VERSION ""

NS_ :

BS_:

BU_: Bat1 OpticalSensor EMUS_BMS SCIMO_PE TelemetryNode Master SensorF SensorR BrakeF BrakeR PDU HVCU HVTU TestBench MDB1 MDB2 MDB3 MDB4 MDB5 MDB6 Track CLU

BO_ 57 CLU_TX_ActionRequest: 1 CLU
 SG_ CLU_TX_ActionRequest : 0|8@1+ (1,0) [0|255] "" Vector__XXX

BO_ 564 CLU_RX_ActionRequest: 1 SensorF
 SG_ CLU_RX_ActionRequest : 0|8@1+ (1,0) [0|255] ""  SensorF

BO_ 2165346838 BMS44_2_Frame: 8 Vector__XXX
 SG_ BMS44_2_FramePayload : 0|64@1+ (1,0) [0|0] ""  SensorF

BO_ 1792 CLU_RX_StatusLedControll: 1 SensorF
 SG_ CLU_RX_ErrorStatus : 0|1@1+ (1,0) [0|1] ""  CLU

BO_ 592 CLU_TX_LevitationState: 1 CLU
 SG_ CLU_LevitationState : 0|8@1+ (1,0) [0|255] ""  SensorF

BO_ 768 CLU_TX_CoolingState: 1 Vector__XXX
 SG_ CLU_RequiresCooling : 0|1@1+ (1,0) [0|1] ""  SensorF

BO_ 274 MDB3_RX_TargetAirGap: 4 CLU
 SG_ MDB3_TargetAirGap : 0|32@1+ (1,0) [0|0] "" Vector__XXX

BO_ 295 MDB6_RX_TargetAirGap: 4 CLU
 SG_ MDB6_TargetAirGap : 0|32@1+ (1,0) [0|0] "" Vector__XXX

BO_ 297 MDB6_TX_Temperature: 4 Vector__XXX
 SG_ MDB6_Temperature : 0|32@1+ (1,0) [0|0] ""  CLU

BO_ 294 MDB6_TX_AirGap: 4 Vector__XXX
 SG_ MDB6_TargetAirGap : 0|32@1+ (1,0) [0|0] ""  CLU

BO_ 293 MDB6_TX_State: 1 Vector__XXX
 SG_ MDB6_State : 0|8@1+ (1,0) [0|255] ""  CLU

BO_ 292 MDB5_TX_Temperature: 4 Vector__XXX
 SG_ MDB5_Temperature : 0|32@1+ (1,0) [0|0] ""  CLU

BO_ 290 MDB5_RX_TargetAirGap: 4 CLU
 SG_ MDB5_TargetAirGap : 0|32@1+ (1,0) [0|0] "" Vector__XXX

BO_ 289 MDB5_TX_AirGap: 4 Vector__XXX
 SG_ MDB5_AirGap : 0|32@1+ (1,0) [0|0] ""  CLU

BO_ 288 MDB5_TX_State: 1 Vector__XXX
 SG_ MDB5_State : 0|8@1+ (1,0) [0|255] ""  CLU

BO_ 281 MDB4_TX_Temperature: 4 Vector__XXX
 SG_ MDB4_Temperature : 0|32@1+ (1,0) [0|0] ""  CLU

BO_ 279 MDB4_RX_TargetAirGap: 4 CLU
 SG_ MDB4_TargetAirGap : 0|32@1+ (1,0) [0|0] "" Vector__XXX

BO_ 278 MDB4_TX_AirGap: 4 Vector__XXX
 SG_ MDB4_AirGap : 0|32@1+ (1,0) [0|0] ""  CLU

BO_ 277 MDB4_TX_State: 1 Vector__XXX
 SG_ MDB4_State : 0|8@1+ (1,0) [0|255] ""  CLU

BO_ 276 MDB3_TX_Temperature: 4 Vector__XXX
 SG_ MDB3_Temperature : 0|32@1+ (1,0) [0|0] ""  CLU

BO_ 273 MDB3_TX_AirGap: 4 Vector__XXX
 SG_ MDB3_AirGap : 0|32@1+ (1,0) [0|0] ""  CLU

BO_ 272 MDB3_TX_State: 1 Vector__XXX
 SG_ MDB3_State : 0|8@1+ (1,0) [0|255] ""  CLU

BO_ 265 MDB2_TX_Temperature: 4 Vector__XXX
 SG_ MDB2_Temperature : 0|32@1+ (1,0) [0|0] ""  CLU

BO_ 263 MDB2_RX_TargetAirGap: 4 CLU
 SG_ MDB2_TargetAirGap : 0|32@1+ (1,0) [0|0] "" Vector__XXX

BO_ 262 MDB2_TX_AirGap: 4 Vector__XXX
 SG_ MDB2_AirGap : 0|32@1+ (1,0) [0|0] ""  CLU

BO_ 261 MDB2_TX_State: 1 Vector__XXX
 SG_ MDB2_State : 0|8@1+ (1,0) [0|255] ""  CLU

BO_ 258 MDB1_RX_TargetAirGap: 4 CLU
 SG_ MDB1_TargetAirGap : 0|32@1+ (1,0) [0|0] "" Vector__XXX

BO_ 260 MDB1_TX_Temperature: 4 MDB3
 SG_ MDB1_Temperature : 0|32@1+ (1,0) [0|0] ""  CLU,SensorF

BO_ 257 MDB1_TX_AirGap: 4 MDB3
 SG_ MDB1_AirGap : 0|32@1+ (1,0) [0|0] ""  CLU

BO_ 1041 BrakeF_TX_PressureCooling: 2 BrakeF
 SG_ BrakeF_TX_Pressure_Reservoir : 0|12@1+ (0.005,-2) [-2|18.475] "bar"  SensorF

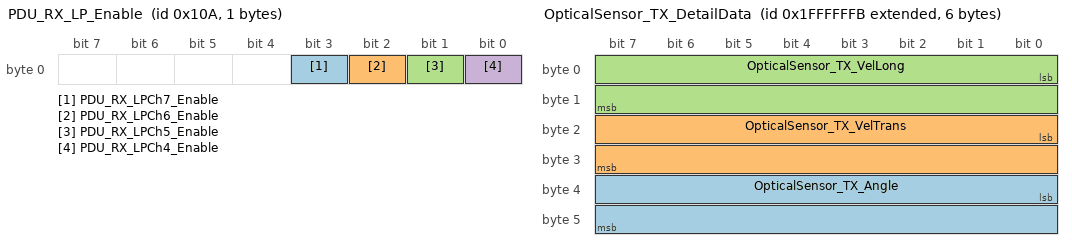
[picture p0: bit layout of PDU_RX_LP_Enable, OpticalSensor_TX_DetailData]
BO_ 266 PDU_RX_LP_Enable: 1 PDU
 SG_ PDU_RX_LPCh7_Enable : 3|1@1+ (1,0) [0|1] ""  SensorF
 SG_ PDU_RX_LPCh6_Enable : 2|1@1+ (1,0) [0|1] ""  SensorF
 SG_ PDU_RX_LPCh5_Enable : 1|1@1+ (1,0) [0|1] ""  SensorF
 SG_ PDU_RX_LPCh4_Enable : 0|1@1+ (1,0) [0|1] ""  SensorF

BO_ 2148592864 BMS44_1_Frame: 8 Bat1
 SG_ BMS44_1_FramePayload : 0|64@1+ (1,0) [0|0] ""  SensorF

BO_ 1 Track_TX_Respond: 1 Track
 SG_ Track_TX_Response : 0|8@1+ (1,0) [0|255] ""  SensorF

BO_ 0 Track_RX_Controll: 1 SensorF
 SG_ Track_RX_Command : 0|8@1+ (1,0) [0|255] "" Vector__XXX

BO_ 512 TEST_GROUND_STATION_CONTROLL: 1 Vector__XXX
 SG_ TEST_GROUND_STATION_COMMAND : 0|8@1+ (1,0) [0|255] ""  SensorF

BO_ 256 MDB1_TX_State: 1 MDB3
 SG_ MDB1_State : 0|8@1+ (1,0) [0|255] ""  CLU,SensorF

BO_ 450 SensorR_RX_POD1: 8 Vector__XXX

BO_ 2684354555 OpticalSensor_TX_DetailData: 6 OpticalSensor
 SG_ OpticalSensor_TX_Angle : 32|16@1- (0.01,0) [-45|45] "ï¿½" Vector__XXX
 SG_ OpticalSensor_TX_VelTrans : 16|16@1- (0.036,0) [-200|200] "km/h" Vector__XXX
 SG_ OpticalSensor_TX_VelLong : 0|16@1+ (0.036,0) [0|400] "km/h" Vector__XXX

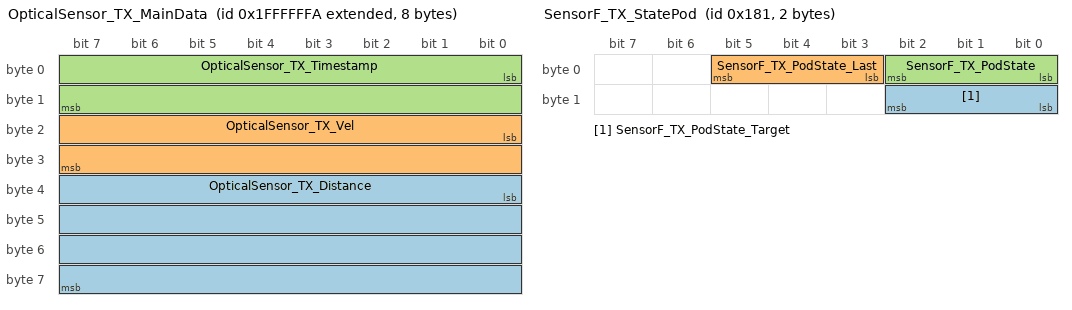
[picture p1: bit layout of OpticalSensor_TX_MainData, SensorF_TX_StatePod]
BO_ 2684354554 OpticalSensor_TX_MainData: 8 OpticalSensor
 SG_ OpticalSensor_TX_Distance : 32|32@1+ (0.001,0) [0|4294970] "m"  SensorF,SensorR
 SG_ OpticalSensor_TX_Vel : 16|16@1+ (0.036,0) [0|400] "km/h"  SensorF,SensorR
 SG_ OpticalSensor_TX_Timestamp : 0|16@1+ (1,0) [0|65535] ""  SensorF,SensorR

BO_ 2684354556 OpticalSensor_TX_Status: 8 OpticalSensor
 SG_ OpticalSensor_TX_VddOK : 62|1@1+ (1,0) [0|0] ""  SensorF
 SG_ OpticalSensor_TX_VeeOK : 61|1@1+ (1,0) [0|0] ""  SensorF
 SG_ OpticalSensor_TX_V33OK : 60|1@1+ (1,0) [0|0] ""  SensorF
 SG_ OpticalSensor_TX_V25OK : 59|1@1+ (1,0) [0|0] ""  SensorF
 SG_ OpticalSensor_TX_LEDStatus : 57|2@1+ (1,0) [0|0] ""  SensorF
 SG_ OpticalSensor_TX_LED_Cal : 56|1@1+ (1,0) [0|0] ""  SensorF
 SG_ OpticalSensor_TX_PowerOK : 55|1@1+ (1,0) [0|0] ""  SensorF
 SG_ OpticalSensor_TX_CurrentOK : 54|1@1+ (1,0) [0|0] ""  SensorF
 SG_ OpticalSensor_TX_CurrentLowHigh : 53|1@1+ (1,0) [0|0] ""  SensorF
 SG_ OpticalSensor_TX_OpticOK : 52|1@1+ (1,0) [0|0] ""  SensorF
 SG_ OpticalSensor_TX_TempOK : 51|1@1+ (1,0) [0|0] ""  SensorF
 SG_ OpticalSensor_TX_SensorOK : 50|1@1+ (1,0) [0|0] ""  SensorF
 SG_ OpticalSensor_TX_SelfTest : 49|1@1+ (1,0) [0|0] ""  SensorF
 SG_ OpticalSensor_TX_STST : 48|1@1+ (1,0) [0|0] ""  SensorF
 SG_ OpticalSensor_TX_LEDCurrent : 40|8@1+ (0.01,0) [0|2.55] "A"  SensorF
 SG_ OpticalSensor_TX_Temp : 32|8@1- (1,0) [-128|127] "ï¿½C"  SensorF
 SG_ OpticalSensor_TX_SensorNo : 24|8@1+ (1,0) [0|0] ""  SensorF
 SG_ OpticalSensor_TX_SerialNo : 0|24@1+ (1,0) [0|0] ""  SensorF

BO_ 2 CANzero_NMT: 4 Master
 SG_ CANzero_NMT_Node : 16|16@1+ (1,0) [0|63] ""  SensorF,SensorR,BrakeF,BrakeR,PDU,HVCU,HVTU,TelemetryNode,MDB1,MDB2,MDB3,MDB4,MDB5,MDB6,Track,CLU
 SG_ CANzero_NMT_State : 0|16@1+ (1,0) [0|0] ""  SensorF,SensorR,BrakeF,BrakeR,PDU,HVCU,HVTU,TelemetryNode,MDB1,MDB2,MDB3,MDB4,MDB5,MDB6,Track,CLU

BO_ 122 CANzero_Sync: 0 Master

BO_ 123 CANzero_Timestamp: 0 Master

BO_ 129 SensorF_EMCY: 4 SensorF
 SG_ SensorF_E14_fiducialHighOffset : 26|1@1+ (1,0) [0|0] ""  Master,TelemetryNode
 SG_ SensorF_E13_encoderSpeedError : 25|1@1+ (1,0) [0|0] ""  Master,TelemetryNode
 SG_ SensorF_E12_encoderError : 24|1@1+ (1,0) [0|0] ""  Master,TelemetryNode
 SG_ SensorF_E10_TelemEmergency : 22|1@1+ (1,0) [0|0] ""  Master,TelemetryNode
 SG_ SensorF_E9_SWError : 21|1@1+ (1,0) [0|0] ""  Master,TelemetryNode
 SG_ SensorF_E8_NodeErrorFlag : 20|1@1+ (1,0) [0|0] ""  Master,TelemetryNode
 SG_ SensorF_E7_TelemetryTimeout : 19|1@1+ (1,0) [0|0] ""  Master,TelemetryNode
 SG_ SensorF_E6_SensorRTimeout : 18|1@1+ (1,0) [0|0] ""  Master,TelemetryNode
 SG_ SensorF_E5_HVCUTimeout : 17|1@1+ (1,0) [0|0] ""  Master,TelemetryNode
 SG_ SensorF_E4_PDUTimeout : 16|1@1+ (1,0) [0|0] ""  Master,TelemetryNode
 SG_ SensorF_E3_BrakeRTimeout : 15|1@1+ (1,0) [0|0] ""  Master,TelemetryNode
 SG_ SensorF_E2_BrakeFTimeout : 14|1@1+ (1,0) [0|0] ""  Master,TelemetryNode
 SG_ SensorF_E1_StateMTransitionE : 13|1@1+ (1,0) [0|0] ""  Master,TelemetryNode
 SG_ SensorF_E0_OtherError : 12|1@1+ (1,0) [0|0] ""  Master,TelemetryNode
 SG_ SensorF_W2_encoderOORWarning : 2|1@1+ (1,0) [0|0] ""  Master,TelemetryNode
 SG_ SensorF_W1_StateMTransitionW : 1|1@1+ (1,0) [0|0] ""  Master,TelemetryNode
 SG_ SensorF_W0_OtherWarning : 0|1@1+ (1,0) [0|0] ""  Master,TelemetryNode

BO_ 385 SensorF_TX_StatePod: 2 SensorF
 SG_ SensorF_TX_PodState_Target : 8|3@1+ (1,0) [0|0] ""  CLU,Track,BrakeF,PDU
 SG_ SensorF_TX_PodState_Last : 3|3@1+ (1,0) [0|0] ""  CLU,Track,BrakeF,PDU
 SG_ SensorF_TX_PodState : 0|3@1+ (1,0) [0|0] ""  CLU,Track,BrakeF,PDU

BO_ 449 SensorF_RX_PDO1: 0 Vector__XXX

BO_ 513 SensorF_TX_FSMTransitions: 4 SensorF
 SG_ SensorF_TX_PreopHVCUT : 24|1@1+ (1,0) [0|0] "" Vector__XXX
 SG_ SensorF_TX_PreopPDUT : 16|1@1+ (1,0) [0|0] "" Vector__XXX
 SG_ SensorF_TX_PreopBrakeRT : 15|1@1+ (1,0) [0|0] "" Vector__XXX
 SG_ SensorF_TX_PreopBrakeFT : 14|1@1+ (1,0) [0|0] "" Vector__XXX
 SG_ SensorF_TX_PreopSensorRT : 13|1@1+ (1,0) [0|0] "" Vector__XXX
 SG_ SensorF_TX_EnableSensorRT : 12|1@1+ (1,0) [0|0] "" Vector__XXX
 SG_ SensorF_TX_EnablePDUT : 11|1@1+ (1,0) [0|0] "" Vector__XXX
 SG_ SensorF_TX_EnableHVCUT : 10|1@1+ (1,0) [0|0] "" Vector__XXX
 SG_ SensorF_TX_EnableBrakeRT : 9|1@1+ (1,0) [0|0] "" Vector__XXX
 SG_ SensorF_TX_EnableBrakeFT : 8|1@1+ (1,0) [0|0] "" Vector__XXX
 SG_ SensorF_TX_SetHVTransition : 7|1@1+ (1,0) [0|0] "" Vector__XXX
 SG_ SensorF_TX_PreopTransition : 6|1@1+ (1,0) [0|0] "" Vector__XXX
 SG_ SensorF_TX_LaunchStartTransition : 5|1@1+ (1,0) [0|0] "" Vector__XXX
 SG_ SensorF_TX_LaunchSetupTransition : 4|1@1+ (1,0) [0|0] "" Vector__XXX
 SG_ SensorF_TX_HWEnableTransition : 3|1@1+ (1,0) [0|0] "" Vector__XXX
 SG_ SensorF_TX_ErrorResetTransition : 2|1@1+ (1,0) [0|0] "" Vector__XXX
 SG_ SensorF_TX_EnableTransition : 1|1@1+ (1,0) [0|0] "" Vector__XXX
 SG_ SensorF_TX_BrakesTransition : 0|1@1+ (1,0) [0|0] "" Vector__XXX

BO_ 577 SensorF_RX_PDO2: 0 Vector__XXX

BO_ 641 SensorF_TX_PDO3: 0 SensorF

BO_ 705 SensorF_RX_PDO3: 0 Vector__XXX

BO_ 769 SensorF_TX_PDO4: 0 SensorF

BO_ 833 SensorF_RX_PDO4: 0 Vector__XXX

BO_ 897 SensorF_TX_PDO5: 0 SensorF

BO_ 961 SensorF_TX_PDO6: 0 SensorF

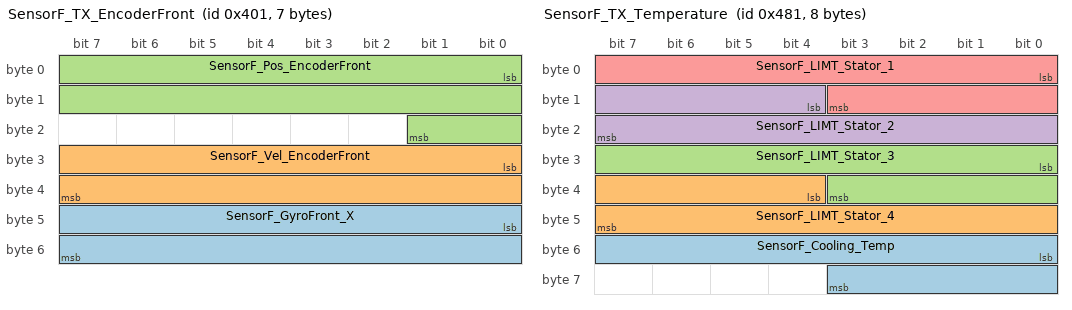
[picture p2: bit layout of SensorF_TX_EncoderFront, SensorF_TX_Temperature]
BO_ 1025 SensorF_TX_EncoderFront: 7 SensorF
 SG_ SensorF_GyroFront_X : 40|16@1- (0.017,0) [-557.056|557.039] "Â°/s"  SensorR
 SG_ SensorF_Vel_EncoderFront : 24|16@1- (0.002,0) [-65.536|65.534] "m/s"  SensorR
 SG_ SensorF_Pos_EncoderFront : 0|18@1- (0.005,0) [-655.36|655.355] "m"  SensorR

BO_ 1089 SensorF_TX_BMS: 2 SensorF
 SG_ SensorF_TX_BatteryTemp : 0|12@1+ (0.05,-30) [-30|174.75] "C"  PDU

BO_ 1153 SensorF_TX_Temperature: 8 SensorF
 SG_ SensorF_Cooling_Temp : 48|12@1+ (0.05,-30) [-30|174.75] "C"  PDU
 SG_ SensorF_LIMT_Stator_4 : 36|12@1+ (0.075,-20) [-20|287.125] "ï¿½C" Vector__XXX
 SG_ SensorF_LIMT_Stator_3 : 24|12@1+ (0.075,-20) [-20|287.125] "ï¿½C" Vector__XXX
 SG_ SensorF_LIMT_Stator_2 : 12|12@1+ (0.075,-20) [-20|287.125] "ï¿½C" Vector__XXX
 SG_ SensorF_LIMT_Stator_1 : 0|12@1+ (0.075,-20) [-20|287.125] "ï¿½C" Vector__XXX

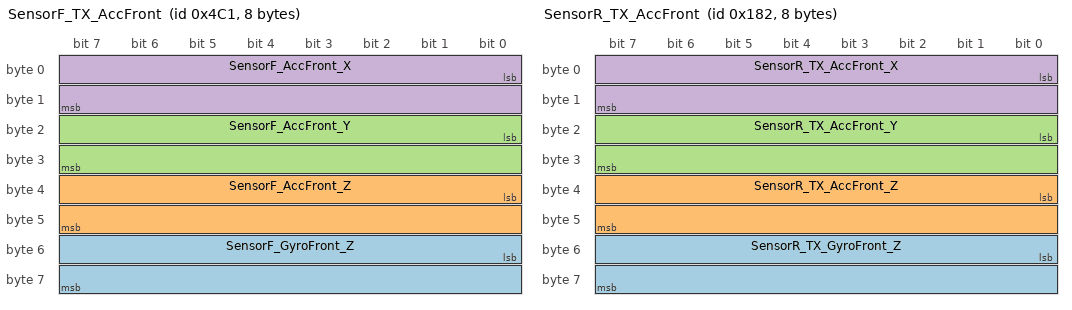
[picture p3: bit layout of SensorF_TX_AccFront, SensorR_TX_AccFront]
BO_ 1217 SensorF_TX_AccFront: 8 SensorF
 SG_ SensorF_GyroFront_Z : 48|16@1- (0.017,0) [-557.056|557.039] "Â°/s"  SensorR
 SG_ SensorF_AccFront_Z : 32|16@1- (0.00125,0) [-40.96|40.95875] "m/s^2"  SensorR
 SG_ SensorF_AccFront_Y : 16|16@1- (0.00125,0) [-40.96|40.95875] "m/s^2"  SensorR
 SG_ SensorF_AccFront_X : 0|16@1- (0.00125,0) [-40.96|40.95875] "m/s^2"  SensorR

BO_ 1281 SensorF_TX_PDO11: 0 SensorF

BO_ 1345 SensorF_TX_PDO12: 0 SensorF

BO_ 1409 SensorF_SDO_Resp: 8 SensorF
 SG_ SensorF_OD_SetReset m2320 : 16|8@1+ (1,0) [0|255] ""  TelemetryNode
 SG_ SensorF_OD_Velocity m3329 : 16|16@1+ (0.01,-100) [-100|555.35] ""  TelemetryNode
 SG_ SensorF_OD_Position m3328 : 16|16@1+ (0.01,-100) [-100|555.35] ""  TelemetryNode
 SG_ SensorF_OD_StripeCount m3072 : 16|16@1+ (1,0) [0|65535] ""  TelemetryNode
 SG_ SensorF_OD_MdbState m2832 : 16|8@1+ (1,0) [0|255] ""  TelemetryNode
 SG_ SensorF_OD_Magnet_6_Temperature m2824 : 16|16@1+ (0.01,-100) [-100|555.35] ""  TelemetryNode
 SG_ SensorF_OD_Magnet_5_Temperature m2823 : 16|16@1+ (0.01,-100) [-100|555.35] ""  TelemetryNode
 SG_ SensorF_OD_Magnet_4_Temperature m2822 : 16|16@1+ (0.01,-100) [-100|555.35] ""  TelemetryNode
 SG_ SensorF_OD_Magnet_3_Temperature m2821 : 16|16@1+ (0.01,-100) [-100|555.35] ""  TelemetryNode
 SG_ SensorF_OD_Magnet_2_Temperature m2820 : 16|16@1+ (0.01,-100) [-100|555.35] ""  TelemetryNode
 SG_ SensorF_OD_Magnet_1_Temperature m2818 : 16|16@1+ (0.01,-100) [-100|555.35] ""  TelemetryNode
 SG_ SensorF_OD_ReservoirTemperature m2817 : 16|16@1+ (0.01,-100) [-100|555.35] ""  TelemetryNode
 SG_ SensorF_OD_CoolingPressure m2816 : 16|16@1+ (0.01,-100) [-100|555.35] ""  TelemetryNode
 SG_ SensorF_OD_IMU_GyroZ m2611 : 16|16@1+ (0.01,-100) [-100|555.35] ""  TelemetryNode
 SG_ SensorF_OD_IMU_GyroY m2610 : 16|16@1+ (0.01,-100) [-100|555.35] ""  TelemetryNode
 SG_ SensorF_OD_IMU_GyroX m2609 : 16|16@1+ (0.01,-100) [-100|555.35] ""  TelemetryNode
 SG_ SensorF_OD_IMU_AccelZ m2608 : 16|16@1+ (0.01,-100) [-100|555.35] ""  TelemetryNode
 SG_ SensorF_OD_IMU_AccelY m2601 : 16|16@1+ (0.01,-100) [-100|555.35] ""  TelemetryNode
 SG_ SensorF_OD_IMU_AccelX m2600 : 16|16@1+ (0.01,-100) [-100|555.35] ""  TelemetryNode
 SG_ SensorF_OD_IMU3_Temperature m2599 : 16|16@1+ (0.01,-100) [-100|555.35] ""  TelemetryNode
 SG_ SensorF_OD_IMU2_Temperature m2598 : 16|16@1+ (0.01,-100) [-100|555.35] ""  TelemetryNode
 SG_ SensorF_OD_IMU1_Temperature m2597 : 16|16@1+ (0.01,-100) [-100|555.35] ""  TelemetryNode
 SG_ SensorF_OD_IMU_number m2592 : 16|8@1+ (1,0) [0|255] ""  TelemetryNode
 SG_ SensorF_OD_EncoderResetPosition m2309 : 16|8@1+ (1,0) [0|255] ""  TelemetryNode
 SG_ SensorF_OD_EncoderWheelDiameter m2308 : 16|16@1+ (0.005,0) [1|300] "mm"  TelemetryNode
 SG_ SensorF_OD_HVBatteryMode m2307 : 16|8@1+ (1,0) [0|255] ""  TelemetryNode
 SG_ SensorF_OD_StateMachineActivate m2306 : 16|8@1+ (1,0) [0|255] ""  TelemetryNode
 SG_ SensorF_OD_StateMachineInterval m2305 : 16|8@1+ (1,0) [5|100] "ms"  TelemetryNode
 SG_ SensorF_OD_TelemetryCommands m2304 : 16|8@1+ (1,0) [0|255] ""  TelemetryNode
 SG_ SensorF_OD_samplingInterval m2048 : 16|16@1+ (0.01,0) [0.01|100] "ms"  TelemetryNode
 SG_ SensorF_OD_CAN2_DelayedTxMessage m1129 : 16|24@1+ (1,0) [0|16777215] ""  TelemetryNode
 SG_ SensorF_OD_CAN2_ErrorStatus m1128 : 16|8@1+ (1,0) [0|255] ""  TelemetryNode
 SG_ SensorF_OD_CAN2_DiscardedTxMessa m1127 : 16|24@1+ (1,0) [0|16777215] ""  TelemetryNode
 SG_ SensorF_OD_CAN2_Status m1126 : 16|8@1+ (1,0) [0|255] ""  TelemetryNode
 SG_ SensorF_OD_CAN2_Baudrate m1124 : 16|16@1+ (1,0) [125|1000] "kbps"  TelemetryNode
 SG_ SensorF_OD_CAN2_autoErrorReset m1123 : 16|8@1+ (1,0) [0|255] ""  TelemetryNode
 SG_ SensorF_OD_CAN2_lastErrorCode m1122 : 16|32@1+ (1,0) [0|4294967295] ""  TelemetryNode
 SG_ SensorF_OD_CAN2_RxErrCnt m1121 : 16|8@1+ (1,0) [0|255] ""  TelemetryNode
 SG_ SensorF_OD_CAN2_TxErrCnt m1120 : 16|8@1+ (1,0) [0|255] ""  TelemetryNode
 SG_ SensorF_OD_CAN1_DelayedTxMessage m1113 : 16|24@1+ (1,0) [0|16777215] ""  TelemetryNode
 SG_ SensorF_OD_CAN1_ErrorStatus m1112 : 16|8@1+ (1,0) [0|255] ""  TelemetryNode
 SG_ SensorF_OD_CAN1_DiscardedTxMessa m1111 : 16|24@1+ (1,0) [0|16777215] ""  TelemetryNode
 SG_ SensorF_OD_CAN1_Status m1110 : 16|8@1+ (1,0) [0|255] ""  TelemetryNode
 SG_ SensorF_OD_CAN1_Baudrate m1108 : 16|16@1+ (1,0) [125|1000] "kbps"  TelemetryNode
 SG_ SensorF_OD_CAN1_autoErrorReset m1107 : 16|8@1+ (1,0) [0|255] ""  TelemetryNode
 SG_ SensorF_OD_CAN1_lastErrorCode m1106 : 16|32@1+ (1,0) [0|4294967295] ""  TelemetryNode
 SG_ SensorF_OD_CAN1_RxErrCnt m1105 : 16|8@1+ (1,0) [0|255] ""  TelemetryNode
 SG_ SensorF_OD_CAN1_TxErrCnt m1104 : 16|8@1+ (1,0) [0|255] ""  TelemetryNode
 SG_ SensorF_OD_BuildTime m1073 : 16|24@1+ (1,0) [0|16777215] ""  TelemetryNode
 SG_ SensorF_OD_BuildDate m1072 : 16|32@1+ (1,0) [0|4294967295] ""  TelemetryNode
 SG_ SensorF_OD_ChipUID2 m1057 : 16|48@1+ (1,0) [0|281474976710655] ""  TelemetryNode
 SG_ SensorF_OD_ChipUID1 m1056 : 16|48@1+ (1,0) [0|281474976710655] ""  TelemetryNode
 SG_ SensorF_OD_SdcOut m1046 : 16|8@1+ (1,0) [0|255] ""  TelemetryNode
 SG_ SensorF_OD_SdcIn m1045 : 16|8@1+ (1,0) [0|255] ""  TelemetryNode
 SG_ SensorF_OD_runtime m1044 : 16|24@1+ (1,0) [0|16777215] "ms"  TelemetryNode
 SG_ SensorF_OD_InputVoltage m1043 : 16|16@1+ (0.001,0) [0|65.535] "V"  TelemetryNode
 SG_ SensorF_OD_BoardTemp m1042 : 16|16@1+ (0.01,-30) [-30|625.35] "°C"  TelemetryNode
 SG_ SensorF_OD_MemFree m1041 : 16|16@1+ (4,0) [0|262140] "bytes"  TelemetryNode
 SG_ SensorF_OD_CpuUsage m1040 : 16|8@1+ (0.5,0) [0|100] "%"  TelemetryNode
 SG_ SensorF_OD_OdEntrySendInterval m33 : 16|16@1+ (1,0) [0|65535] "ms"  TelemetryNode
 SG_ SensorF_OD_SendOdOnBootup m32 : 16|8@1+ (1,0) [0|255] ""  TelemetryNode
 SG_ SensorF_OD_HeartbeatInterval m16 : 16|16@1+ (1,0) [0|65535] "ms"  TelemetryNode
 SG_ SensorF_OD_DbcVersion m5 : 16|16@1+ (1,0) [0|65535] ""  TelemetryNode
 SG_ SensorF_OD_StackVersion m4 : 16|16@1+ (1,0) [0|65535] ""  TelemetryNode
 SG_ SensorF_OD_ProtocolVersion m3 : 16|16@1+ (1,0) [0|65535] ""  TelemetryNode
 SG_ SensorF_OD_NodeStatus m2 : 16|8@1+ (1,0) [0|255] ""  TelemetryNode
 SG_ SensorF_OD_NodeID m1 : 16|8@1+ (1,0) [0|255] ""  TelemetryNode
 SG_ SensorF_SDO_RespCode : 12|4@1+ (1,0) [0|0] ""  TelemetryNode
 SG_ SensorF_SDO_ID M : 0|12@1+ (1,0) [0|4095] ""  TelemetryNode

BO_ 1473 SensorF_SDO_Req_Up: 8 TelemetryNode
 SG_ SensorF_OD_SetReset m2320 : 16|8@1+ (1,0) [0|255] ""  SensorF
 SG_ SensorF_OD_Velocity m3329 : 16|16@1+ (0.01,-100) [-100|555.35] ""  SensorF
 SG_ SensorF_OD_Position m3328 : 16|16@1+ (0.01,-100) [-100|555.35] ""  SensorF
 SG_ SensorF_OD_StripeCount m3072 : 16|16@1+ (1,0) [0|65535] ""  SensorF
 SG_ SensorF_OD_MdbState m2832 : 16|8@1+ (1,0) [0|255] ""  SensorF
 SG_ SensorF_OD_Magnet_6_Temperature m2824 : 16|16@1+ (0.01,-100) [-100|555.35] ""  SensorF
 SG_ SensorF_OD_Magnet_5_Temperature m2823 : 16|16@1+ (0.01,-100) [-100|555.35] ""  SensorF
 SG_ SensorF_OD_Magnet_4_Temperature m2822 : 16|16@1+ (0.01,-100) [-100|555.35] ""  SensorF
 SG_ SensorF_OD_Magnet_3_Temperature m2821 : 16|16@1+ (0.01,-100) [-100|555.35] ""  SensorF
 SG_ SensorF_OD_Magnet_2_Temperature m2820 : 16|16@1+ (0.01,-100) [-100|555.35] ""  SensorF
 SG_ SensorF_OD_Magnet_1_Temperature m2818 : 16|16@1+ (0.01,-100) [-100|555.35] ""  SensorF
 SG_ SensorF_OD_ReservoirTemperature m2817 : 16|16@1+ (0.01,-100) [-100|555.35] ""  SensorF
 SG_ SensorF_OD_CoolingPressure m2816 : 16|16@1+ (0.01,-100) [-100|555.35] ""  SensorF
 SG_ SensorF_OD_IMU_GyroZ m2611 : 16|16@1+ (0.01,-100) [-100|555.35] ""  SensorF
 SG_ SensorF_OD_IMU_GyroY m2610 : 16|16@1+ (0.01,-100) [-100|555.35] ""  SensorF
 SG_ SensorF_OD_IMU_GyroX m2609 : 16|16@1+ (0.01,-100) [-100|555.35] ""  SensorF
 SG_ SensorF_OD_IMU_AccelZ m2608 : 16|16@1+ (0.01,-100) [-100|555.35] ""  SensorF
 SG_ SensorF_OD_IMU_AccelY m2601 : 16|16@1+ (0.01,-100) [-100|555.35] ""  SensorF
 SG_ SensorF_OD_IMU_AccelX m2600 : 16|16@1+ (0.01,-100) [-100|555.35] ""  SensorF
 SG_ SensorF_OD_IMU3_Temperature m2599 : 16|16@1+ (0.01,-100) [-100|555.35] ""  SensorF
 SG_ SensorF_OD_IMU2_Temperature m2598 : 16|16@1+ (0.01,-100) [-100|555.35] ""  SensorF
 SG_ SensorF_OD_IMU1_Temperature m2597 : 16|16@1+ (0.01,-100) [-100|555.35] ""  SensorF
 SG_ SensorF_OD_IMU_number m2592 : 16|8@1+ (1,0) [0|255] ""  SensorF
 SG_ SensorF_OD_EncoderResetPosition m2309 : 16|8@1+ (1,0) [0|255] ""  SensorF
 SG_ SensorF_OD_EncoderWheelDiameter m2308 : 16|16@1+ (0.005,0) [1|300] "mm"  SensorF
 SG_ SensorF_OD_HVBatteryMode m2307 : 16|8@1+ (1,0) [0|255] ""  SensorF
 SG_ SensorF_OD_StateMachineActivate m2306 : 16|8@1+ (1,0) [0|255] ""  SensorF
 SG_ SensorF_OD_StateMachineInterval m2305 : 16|8@1+ (1,0) [5|100] "ms"  SensorF
 SG_ SensorF_OD_TelemetryCommands m2304 : 16|8@1+ (1,0) [0|255] ""  SensorF
 SG_ SensorF_OD_samplingInterval m2048 : 16|16@1+ (0.01,0) [0.01|100] "ms"  SensorF
 SG_ SensorF_OD_CAN2_DelayedTxMe_0000 m1129 : 16|24@1+ (1,0) [0|16777215] ""  SensorF
 SG_ SensorF_OD_CAN2_ErrorStatus m1128 : 16|8@1+ (1,0) [0|255] ""  SensorF
 SG_ SensorF_OD_CAN2_DiscardedTx_0000 m1127 : 16|24@1+ (1,0) [0|16777215] ""  SensorF
 SG_ SensorF_OD_CAN2_Status m1126 : 16|8@1+ (1,0) [0|255] ""  SensorF
 SG_ SensorF_OD_CAN2_Baudrate m1124 : 16|16@1+ (1,0) [125|1000] "kbps"  SensorF
 SG_ SensorF_OD_CAN2_autoErrorReset m1123 : 16|8@1+ (1,0) [0|255] ""  SensorF
 SG_ SensorF_OD_CAN2_lastErrorCode m1122 : 16|32@1+ (1,0) [0|4294967295] ""  SensorF
 SG_ SensorF_OD_CAN2_RxErrCnt m1121 : 16|8@1+ (1,0) [0|255] ""  SensorF
 SG_ SensorF_OD_CAN2_TxErrCnt m1120 : 16|8@1+ (1,0) [0|255] ""  SensorF
 SG_ SensorF_OD_CAN1_DelayedTxMe_0000 m1113 : 16|24@1+ (1,0) [0|16777215] ""  SensorF
 SG_ SensorF_OD_CAN1_ErrorStatus m1112 : 16|8@1+ (1,0) [0|255] ""  SensorF
 SG_ SensorF_OD_CAN1_DiscardedTx_0000 m1111 : 16|24@1+ (1,0) [0|16777215] ""  SensorF
 SG_ SensorF_OD_CAN1_Status m1110 : 16|8@1+ (1,0) [0|255] ""  SensorF
 SG_ SensorF_OD_CAN1_Baudrate m1108 : 16|16@1+ (1,0) [125|1000] "kbps"  SensorF
 SG_ SensorF_OD_CAN1_autoErrorReset m1107 : 16|8@1+ (1,0) [0|255] ""  SensorF
 SG_ SensorF_OD_CAN1_lastErrorCode m1106 : 16|32@1+ (1,0) [0|4294967295] ""  SensorF
 SG_ SensorF_OD_CAN1_RxErrCnt m1105 : 16|8@1+ (1,0) [0|255] ""  SensorF
 SG_ SensorF_OD_CAN1_TxErrCnt m1104 : 16|8@1+ (1,0) [0|255] ""  SensorF
 SG_ SensorF_OD_BuildTime m1073 : 16|24@1+ (1,0) [0|16777215] ""  SensorF
 SG_ SensorF_OD_BuildDate m1072 : 16|32@1+ (1,0) [0|4294967295] ""  SensorF
 SG_ SensorF_OD_ChipUID2 m1057 : 16|48@1+ (1,0) [0|281474976710655] ""  SensorF
 SG_ SensorF_OD_ChipUID1 m1056 : 16|48@1+ (1,0) [0|281474976710655] ""  SensorF
 SG_ SensorF_OD_SdcOut m1046 : 16|8@1+ (1,0) [0|255] ""  SensorF
 SG_ SensorF_OD_SdcIn m1045 : 16|8@1+ (1,0) [0|255] ""  SensorF
 SG_ SensorF_OD_runtime m1044 : 16|24@1+ (1,0) [0|16777215] "ms"  SensorF
 SG_ SensorF_OD_InputVoltage m1043 : 16|16@1+ (0.001,0) [0|65.535] "V"  SensorF
 SG_ SensorF_OD_BoardTemp m1042 : 16|16@1+ (0.01,-30) [-30|625.35] "°C"  SensorF
 SG_ SensorF_OD_MemFree m1041 : 16|16@1+ (4,0) [0|262140] "bytes"  SensorF
 SG_ SensorF_OD_CpuUsage m1040 : 16|8@1+ (0.5,0) [0|100] "%"  SensorF
 SG_ SensorF_OD_OdEntrySendInterval m33 : 16|16@1+ (1,0) [0|65535] "ms"  SensorF
 SG_ SensorF_OD_SendOdOnBootup m32 : 16|8@1+ (1,0) [0|255] ""  SensorF
 SG_ SensorF_OD_HeartbeatInterval m16 : 16|16@1+ (1,0) [0|65535] "ms"  SensorF
 SG_ SensorF_OD_DbcVersion m5 : 16|16@1+ (1,0) [0|65535] ""  SensorF
 SG_ SensorF_OD_StackVersion m4 : 16|16@1+ (1,0) [0|65535] ""  SensorF
 SG_ SensorF_OD_ProtocolVersion m3 : 16|16@1+ (1,0) [0|65535] ""  SensorF
 SG_ SensorF_OD_NodeStatus m2 : 16|8@1+ (1,0) [0|255] ""  SensorF
 SG_ SensorF_OD_NodeID m1 : 16|8@1+ (1,0) [0|255] ""  SensorF
 SG_ SensorF_SDO_ID M : 0|12@1+ (1,0) [0|4095] ""  SensorF

BO_ 1537 SensorF_SDO_Req_Down: 2 TelemetryNode
 SG_ SensorF_SDO_ID M : 0|12@1+ (1,0) [0|4095] ""  SensorF

BO_ 1793 SensorF_Heartbeat: 1 SensorF
 SG_ SensorF_NodeState : 0|8@1+ (1,0) [0|0] ""  SensorF,Master,TelemetryNode

BO_ 1857 SensorF_BTL_TX: 8 SensorF

BO_ 1921 SensorF_BTL_RX: 8 TelemetryNode

BO_ 130 SensorR_EMCY: 4 SensorR
 SG_ SensorR_E12_highLIMTemperature : 24|1@1+ (1,0) [0|0] ""  Master,TelemetryNode
 SG_ SensorR_E11_scimoPEerror101overc : 23|1@1+ (1,0) [0|0] ""  Master,TelemetryNode
 SG_ SensorR_E10_scimoPEerror103sumcu : 22|1@1+ (1,0) [0|0] ""  Master,TelemetryNode
 SG_ SensorR_E9_scimoPEerror102overcu : 21|1@1+ (1,0) [0|0] ""  Master,TelemetryNode
 SG_ SensorR_E8_scimoPEerror024motTem : 20|1@1+ (1,0) [0|0] ""  Master,TelemetryNode
 SG_ SensorR_E7_scimoPEerror020uZKmin : 19|1@1+ (1,0) [0|0] ""  Master,TelemetryNode
 SG_ SensorR_E6_scimoPEerror009Pulslo : 18|1@1+ (1,0) [0|0] ""  Master,TelemetryNode
 SG_ SensorR_E5_accEmergencyStop : 17|1@1+ (1,0) [0|0] ""  Master,TelemetryNode
 SG_ SensorR_E4_velEmergencyStop : 16|1@1+ (1,0) [0|0] ""  Master,TelemetryNode
 SG_ SensorR_E3_posEmergencyStop : 15|1@1+ (1,0) [0|0] ""  Master,TelemetryNode
 SG_ SensorR_E2_stripeEmergencyStop : 14|1@1+ (1,0) [0|0] ""  Master,TelemetryNode
 SG_ SensorR_E1_trajectoryError : 13|1@1+ (1,0) [0|0] ""  Master,TelemetryNode
 SG_ SensorR_E0_OtherError : 12|1@1+ (1,0) [0|0] ""  Master,TelemetryNode
 SG_ SensorR_W10_highLIMTemperature : 10|1@1+ (1,0) [0|0] ""  Master,TelemetryNode
 SG_ SensorR_W9_restrictingVelocity : 9|1@1+ (1,0) [0|0] ""  Master,TelemetryNode
 SG_ SensorR_W8_outOfLimModelBoundari : 8|1@1+ (1,0) [0|0] ""  Master,TelemetryNode
 SG_ SensorR_W7_highOscillations : 7|1@1+ (1,0) [0|0] ""  Master,TelemetryNode
 SG_ SensorR_W6_sciMoPEwarning104FETt : 6|1@1+ (1,0) [0|0] ""  Master,TelemetryNode
 SG_ SensorR_W5_sciMoPEwarning069CPUt : 5|1@1+ (1,0) [0|0] ""  Master,TelemetryNode
 SG_ SensorR_W4_stateEstimationAccWar : 4|1@1+ (1,0) [0|0] ""  Master,TelemetryNode
 SG_ SensorR_W3_stateEstimationPosWar : 3|1@1+ (1,0) [0|0] ""  Master,TelemetryNode
 SG_ SensorR_W2_stateEstimationVelWar : 2|1@1+ (1,0) [0|0] ""  Master,TelemetryNode
 SG_ SensorR_W1_stripeWarning : 1|1@1+ (1,0) [0|0] ""  Master,TelemetryNode
 SG_ SensorR_W0_OtherWarning : 0|1@1+ (1,0) [0|0] ""  Master,TelemetryNode

BO_ 386 SensorR_TX_AccFront: 8 SensorR
 SG_ SensorR_TX_GyroFront_Z : 48|16@1- (0.017,0) [-557.056|557.039] "Â°/s" Vector__XXX
 SG_ SensorR_TX_AccFront_Z : 32|16@1- (0.00125,0) [-40.96|40.95875] "m/s^2" Vector__XXX
 SG_ SensorR_TX_AccFront_Y : 16|16@1- (0.00125,0) [-40.96|40.95875] "m/s^2" Vector__XXX
 SG_ SensorR_TX_AccFront_X : 0|16@1- (0.00125,0) [-40.96|40.95875] "m/s^2" Vector__XXX

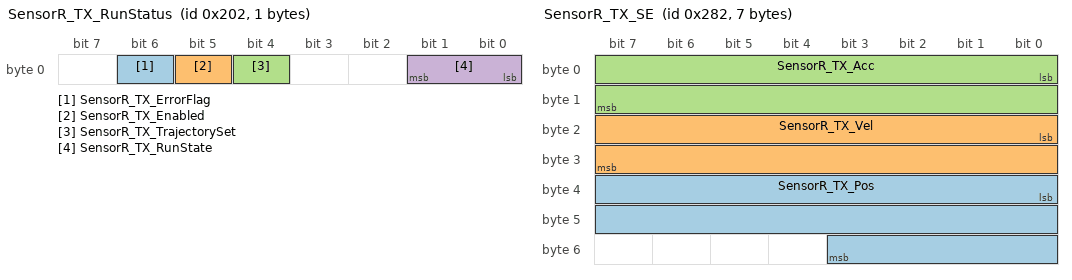
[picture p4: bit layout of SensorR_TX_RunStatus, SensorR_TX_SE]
BO_ 514 SensorR_TX_RunStatus: 1 SensorR
 SG_ SensorR_TX_ErrorFlag : 6|1@1+ (1,0) [0|0] "" Vector__XXX
 SG_ SensorR_TX_Enabled : 5|1@1+ (1,0) [0|0] "" Vector__XXX
 SG_ SensorR_TX_TrajectorySet : 4|1@1+ (1,0) [0|0] "" Vector__XXX
 SG_ SensorR_TX_RunState : 0|2@1+ (1,0) [0|0] ""  PDU

BO_ 578 SensorR_RX_PDO2: 0 Vector__XXX

BO_ 642 SensorR_TX_SE: 7 SensorR
 SG_ SensorR_TX_Pos : 32|20@1- (0.001,0) [-524.288|524.287] "m"  PDU,TelemetryNode
 SG_ SensorR_TX_Vel : 16|16@1- (0.002,0) [-65.536|65.534] "m/s"  PDU,TelemetryNode
 SG_ SensorR_TX_Acc : 0|16@1- (0.00125,0) [-40.96|40.95875] "m/s^2"  PDU,TelemetryNode

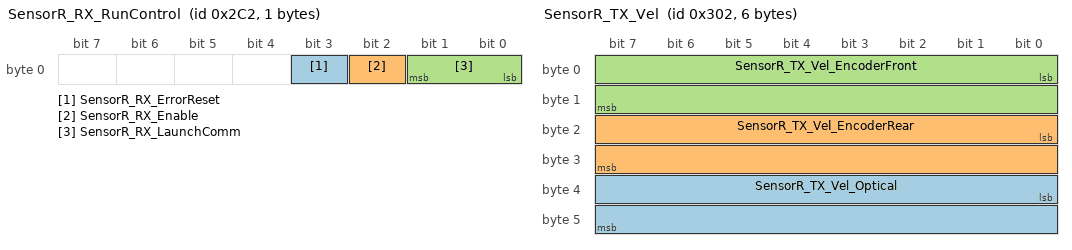
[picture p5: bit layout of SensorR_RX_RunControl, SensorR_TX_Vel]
BO_ 706 SensorR_RX_RunControl: 1 SensorF
 SG_ SensorR_RX_ErrorReset : 3|1@1+ (1,0) [0|0] "" Vector__XXX
 SG_ SensorR_RX_Enable : 2|1@1+ (1,0) [0|0] "" Vector__XXX
 SG_ SensorR_RX_LaunchComm : 0|2@1+ (1,0) [0|0] "" Vector__XXX

BO_ 770 SensorR_TX_Vel: 6 SensorR
 SG_ SensorR_TX_Vel_Optical : 32|16@1- (0.002,0) [-65.536|65.534] "m/s" Vector__XXX
 SG_ SensorR_TX_Vel_EncoderRear : 16|16@1- (0.002,0) [-65.536|65.534] "m/s" Vector__XXX
 SG_ SensorR_TX_Vel_EncoderFront : 0|16@1- (0.002,0) [-65.536|65.534] "m/s" Vector__XXX

BO_ 834 SensorR_RX_PDO4: 0 Vector__XXX

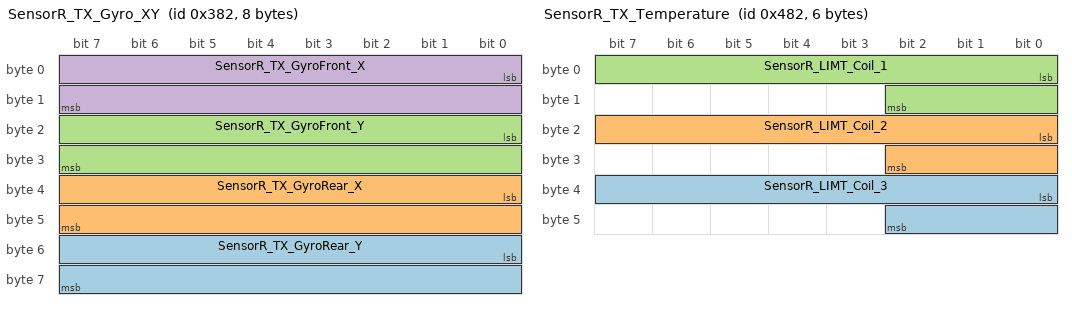
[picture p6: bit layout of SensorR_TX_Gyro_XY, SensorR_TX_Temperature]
BO_ 898 SensorR_TX_Gyro_XY: 8 SensorR
 SG_ SensorR_TX_GyroRear_Y : 48|16@1- (0.017,0) [-557.056|557.039] "Â°/s" Vector__XXX
 SG_ SensorR_TX_GyroRear_X : 32|16@1- (0.017,0) [-557.056|557.039] "Â°/s" Vector__XXX
 SG_ SensorR_TX_GyroFront_Y : 16|16@1- (0.017,0) [-557.056|557.039] "Â°/s" Vector__XXX
 SG_ SensorR_TX_GyroFront_X : 0|16@1- (0.017,0) [-557.056|557.039] "Â°/s" Vector__XXX

BO_ 962 SensorR_TX_TargetValues: 2 SensorR
 SG_ SensorR_TX_TargetVelocity : 0|14@1- (0.01,0) [-81.92|81.91] "m/s" Vector__XXX

BO_ 1026 SensorR_TX_GapHeight: 4 SensorR
 SG_ SensorR_TX_GapHeight_Right : 12|12@1- (0.0125,0) [-25.6|25.5875] "mm" Vector__XXX
 SG_ SensorR_TX_GapHeight_Left : 0|12@1- (0.0125,0) [-25.6|25.5875] "mm" Vector__XXX

BO_ 1090 SensorR_TX_PDO8: 0 SensorR

BO_ 1154 SensorR_TX_Temperature: 6 SensorR
 SG_ SensorR_LIMT_Coil_3 : 32|11@1+ (0.1,-5) [-5|199.7] "ï¿½C"  PDU
 SG_ SensorR_LIMT_Coil_2 : 16|11@1+ (0.1,-5) [-5|199.7] "ï¿½C"  PDU
 SG_ SensorR_LIMT_Coil_1 : 0|11@1+ (0.1,-5) [-5|199.7] "ï¿½C"  PDU

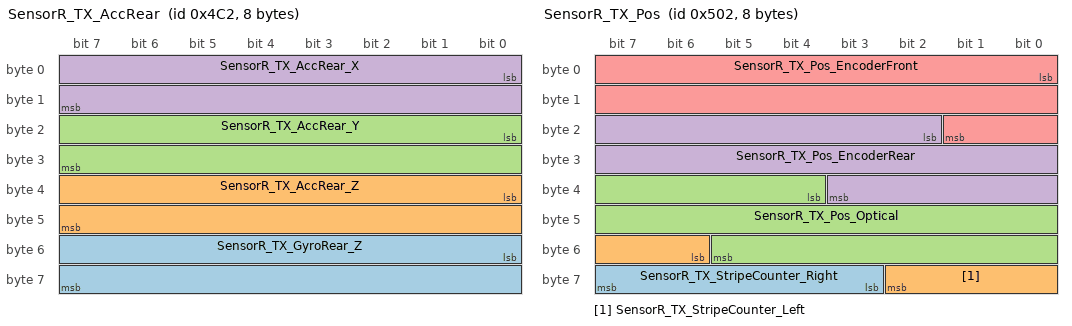
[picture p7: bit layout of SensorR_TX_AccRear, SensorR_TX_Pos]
BO_ 1218 SensorR_TX_AccRear: 8 SensorR
 SG_ SensorR_TX_GyroRear_Z : 48|16@1- (0.017,0) [-557.056|557.039] "Â°/s" Vector__XXX
 SG_ SensorR_TX_AccRear_Z : 32|16@1- (0.00125,0) [-40.96|40.95875] "m/s^2" Vector__XXX
 SG_ SensorR_TX_AccRear_Y : 16|16@1- (0.00125,0) [-40.96|40.95875] "m/s^2" Vector__XXX
 SG_ SensorR_TX_AccRear_X : 0|16@1- (0.00125,0) [-40.96|40.95875] "m/s^2" Vector__XXX

BO_ 1282 SensorR_TX_Pos: 8 SensorR
 SG_ SensorR_TX_StripeCounter_Right : 59|5@1+ (1,0) [0|31] "" Vector__XXX
 SG_ SensorR_TX_StripeCounter_Left : 54|5@1+ (1,0) [0|31] "" Vector__XXX
 SG_ SensorR_TX_Pos_Optical : 36|18@1- (0.005,0) [-655.36|655.355] "m" Vector__XXX
 SG_ SensorR_TX_Pos_EncoderRear : 18|18@1- (0.005,0) [-655.36|655.355] "m" Vector__XXX
 SG_ SensorR_TX_Pos_EncoderFront : 0|18@1- (0.005,0) [-655.36|655.355] "m" Vector__XXX

BO_ 1346 SensorR_TX_PDO12: 0 SensorR

BO_ 1410 SensorR_SDO_Resp: 8 SensorR
 SG_ SensorR_OD_posDeviationOptic m3589 : 16|16@1+ (0.1,0) [0|6553.5] ""  TelemetryNode
 SG_ SensorR_OD_posDeviationEncoder m3588 : 16|16@1+ (0.1,0) [0|6553.5] ""  TelemetryNode
 SG_ SensorR_OD_velDeviationOptic m3587 : 16|16@1+ (0.1,0) [0|6553.5] ""  TelemetryNode
 SG_ SensorR_OD_velDeviationEncoder m3586 : 16|16@1+ (0.1,0) [0|6553.5] ""  TelemetryNode
 SG_ SensorR_OD_accDeviation m3585 : 16|16@1+ (0.1,0) [0|6553.5] ""  TelemetryNode
 SG_ SensorR_OD_EnableSignalGeneratio m3332 : 16|8@1+ (1,0) [0|255] ""  TelemetryNode
 SG_ SensorR_OD_PositionGlitch m3331 : 16|16@1+ (0.1,0) [0|6553.5] ""  TelemetryNode
 SG_ SensorR_OD_ReflectorDistance m3330 : 16|16@1+ (0.1,0) [0|6553.5] ""  TelemetryNode
 SG_ SensorR_OD_StripeMode m3329 : 16|8@1+ (1,0) [0|255] ""  TelemetryNode
 SG_ SensorR_OD_opc_lowpass_TcI m3123 : 16|16@1+ (0.01,0) [0|655.35] "s"  TelemetryNode
 SG_ SensorR_OD_opc_lowpass_Tcf m3122 : 16|16@1+ (0.01,0) [0|655.35] "s"  TelemetryNode
 SG_ SensorR_OD_opc_F_decrease m3121 : 16|16@1+ (0.01,0) [0|655.35] "F/s"  TelemetryNode
 SG_ SensorR_OD_opc_v_threshold m3120 : 16|16@1+ (0.01,0) [0|655.35] "m/s"  TelemetryNode
 SG_ SensorR_OD_opc_v_max m3113 : 16|16@1+ (0.01,0) [0|655.35] "m/s"  TelemetryNode
 SG_ SensorR_OD_opc_T_acc m3112 : 16|16@1+ (0.1,0) [0|6553.5] "s"  TelemetryNode
 SG_ SensorR_OD_opc_F_max m3111 : 16|16@1+ (1,0) [0|65535] "N"  TelemetryNode
 SG_ SensorR_OD_opc_t_run_max m3110 : 16|16@1+ (0.1,0) [0|6553.5] "s"  TelemetryNode
 SG_ SensorR_OD_opc_brakeFlag m3109 : 16|8@1+ (1,0) [0|255] ""  TelemetryNode
 SG_ SensorR_OD_DebugCVOPCfreq m3108 : 16|16@1+ (0.1,-3200) [-3200|3353.5] ""  TelemetryNode
 SG_ SensorR_OD_DebugCascadedIreq m3107 : 16|16@1+ (0.1,-3200) [-3200|3353.5] ""  TelemetryNode
 SG_ SensorR_OD_opc_ratelimiter_f m3106 : 16|16@1+ (0.1,-3200) [-3200|3353.5] ""  TelemetryNode
 SG_ SensorR_OD_maxRunDistance m3105 : 16|16@1+ (0.05,-1600) [-1600|1676.75] "m"  TelemetryNode
 SG_ SensorR_OD_FinishedDelay m3104 : 16|16@1+ (1,0) [0|65535] "ms"  TelemetryNode
 SG_ SensorR_OD_Current4Stopping m3097 : 16|16@1+ (0.1,0) [0|6553.5] "A"  TelemetryNode
 SG_ SensorR_OD_AdaptModelByCurrent m3096 : 16|8@1+ (1,0) [0|255] ""  TelemetryNode
 SG_ SensorR_OD_CVOPCTcFreq m3095 : 16|16@1+ (1,0) [0|65535] "ms"  TelemetryNode
 SG_ SensorR_OD_CVOPCImin m3094 : 16|16@1+ (1,0) [0|65535] ""  TelemetryNode
 SG_ SensorR_OD_CascadedKpDecreaseCur m3093 : 16|16@1+ (0.1,0) [0|6553.5] "A/s"  TelemetryNode
 SG_ SensorR_OD_CascadedKpIncreaseCur m3092 : 16|16@1+ (0.1,0) [0|6553.5] "A/s"  TelemetryNode
 SG_ SensorR_OD_CascadedFreqCurUpdate m3091 : 16|16@1+ (0.001,0) [0|65.535] "s"  TelemetryNode
 SG_ SensorR_OD_CascadedMaxSetForceDe m3090 : 16|16@1+ (0.1,0) [0|6553.5] "Newton"  TelemetryNode
 SG_ SensorR_OD_CurrentForConstantVel m3089 : 16|16@1+ (0.01,0) [0|655.35] "A"  TelemetryNode
 SG_ SensorR_OD_AccAtCurrentMeasured m3088 : 16|16@1+ (0.01,0) [0|655.35] "m/s^2"  TelemetryNode
 SG_ SensorR_OD_CVOPCHystereseF m3081 : 16|16@1+ (0.1,0) [0|6553.5] "Newton"  TelemetryNode
 SG_ SensorR_OD_CVOPCReduceCurrentWhi m3080 : 16|16@1+ (0.01,0) [0|655.35] ""  TelemetryNode
 SG_ SensorR_OD_CVOPCDeltaVelHigherCu m3079 : 16|16@1+ (0.01,0) [0|655.35] "m/s"  TelemetryNode
 SG_ SensorR_OD_CVOPCSmoothingDeltaVe m3078 : 16|16@1+ (0.01,0) [0|655.35] "m/s"  TelemetryNode
 SG_ SensorR_OD_CVOPCTcI m3077 : 16|16@1+ (1,0) [0|65535] "ms"  TelemetryNode
 SG_ SensorR_OD_CVOPCTcf m3076 : 16|16@1+ (1,0) [0|65535] "ms"  TelemetryNode
 SG_ SensorR_OD_CVOPCImax m3075 : 16|16@1+ (1,0) [0|65535] ""  TelemetryNode
 SG_ SensorR_OD_VelocityController m3074 : 16|8@1+ (1,0) [0|255] ""  TelemetryNode
 SG_ SensorR_OD_TC_f m3073 : 16|16@1+ (1,0) [0|65535] "ms"  TelemetryNode
 SG_ SensorR_OD_TC_I m3072 : 16|16@1+ (1,0) [0|65535] "ms"  TelemetryNode
 SG_ SensorR_OD_EstimatedRunLength m2826 : 16|16@1+ (0.05,-1600) [-1600|1676.75] "m"  TelemetryNode
 SG_ SensorR_OD_RunProfile_V4 m2825 : 16|16@1+ (0.01,-327) [-327|328.35] "m/s"  TelemetryNode
 SG_ SensorR_OD_RunProfile_T4 m2824 : 16|16@1+ (10,0) [0|655350] "ms"  TelemetryNode
 SG_ SensorR_OD_RunProfile_V3 m2823 : 16|16@1+ (0.01,-327) [-327|328.35] "m/s"  TelemetryNode
 SG_ SensorR_OD_RunProfile_T3 m2822 : 16|16@1+ (10,0) [0|655350] "ms"  TelemetryNode
 SG_ SensorR_OD_RunProfile_V2 m2821 : 16|16@1+ (0.01,-327) [-327|328.35] "m/s"  TelemetryNode
 SG_ SensorR_OD_RunProfile_T2 m2820 : 16|16@1+ (10,0) [0|655350] "ms"  TelemetryNode
 SG_ SensorR_OD_RunProfile_V1 m2819 : 16|16@1+ (0.01,-327) [-327|328.35] "m/s"  TelemetryNode
 SG_ SensorR_OD_RunProfile_T1 m2818 : 16|16@1+ (10,0) [0|655350] "ms"  TelemetryNode
 SG_ SensorR_OD_RunProfile_V0 m2817 : 16|16@1+ (0.01,-327) [-327|328.35] "m/s"  TelemetryNode
 SG_ SensorR_OD_RunProfile_T0 m2816 : 16|16@1+ (10,0) [0|655350] "ms"  TelemetryNode
 SG_ SensorR_OD_SetFinish m2637 : 16|8@1+ (1,0) [0|255] ""  TelemetryNode
 SG_ SensorR_OD_RunMode m2636 : 16|8@1+ (1,0) [0|255] ""  TelemetryNode
 SG_ SensorR_OD_VdcReduceFactor m2635 : 16|16@1+ (0.1,0) [0|6553.5] ""  TelemetryNode
 SG_ SensorR_OD_MaxRequiredVelocity m2634 : 16|16@1+ (0.1,0) [0|6553.5] "m/s"  TelemetryNode
 SG_ SensorR_OD_WarningThreshholdForL m2633 : 16|16@1+ (0.001,0) [0|65.535] "s"  TelemetryNode
 SG_ SensorR_OD_MaxCtrlErrorDuration m2632 : 16|16@1+ (0.01,0) [0|655.35] "s"  TelemetryNode
 SG_ SensorR_OD_MaxCtrlError m2631 : 16|16@1+ (0.01,0) [0|655.35] "m/s"  TelemetryNode
 SG_ SensorR_OD_FminCtrl m2630 : 16|16@1+ (1.0,0) [0|65535.0] "N"  TelemetryNode
 SG_ SensorR_OD_FmaxCtrl m2629 : 16|16@1+ (1.0,0) [0|65535.0] "N"  TelemetryNode
 SG_ SensorR_OD_PodMass m2628 : 16|16@1+ (0.1,0) [0|6553.5] "kg"  TelemetryNode
 SG_ SensorR_OD_CurrentReq m2627 : 16|16@1+ (0.1,0) [0|6553.5] "A"  TelemetryNode
 SG_ SensorR_OD_CtrlMode m2626 : 16|8@1+ (1,0) [0|255] ""  TelemetryNode
 SG_ SensorR_OD_OpcKi m2625 : 16|16@1+ (0.01,0) [0|655.35] ""  TelemetryNode
 SG_ SensorR_OD_OpcKp m2624 : 16|16@1+ (0.01,0) [0|655.35] ""  TelemetryNode
 SG_ SensorR_OD_ExecTimeReadSensors m2611 : 16|16@1+ (0.01,0) [0|655.35] "ms"  TelemetryNode
 SG_ SensorR_OD_ExecTimeControl m2610 : 16|16@1+ (0.01,0) [0|655.35] "ms"  TelemetryNode
 SG_ SensorR_OD_ExecTimeStateEst m2609 : 16|16@1+ (0.01,0) [0|655.35] "ms"  TelemetryNode
 SG_ SensorR_OD_ExecTimeOverall m2608 : 16|16@1+ (0.01,0) [0|655.35] "ms"  TelemetryNode
 SG_ SensorR_OD_IMU3_Temperature m2599 : 16|16@1+ (0.01,-100) [-100|555.35] ""  TelemetryNode
 SG_ SensorR_OD_IMU2_Temperature m2598 : 16|16@1+ (0.01,-100) [-100|555.35] ""  TelemetryNode
 SG_ SensorR_OD_IMU1_Temperature m2597 : 16|16@1+ (0.01,-100) [-100|555.35] ""  TelemetryNode
 SG_ SensorR_OD_IMU_number m2592 : 16|8@1+ (1,0) [0|255] ""  TelemetryNode
 SG_ SensorR_OD_EncoderResetPosition m2586 : 16|8@1+ (1,0) [0|255] ""  TelemetryNode
 SG_ SensorR_OD_EncoderWheelDiameter m2576 : 16|16@1+ (0.005,0) [1|300] "mm"  TelemetryNode
 SG_ SensorR_OD_samplingInterval m2048 : 16|16@1+ (0.01,0) [0.01|100] "ms"  TelemetryNode
 SG_ SensorR_OD_CAN2_DelayedTxMessage m1129 : 16|24@1+ (1,0) [0|16777215] ""  TelemetryNode
 SG_ SensorR_OD_CAN2_ErrorStatus m1128 : 16|8@1+ (1,0) [0|255] ""  TelemetryNode
 SG_ SensorR_OD_CAN2_DiscardedTxMessa m1127 : 16|24@1+ (1,0) [0|16777215] ""  TelemetryNode
 SG_ SensorR_OD_CAN2_Status m1126 : 16|8@1+ (1,0) [0|255] ""  TelemetryNode
 SG_ SensorR_OD_CAN2_Baudrate m1124 : 16|16@1+ (1,0) [125|1000] "kbps"  TelemetryNode
 SG_ SensorR_OD_CAN2_autoErrorReset m1123 : 16|8@1+ (1,0) [0|255] ""  TelemetryNode
 SG_ SensorR_OD_CAN2_lastErrorCode m1122 : 16|32@1+ (1,0) [0|4294967295] ""  TelemetryNode
 SG_ SensorR_OD_CAN2_RxErrCnt m1121 : 16|8@1+ (1,0) [0|255] ""  TelemetryNode
 SG_ SensorR_OD_CAN2_TxErrCnt m1120 : 16|8@1+ (1,0) [0|255] ""  TelemetryNode
 SG_ SensorR_OD_CAN1_DelayedTxMessage m1113 : 16|24@1+ (1,0) [0|16777215] ""  TelemetryNode
 SG_ SensorR_OD_CAN1_ErrorStatus m1112 : 16|8@1+ (1,0) [0|255] ""  TelemetryNode
 SG_ SensorR_OD_CAN1_DiscardedTxMessa m1111 : 16|24@1+ (1,0) [0|16777215] ""  TelemetryNode
 SG_ SensorR_OD_CAN1_Status m1110 : 16|8@1+ (1,0) [0|255] ""  TelemetryNode
 SG_ SensorR_OD_CAN1_Baudrate m1108 : 16|16@1+ (1,0) [125|1000] "kbps"  TelemetryNode
 SG_ SensorR_OD_CAN1_autoErrorReset m1107 : 16|8@1+ (1,0) [0|255] ""  TelemetryNode
 SG_ SensorR_OD_CAN1_lastErrorCode m1106 : 16|32@1+ (1,0) [0|4294967295] ""  TelemetryNode
 SG_ SensorR_OD_CAN1_RxErrCnt m1105 : 16|8@1+ (1,0) [0|255] ""  TelemetryNode
 SG_ SensorR_OD_CAN1_TxErrCnt m1104 : 16|8@1+ (1,0) [0|255] ""  TelemetryNode
 SG_ SensorR_OD_BuildTime m1073 : 16|24@1+ (1,0) [0|16777215] ""  TelemetryNode
 SG_ SensorR_OD_BuildDate m1072 : 16|32@1+ (1,0) [0|4294967295] ""  TelemetryNode
 SG_ SensorR_OD_ChipUID2 m1057 : 16|48@1+ (1,0) [0|281474976710655] ""  TelemetryNode
 SG_ SensorR_OD_ChipUID1 m1056 : 16|48@1+ (1,0) [0|281474976710655] ""  TelemetryNode
 SG_ SensorR_OD_SdcOut m1046 : 16|8@1+ (1,0) [0|255] ""  TelemetryNode
 SG_ SensorR_OD_SdcIn m1045 : 16|8@1+ (1,0) [0|255] ""  TelemetryNode
 SG_ SensorR_OD_runtime m1044 : 16|24@1+ (1,0) [0|16777215] "ms"  TelemetryNode
 SG_ SensorR_OD_InputVoltage m1043 : 16|16@1+ (0.001,0) [0|65.535] "V"  TelemetryNode
 SG_ SensorR_OD_BoardTemp m1042 : 16|16@1+ (0.01,-30) [-30|625.35] "°C"  TelemetryNode
 SG_ SensorR_OD_MemFree m1041 : 16|16@1+ (4,0) [0|262140] "bytes"  TelemetryNode
 SG_ SensorR_OD_CpuUsage m1040 : 16|8@1+ (0.5,0) [0|100] "%"  TelemetryNode
 SG_ SensorR_OD_OdEntrySendInterval m33 : 16|16@1+ (1,0) [0|65535] "ms"  TelemetryNode
 SG_ SensorR_OD_SendOdOnBootup m32 : 16|8@1+ (1,0) [0|255] ""  TelemetryNode
 SG_ SensorR_OD_HeartbeatInterval m16 : 16|16@1+ (1,0) [0|65535] "ms"  TelemetryNode
 SG_ SensorR_OD_DbcVersion m5 : 16|16@1+ (1,0) [0|65535] ""  TelemetryNode
 SG_ SensorR_OD_StackVersion m4 : 16|16@1+ (1,0) [0|65535] ""  TelemetryNode
 SG_ SensorR_OD_ProtocolVersion m3 : 16|16@1+ (1,0) [0|65535] ""  TelemetryNode
 SG_ SensorR_OD_NodeStatus m2 : 16|8@1+ (1,0) [0|255] ""  TelemetryNode
 SG_ SensorR_OD_NodeID m1 : 16|8@1+ (1,0) [0|255] ""  TelemetryNode
 SG_ SensorR_SDO_RespCode : 12|4@1+ (1,0) [0|0] ""  TelemetryNode
 SG_ SensorR_SDO_ID M : 0|12@1+ (1,0) [0|4095] ""  PDU,TelemetryNode

BO_ 1474 SensorR_SDO_Req_Up: 8 TelemetryNode
 SG_ SensorR_OD_posDeviationOptic m3589 : 16|16@1+ (0.1,0) [0|6553.5] ""  SensorR
 SG_ SensorR_OD_posDeviationEncoder m3588 : 16|16@1+ (0.1,0) [0|6553.5] ""  SensorR
 SG_ SensorR_OD_velDeviationOptic m3587 : 16|16@1+ (0.1,0) [0|6553.5] ""  SensorR
 SG_ SensorR_OD_velDeviationEncoder m3586 : 16|16@1+ (0.1,0) [0|6553.5] ""  SensorR
 SG_ SensorR_OD_accDeviation m3585 : 16|16@1+ (0.1,0) [0|6553.5] ""  SensorR
 SG_ SensorR_OD_EnableSignalGene_0000 m3332 : 16|8@1+ (1,0) [0|255] ""  SensorR
 SG_ SensorR_OD_PositionGlitch m3331 : 16|16@1+ (0.1,0) [0|6553.5] ""  SensorR
 SG_ SensorR_OD_ReflectorDistance m3330 : 16|16@1+ (0.1,0) [0|6553.5] ""  SensorR
 SG_ SensorR_OD_StripeMode m3329 : 16|8@1+ (1,0) [0|255] ""  SensorR
 SG_ SensorR_OD_opc_lowpass_TcI m3123 : 16|16@1+ (0.01,0) [0|655.35] "s"  SensorR
 SG_ SensorR_OD_opc_lowpass_Tcf m3122 : 16|16@1+ (0.01,0) [0|655.35] "s"  SensorR
 SG_ SensorR_OD_opc_F_decrease m3121 : 16|16@1+ (0.01,0) [0|655.35] "F/s"  SensorR
 SG_ SensorR_OD_opc_v_threshold m3120 : 16|16@1+ (0.01,0) [0|655.35] "m/s"  SensorR
 SG_ SensorR_OD_opc_v_max m3113 : 16|16@1+ (0.01,0) [0|655.35] "m/s"  SensorR
 SG_ SensorR_OD_opc_T_acc m3112 : 16|16@1+ (0.1,0) [0|6553.5] "s"  SensorR
 SG_ SensorR_OD_opc_F_max m3111 : 16|16@1+ (1,0) [0|65535] "N"  SensorR
 SG_ SensorR_OD_opc_t_run_max m3110 : 16|16@1+ (0.1,0) [0|6553.5] "s"  SensorR
 SG_ SensorR_OD_opc_brakeFlag m3109 : 16|8@1+ (1,0) [0|255] ""  SensorR
 SG_ SensorR_OD_DebugCVOPCfreq m3108 : 16|16@1+ (0.1,-3200) [-3200|3353.5] ""  SensorR
 SG_ SensorR_OD_DebugCascadedIreq m3107 : 16|16@1+ (0.1,-3200) [-3200|3353.5] ""  SensorR
 SG_ SensorR_OD_opc_ratelimiter_f m3106 : 16|16@1+ (0.1,-3200) [-3200|3353.5] ""  SensorR
 SG_ SensorR_OD_maxRunDistance m3105 : 16|16@1+ (0.05,-1600) [-1600|1676.75] "m"  SensorR
 SG_ SensorR_OD_FinishedDelay m3104 : 16|16@1+ (1,0) [0|65535] "ms"  SensorR
 SG_ SensorR_OD_Current4Stopping m3097 : 16|16@1+ (0.1,0) [0|6553.5] "A"  SensorR
 SG_ SensorR_OD_AdaptModelByCurrent m3096 : 16|8@1+ (1,0) [0|255] ""  SensorR
 SG_ SensorR_OD_CVOPCTcFreq m3095 : 16|16@1+ (1,0) [0|65535] "ms"  SensorR
 SG_ SensorR_OD_CVOPCImin m3094 : 16|16@1+ (1,0) [0|65535] ""  SensorR
 SG_ SensorR_OD_CascadedKpDecrea_0000 m3093 : 16|16@1+ (0.1,0) [0|6553.5] "A/s"  SensorR
 SG_ SensorR_OD_CascadedKpIncrea_0000 m3092 : 16|16@1+ (0.1,0) [0|6553.5] "A/s"  SensorR
 SG_ SensorR_OD_CascadedFreqCurUpdate m3091 : 16|16@1+ (0.001,0) [0|65.535] "s"  SensorR
 SG_ SensorR_OD_CascadedMaxSetFo_0000 m3090 : 16|16@1+ (0.1,0) [0|6553.5] "Newton"  SensorR
 SG_ SensorR_OD_CurrentForConsta_0000 m3089 : 16|16@1+ (0.01,0) [0|655.35] "A"  SensorR
 SG_ SensorR_OD_AccAtCurrentMeasured m3088 : 16|16@1+ (0.01,0) [0|655.35] "m/s^2"  SensorR
 SG_ SensorR_OD_CVOPCHystereseF m3081 : 16|16@1+ (0.1,0) [0|6553.5] "Newton"  SensorR
 SG_ SensorR_OD_CVOPCReduceCurre_0000 m3080 : 16|16@1+ (0.01,0) [0|655.35] ""  SensorR
 SG_ SensorR_OD_CVOPCDeltaVelHig_0000 m3079 : 16|16@1+ (0.01,0) [0|655.35] "m/s"  SensorR
 SG_ SensorR_OD_CVOPCSmoothingDe_0000 m3078 : 16|16@1+ (0.01,0) [0|655.35] "m/s"  SensorR
 SG_ SensorR_OD_CVOPCTcI m3077 : 16|16@1+ (1,0) [0|65535] "ms"  SensorR
 SG_ SensorR_OD_CVOPCTcf m3076 : 16|16@1+ (1,0) [0|65535] "ms"  SensorR
 SG_ SensorR_OD_CVOPCImax m3075 : 16|16@1+ (1,0) [0|65535] ""  SensorR
 SG_ SensorR_OD_VelocityController m3074 : 16|8@1+ (1,0) [0|255] ""  SensorR
 SG_ SensorR_OD_TC_f m3073 : 16|16@1+ (1,0) [0|65535] "ms"  SensorR
 SG_ SensorR_OD_TC_I m3072 : 16|16@1+ (1,0) [0|65535] "ms"  SensorR
 SG_ SensorR_OD_EstimatedRunLength m2826 : 16|16@1+ (0.05,-1600) [-1600|1676.75] "m"  SensorR
 SG_ SensorR_OD_RunProfile_V4 m2825 : 16|16@1+ (0.01,-327) [-327|328.35] "m/s"  SensorR
 SG_ SensorR_OD_RunProfile_T4 m2824 : 16|16@1+ (10,0) [0|655350] "ms"  SensorR
 SG_ SensorR_OD_RunProfile_V3 m2823 : 16|16@1+ (0.01,-327) [-327|328.35] "m/s"  SensorR
 SG_ SensorR_OD_RunProfile_T3 m2822 : 16|16@1+ (10,0) [0|655350] "ms"  SensorR
 SG_ SensorR_OD_RunProfile_V2 m2821 : 16|16@1+ (0.01,-327) [-327|328.35] "m/s"  SensorR
 SG_ SensorR_OD_RunProfile_T2 m2820 : 16|16@1+ (10,0) [0|655350] "ms"  SensorR
 SG_ SensorR_OD_RunProfile_V1 m2819 : 16|16@1+ (0.01,-327) [-327|328.35] "m/s"  SensorR
 SG_ SensorR_OD_RunProfile_T1 m2818 : 16|16@1+ (10,0) [0|655350] "ms"  SensorR
 SG_ SensorR_OD_RunProfile_V0 m2817 : 16|16@1+ (0.01,-327) [-327|328.35] "m/s"  SensorR
 SG_ SensorR_OD_RunProfile_T0 m2816 : 16|16@1+ (10,0) [0|655350] "ms"  SensorR
 SG_ SensorR_OD_SetFinish m2637 : 16|8@1+ (1,0) [0|255] ""  SensorR
 SG_ SensorR_OD_RunMode m2636 : 16|8@1+ (1,0) [0|255] ""  SensorR
 SG_ SensorR_OD_VdcReduceFactor m2635 : 16|16@1+ (0.1,0) [0|6553.5] ""  SensorR
 SG_ SensorR_OD_MaxRequiredVelocity m2634 : 16|16@1+ (0.1,0) [0|6553.5] "m/s"  SensorR
 SG_ SensorR_OD_WarningThreshhol_0000 m2633 : 16|16@1+ (0.001,0) [0|65.535] "s"  SensorR
 SG_ SensorR_OD_MaxCtrlErrorDuration m2632 : 16|16@1+ (0.01,0) [0|655.35] "s"  SensorR
 SG_ SensorR_OD_MaxCtrlError m2631 : 16|16@1+ (0.01,0) [0|655.35] "m/s"  SensorR
 SG_ SensorR_OD_FminCtrl m2630 : 16|16@1+ (1.0,0) [0|65535.0] "N"  SensorR
 SG_ SensorR_OD_FmaxCtrl m2629 : 16|16@1+ (1.0,0) [0|65535.0] "N"  SensorR
 SG_ SensorR_OD_PodMass m2628 : 16|16@1+ (0.1,0) [0|6553.5] "kg"  SensorR
 SG_ SensorR_OD_CurrentReq m2627 : 16|16@1+ (0.1,0) [0|6553.5] "A"  SensorR
 SG_ SensorR_OD_CtrlMode m2626 : 16|8@1+ (1,0) [0|255] ""  SensorR
 SG_ SensorR_OD_OpcKi m2625 : 16|16@1+ (0.01,0) [0|655.35] ""  SensorR
 SG_ SensorR_OD_OpcKp m2624 : 16|16@1+ (0.01,0) [0|655.35] ""  SensorR
 SG_ SensorR_OD_ExecTimeReadSensors m2611 : 16|16@1+ (0.01,0) [0|655.35] "ms"  SensorR
 SG_ SensorR_OD_ExecTimeControl m2610 : 16|16@1+ (0.01,0) [0|655.35] "ms"  SensorR
 SG_ SensorR_OD_ExecTimeStateEst m2609 : 16|16@1+ (0.01,0) [0|655.35] "ms"  SensorR
 SG_ SensorR_OD_ExecTimeOverall m2608 : 16|16@1+ (0.01,0) [0|655.35] "ms"  SensorR
 SG_ SensorR_OD_IMU3_Temperature m2599 : 16|16@1+ (0.01,-100) [-100|555.35] ""  SensorR
 SG_ SensorR_OD_IMU2_Temperature m2598 : 16|16@1+ (0.01,-100) [-100|555.35] ""  SensorR
 SG_ SensorR_OD_IMU1_Temperature m2597 : 16|16@1+ (0.01,-100) [-100|555.35] ""  SensorR
 SG_ SensorR_OD_IMU_number m2592 : 16|8@1+ (1,0) [0|255] ""  SensorR
 SG_ SensorR_OD_EncoderResetPosition m2586 : 16|8@1+ (1,0) [0|255] ""  SensorR
 SG_ SensorR_OD_EncoderWheelDiameter m2576 : 16|16@1+ (0.005,0) [1|300] "mm"  SensorR
 SG_ SensorR_OD_samplingInterval m2048 : 16|16@1+ (0.01,0) [0.01|100] "ms"  SensorR
 SG_ SensorR_OD_CAN2_DelayedTxMe_0000 m1129 : 16|24@1+ (1,0) [0|16777215] ""  SensorR
 SG_ SensorR_OD_CAN2_ErrorStatus m1128 : 16|8@1+ (1,0) [0|255] ""  SensorR
 SG_ SensorR_OD_CAN2_DiscardedTx_0000 m1127 : 16|24@1+ (1,0) [0|16777215] ""  SensorR
 SG_ SensorR_OD_CAN2_Status m1126 : 16|8@1+ (1,0) [0|255] ""  SensorR
 SG_ SensorR_OD_CAN2_Baudrate m1124 : 16|16@1+ (1,0) [125|1000] "kbps"  SensorR
 SG_ SensorR_OD_CAN2_autoErrorReset m1123 : 16|8@1+ (1,0) [0|255] ""  SensorR
 SG_ SensorR_OD_CAN2_lastErrorCode m1122 : 16|32@1+ (1,0) [0|4294967295] ""  SensorR
 SG_ SensorR_OD_CAN2_RxErrCnt m1121 : 16|8@1+ (1,0) [0|255] ""  SensorR
 SG_ SensorR_OD_CAN2_TxErrCnt m1120 : 16|8@1+ (1,0) [0|255] ""  SensorR
 SG_ SensorR_OD_CAN1_DelayedTxMe_0000 m1113 : 16|24@1+ (1,0) [0|16777215] ""  SensorR
 SG_ SensorR_OD_CAN1_ErrorStatus m1112 : 16|8@1+ (1,0) [0|255] ""  SensorR
 SG_ SensorR_OD_CAN1_DiscardedTx_0000 m1111 : 16|24@1+ (1,0) [0|16777215] ""  SensorR
 SG_ SensorR_OD_CAN1_Status m1110 : 16|8@1+ (1,0) [0|255] ""  SensorR
 SG_ SensorR_OD_CAN1_Baudrate m1108 : 16|16@1+ (1,0) [125|1000] "kbps"  SensorR
 SG_ SensorR_OD_CAN1_autoErrorReset m1107 : 16|8@1+ (1,0) [0|255] ""  SensorR
 SG_ SensorR_OD_CAN1_lastErrorCode m1106 : 16|32@1+ (1,0) [0|4294967295] ""  SensorR
 SG_ SensorR_OD_CAN1_RxErrCnt m1105 : 16|8@1+ (1,0) [0|255] ""  SensorR
 SG_ SensorR_OD_CAN1_TxErrCnt m1104 : 16|8@1+ (1,0) [0|255] ""  SensorR
 SG_ SensorR_OD_BuildTime m1073 : 16|24@1+ (1,0) [0|16777215] ""  SensorR
 SG_ SensorR_OD_BuildDate m1072 : 16|32@1+ (1,0) [0|4294967295] ""  SensorR
 SG_ SensorR_OD_ChipUID2 m1057 : 16|48@1+ (1,0) [0|281474976710655] ""  SensorR
 SG_ SensorR_OD_ChipUID1 m1056 : 16|48@1+ (1,0) [0|281474976710655] ""  SensorR
 SG_ SensorR_OD_SdcOut m1046 : 16|8@1+ (1,0) [0|255] ""  SensorR
 SG_ SensorR_OD_SdcIn m1045 : 16|8@1+ (1,0) [0|255] ""  SensorR
 SG_ SensorR_OD_runtime m1044 : 16|24@1+ (1,0) [0|16777215] "ms"  SensorR
 SG_ SensorR_OD_InputVoltage m1043 : 16|16@1+ (0.001,0) [0|65.535] "V"  SensorR
 SG_ SensorR_OD_BoardTemp m1042 : 16|16@1+ (0.01,-30) [-30|625.35] "°C"  SensorR
 SG_ SensorR_OD_MemFree m1041 : 16|16@1+ (4,0) [0|262140] "bytes"  SensorR
 SG_ SensorR_OD_CpuUsage m1040 : 16|8@1+ (0.5,0) [0|100] "%"  SensorR
 SG_ SensorR_OD_OdEntrySendInterval m33 : 16|16@1+ (1,0) [0|65535] "ms"  SensorR
 SG_ SensorR_OD_SendOdOnBootup m32 : 16|8@1+ (1,0) [0|255] ""  SensorR
 SG_ SensorR_OD_HeartbeatInterval m16 : 16|16@1+ (1,0) [0|65535] "ms"  SensorR
 SG_ SensorR_OD_DbcVersion m5 : 16|16@1+ (1,0) [0|65535] ""  SensorR
 SG_ SensorR_OD_StackVersion m4 : 16|16@1+ (1,0) [0|65535] ""  SensorR
 SG_ SensorR_OD_ProtocolVersion m3 : 16|16@1+ (1,0) [0|65535] ""  SensorR
 SG_ SensorR_OD_NodeStatus m2 : 16|8@1+ (1,0) [0|255] ""  SensorR
 SG_ SensorR_OD_NodeID m1 : 16|8@1+ (1,0) [0|255] ""  SensorR
 SG_ SensorR_SDO_ID M : 0|12@1+ (1,0) [0|4095] ""  SensorR

BO_ 1538 SensorR_SDO_Req_Down: 2 TelemetryNode
 SG_ SensorR_SDO_ID M : 0|12@1+ (1,0) [0|4095] ""  SensorR

BO_ 1794 SensorR_Heartbeat: 1 SensorR
 SG_ SensorR_NodeState : 0|8@1+ (1,0) [0|0] ""  Master,TelemetryNode

BO_ 1858 SensorR_BTL_TX: 8 SensorR

BO_ 1922 SensorR_BTL_RX: 8 TelemetryNode

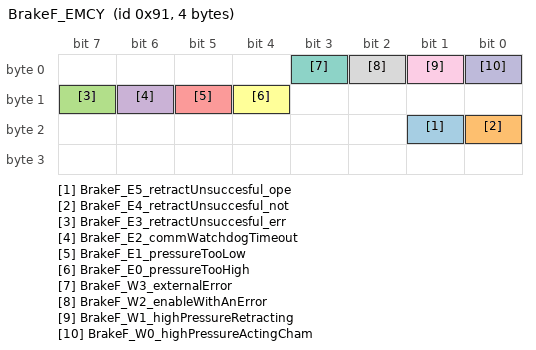
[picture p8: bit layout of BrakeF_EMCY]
BO_ 145 BrakeF_EMCY: 4 BrakeF
 SG_ BrakeF_E5_retractUnsuccesful_ope : 17|1@1+ (1,0) [0|0] ""  Master,TelemetryNode
 SG_ BrakeF_E4_retractUnsuccesful_not : 16|1@1+ (1,0) [0|0] ""  Master,TelemetryNode
 SG_ BrakeF_E3_retractUnsuccesful_err : 15|1@1+ (1,0) [0|0] ""  Master,TelemetryNode
 SG_ BrakeF_E2_commWatchdogTimeout : 14|1@1+ (1,0) [0|0] ""  Master,TelemetryNode
 SG_ BrakeF_E1_pressureTooLow : 13|1@1+ (1,0) [0|0] ""  Master,TelemetryNode
 SG_ BrakeF_E0_pressureTooHigh : 12|1@1+ (1,0) [0|0] ""  Master,TelemetryNode
 SG_ BrakeF_W3_externalError : 3|1@1+ (1,0) [0|0] ""  Master,TelemetryNode
 SG_ BrakeF_W2_enableWithAnError : 2|1@1+ (1,0) [0|0] ""  Master,TelemetryNode
 SG_ BrakeF_W1_highPressureRetracting : 1|1@1+ (1,0) [0|0] ""  Master,TelemetryNode
 SG_ BrakeF_W0_highPressureActingCham : 0|1@1+ (1,0) [0|0] ""  Master,TelemetryNode

BO_TX_BU_ 260 : MDB3,MDB2,MDB1,MDB6,MDB5,MDB4;
BO_TX_BU_ 257 : MDB3,MDB2,MDB1,MDB6,MDB5,MDB4;
BO_TX_BU_ 256 : MDB3,MDB4,MDB6,MDB1,MDB2;

CM_ BU_ OpticalSensor "Kistler SFP-II optical Sensor.";
CM_ BU_ EMUS_BMS "HV BMS ";
CM_ BU_ TelemetryNode "Gateway between Pod and Telemetry
Node-ID 0x22Gateway between Pod and Telemetry
Node-ID 0x22";
CM_ BU_ Master "CANzero NMT Master Node.";
CM_ BU_ SensorF "SensorECU
Node-ID 0x1";
CM_ BU_ SensorR "SensorECUR
Node-ID 0x2";
CM_ BU_ BrakeF "BrakeECU Front
Node-ID 0x11";
CM_ BU_ BrakeR "BrakeECUR
Node-ID 0x12";
CM_ BU_ PDU "PowerD
Node-ID 0x1A";
CM_ BU_ HVCU "HVController
Node-ID 0xA";
CM_ BU_ HVTU "High Voltage CAN Translation Unit between BMS and Pod
Node-ID 0x19";
CM_ BU_ MDB1 "ModularLevitationUnit-1
Node-ID 0x21";
CM_ BU_ MDB2 "ModularLevitationUnit-2
Node-ID 0x23";
CM_ BU_ MDB3 "ModularLevitationUnit-3
Node-ID 0x27";
CM_ BU_ MDB4 "ModularLevitationUnit-4
Node-ID 0x28";
CM_ BU_ MDB5 "ModularLevitationUnit-5
Node-ID 0x29";
CM_ BU_ MDB6 "ModularLevitationUnit-6
Node-ID 0x31";
CM_ BU_ Track "TrackECU
Node-ID 0x32";
CM_ BU_ CLU "central levitation unit
Node-ID 0x14";
CM_ SG_ 274 MDB3_TargetAirGap "as binary IEEE-754
";
CM_ SG_ 295 MDB6_TargetAirGap "as binary IEEE-754
";
CM_ SG_ 297 MDB6_Temperature "as binary IEEE-754";
CM_ SG_ 294 MDB6_TargetAirGap "as binary IEEE-754
";
CM_ SG_ 292 MDB5_Temperature "as binary IEEE-754";
CM_ SG_ 290 MDB5_TargetAirGap "as binary IEEE-754
";
CM_ SG_ 289 MDB5_AirGap "as binary IEEE-754
";
CM_ SG_ 281 MDB4_Temperature "as binary IEEE-754";
CM_ SG_ 279 MDB4_TargetAirGap "as binary IEEE-754
";
CM_ SG_ 278 MDB4_AirGap "as binary IEEE-754
";
CM_ SG_ 276 MDB3_Temperature "as binary IEEE-754";
CM_ SG_ 273 MDB3_AirGap "as binary IEEE-754
";
CM_ SG_ 265 MDB2_Temperature "as binary IEEE-754";
CM_ SG_ 263 MDB2_TargetAirGap "as binary IEEE-754
";
CM_ SG_ 262 MDB2_AirGap "as binary IEEE-754
";
CM_ SG_ 258 MDB1_TargetAirGap "as binary IEEE-754
";
CM_ SG_ 260 MDB1_Temperature "as binary IEEE-754";
CM_ SG_ 257 MDB1_AirGap "as binary IEEE-754
";
CM_ BO_ 2684354555 "longitudinal and transverse velocity, angle between them";
CM_ SG_ 2684354555 OpticalSensor_TX_Angle "Angle between longitudianl and transverse direction.";
CM_ SG_ 2684354555 OpticalSensor_TX_VelTrans "Velocity in transverse direction.";
CM_ SG_ 2684354555 OpticalSensor_TX_VelLong "Velocity in longitudinal direction.";
CM_ BO_ 2684354554 "Timestamp, Veocity, Distance";
CM_ SG_ 2684354554 OpticalSensor_TX_Distance "Traveled distance";
CM_ SG_ 2684354554 OpticalSensor_TX_Vel "Absolute velocity";
CM_ BO_ 2684354556 "Timestamp, Veocity, Distance";
CM_ SG_ 2684354556 OpticalSensor_TX_Temp "Temperature of the sensor";
CM_ SG_ 2684354556 OpticalSensor_TX_SerialNo "Serialnumber of the sensor";
CM_ BO_ 2 "CANzero NMT message sent by NMT master.";
CM_ SG_ 2 CANzero_NMT_Node "CANzero NMT Node-ID of master request.";
CM_ SG_ 2 CANzero_NMT_State "CANzero NMT State Request by master.";
CM_ BO_ 122 "CANzero Sync message. Not used yet, just a placeholder for future versions.";
CM_ BO_ 123 "CANzero Timestamp message. Not used yet, just a placeholder for future versions.";
CM_ BO_ 129 "Emergency message of node SensorF with Node-ID 0x1";
CM_ SG_ 129 SensorF_E14_fiducialHighOffset "Fiducial position estimation derived from kistler estimation";
CM_ SG_ 129 SensorF_E13_encoderSpeedError "Error when the meassured speed is prohibited";
CM_ SG_ 129 SensorF_E12_encoderError "Error when something fails in the Wheel encoder.";
CM_ SG_ 129 SensorF_E10_TelemEmergency "Telemtry sent emergency command";
CM_ SG_ 129 SensorF_E9_SWError "State machine plausibility check failed";
CM_ SG_ 129 SensorF_E8_NodeErrorFlag "A nodes error flag was active";
CM_ SG_ 129 SensorF_E7_TelemetryTimeout "Did not respond in set max time";
CM_ SG_ 129 SensorF_E6_SensorRTimeout "Did not respond in set max time";
CM_ SG_ 129 SensorF_E5_HVCUTimeout "Did not respond in set max time";
CM_ SG_ 129 SensorF_E4_PDUTimeout "Did not respond in set max time";
CM_ SG_ 129 SensorF_E3_BrakeRTimeout "Did not respond in set max time";
CM_ SG_ 129 SensorF_E2_BrakeFTimeout "Did not respond in set max time";
CM_ SG_ 129 SensorF_E1_StateMTransitionE "Something went wrong with a transition";
CM_ SG_ 129 SensorF_E0_OtherError "Other error.";
CM_ SG_ 129 SensorF_W2_encoderOORWarning "the position form the wheelencoder is outside the track limits";
CM_ SG_ 129 SensorF_W1_StateMTransitionW "Some transition is about to time out";
CM_ SG_ 129 SensorF_W0_OtherWarning "Other warning.";
CM_ BO_ 385 "Transmit PDO 1 of node SensorF with Node-ID 0x1";
CM_ SG_ 385 SensorF_TX_PodState_Target "Target PodState by State Machine.";
CM_ SG_ 385 SensorF_TX_PodState_Last "Last PodState by State Machine.";
CM_ SG_ 385 SensorF_TX_PodState "PodState by State Machine.";
CM_ BO_ 449 "Receive PDO 1 of node SensorF with Node-ID 0x1";
CM_ BO_ 513 "Data from Encoder front (PDO10)";
CM_ BO_ 577 "Receive PDO 2 of node SensorF with Node-ID 0x1.";
CM_ BO_ 641 "Transmit PDO 3 of node SensorF with Node-ID 0x1";
CM_ BO_ 705 "Receive PDO 3 of node SensorF with Node-ID 0x1.";
CM_ BO_ 769 "Transmit PDO 4 of node SensorF with Node-ID 0x1";
CM_ BO_ 833 "Receive PDO 4 of node SensorF with Node-ID 0x1.";
CM_ BO_ 897 "Transmit PDO 5 of node SensorF with Node-ID 0x1";
CM_ BO_ 961 "Transmit PDO 6 of node SensorF with Node-ID 0x1";
CM_ BO_ 1025 "Transmit PDO 7 of node SensorF with Node-ID 0x1";
CM_ SG_ 1025 SensorF_GyroFront_X "Slope of front IMU in X direction.";
CM_ SG_ 1025 SensorF_Vel_EncoderFront "Velocity of Wheel Encoder front.";
CM_ SG_ 1025 SensorF_Pos_EncoderFront "Position of Wheel Encoder front.";
CM_ BO_ 1089 "Transmit PDO 8 of node SensorF with Node-ID 0x1";
CM_ BO_ 1153 "Transmit PDO 9 of node SensorF with Node-ID 0x1";
CM_ BO_ 1217 "Transmit Acc_X, Acc_Y, Acc_Z and Gyro_Z of front IMU of node SensorF.";
CM_ SG_ 1217 SensorF_GyroFront_Z "Slope of front IMU in Z direction.";
CM_ SG_ 1217 SensorF_AccFront_Z "Acceleration of front IMU in Z direction.";
CM_ SG_ 1217 SensorF_AccFront_Y "Acceleration of front IMU in Y direction.";
CM_ SG_ 1217 SensorF_AccFront_X "Acceleration of front IMU in X direction.";
CM_ BO_ 1281 "SensorF with Node-ID 0x1 (PDO11).";
CM_ BO_ 1345 "Transmit PDO 12 of node SensorF with Node-ID 0x1.";
CM_ BO_ 1409 "DO NOT CHANGE ANYTHING HERE!
SDO Response of node SensorF with Node-ID 0x1";
CM_ SG_ 1409 SensorF_OD_SetReset "Reset the position of the encoder and IMU to zero.";
CM_ SG_ 1409 SensorF_OD_Velocity "Estimated Pod velocity";
CM_ SG_ 1409 SensorF_OD_Position "Estimated Pod position";
CM_ SG_ 1409 SensorF_OD_StripeCount "Fiducial Stripe Counter";
CM_ SG_ 1409 SensorF_OD_MdbState "State of all mdbs if not the same on all mdbs inconsistant.";
CM_ SG_ 1409 SensorF_OD_Magnet_6_Temperature "Magnet_6_Temperature";
CM_ SG_ 1409 SensorF_OD_Magnet_5_Temperature "Magnet_5_Temperature";
CM_ SG_ 1409 SensorF_OD_Magnet_4_Temperature "Magnet_4_Temperature";
CM_ SG_ 1409 SensorF_OD_Magnet_3_Temperature "Magnet_3_Temperature";
CM_ SG_ 1409 SensorF_OD_Magnet_2_Temperature "Magnet_2_Temperature";
CM_ SG_ 1409 SensorF_OD_Magnet_1_Temperature "Magnet_1_Temperature";
CM_ SG_ 1409 SensorF_OD_ReservoirTemperature "Cooling Reservoir Temperature";
CM_ SG_ 1409 SensorF_OD_CoolingPressure "IMU cooling pressure.";
CM_ SG_ 1409 SensorF_OD_IMU_GyroZ "IMU gyro z";
CM_ SG_ 1409 SensorF_OD_IMU_GyroY "IMU gyro y";
CM_ SG_ 1409 SensorF_OD_IMU_GyroX "IMU gyro X";
CM_ SG_ 1409 SensorF_OD_IMU_AccelZ "IMU accel z";
CM_ SG_ 1409 SensorF_OD_IMU_AccelY "IMU accel y";
CM_ SG_ 1409 SensorF_OD_IMU_AccelX "IMU accel X";
CM_ SG_ 1409 SensorF_OD_IMU3_Temperature "Internal temperature of IMU3.";
CM_ SG_ 1409 SensorF_OD_IMU2_Temperature "Internal temperature of IMU2.";
CM_ SG_ 1409 SensorF_OD_IMU1_Temperature "Internal temperature of IMU1.";
CM_ SG_ 1409 SensorF_OD_IMU_number "Number of IMUs that are online.";
CM_ SG_ 1409 SensorF_OD_EncoderResetPosition "Reset the position of the encoder to zero.";
CM_ SG_ 1409 SensorF_OD_EncoderWheelDiameter "Diameter of the encoder wheel in mm.";
CM_ SG_ 1409 SensorF_OD_HVBatteryMode "Switch the HV Battery from discharging to charging mode.";
CM_ SG_ 1409 SensorF_OD_StateMachineActivate "If it is deactivated, then no signals are sent by stateMachine";
CM_ SG_ 1409 SensorF_OD_StateMachineInterval "Interval in milliseconds for the state machine execution.";
CM_ SG_ 1409 SensorF_OD_TelemetryCommands "Commands from Telemetry to State Machine";
CM_ SG_ 1409 SensorF_OD_samplingInterval "Sensor sampling interval in ms.";
CM_ SG_ 1409 SensorF_OD_CAN2_DelayedTxMessage "Number of delayed TX messages on CAN2 because no messagebox was free.";
CM_ SG_ 1409 SensorF_OD_CAN2_ErrorStatus "Internal error status (e.g. Error active, Error passive, Bus Off)";
CM_ SG_ 1409 SensorF_OD_CAN2_DiscardedTxMessa "Number of discarded TX messages on CAN2 because all messageboxes were full";
CM_ SG_ 1409 SensorF_OD_CAN2_Status "Status of CAN2.";
CM_ SG_ 1409 SensorF_OD_CAN2_Baudrate "Baudrate of CAN.";
CM_ SG_ 1409 SensorF_OD_CAN2_autoErrorReset "Automatic reset of errors.";
CM_ SG_ 1409 SensorF_OD_CAN2_lastErrorCode "Last error code.";
CM_ SG_ 1409 SensorF_OD_CAN2_RxErrCnt "Receive error count of CAN1.";
CM_ SG_ 1409 SensorF_OD_CAN2_TxErrCnt "Transmit error count of CAN1.";
CM_ SG_ 1409 SensorF_OD_CAN1_DelayedTxMessage "Number of delayed TX messages on CAN1 because no messagebox was free.";
CM_ SG_ 1409 SensorF_OD_CAN1_ErrorStatus "Internal error status (e.g. Error active, Error passive, Bus Off)";
CM_ SG_ 1409 SensorF_OD_CAN1_DiscardedTxMessa "Number of discarded TX messages on CAN1 because all messageboxes were full";
CM_ SG_ 1409 SensorF_OD_CAN1_Status "Status of CAN1.";
CM_ SG_ 1409 SensorF_OD_CAN1_Baudrate "Baudrate of CAN.";
CM_ SG_ 1409 SensorF_OD_CAN1_autoErrorReset "Automatic reset of errors.";
CM_ SG_ 1409 SensorF_OD_CAN1_lastErrorCode "Last error code.";
CM_ SG_ 1409 SensorF_OD_CAN1_RxErrCnt "Receive error count of CAN1.";
CM_ SG_ 1409 SensorF_OD_CAN1_TxErrCnt "Transmit error count of CAN1.";
CM_ SG_ 1409 SensorF_OD_BuildTime "Software build time in the format HHMMSS.";
CM_ SG_ 1409 SensorF_OD_BuildDate "Software build date in the format YYYYMMDD.";
CM_ SG_ 1409 SensorF_OD_ChipUID2 "Seccond part of unique ID of microcontroller.";
CM_ SG_ 1409 SensorF_OD_ChipUID1 "First part of unique ID of microcontroller.";
CM_ SG_ 1409 SensorF_OD_SdcOut "Measurement of Shutdown Circuit Output";
CM_ SG_ 1409 SensorF_OD_SdcIn "Measurement of Shutdown Circuit Input";
CM_ SG_ 1409 SensorF_OD_runtime "Runtime of chip in milliseconds.";
CM_ SG_ 1409 SensorF_OD_InputVoltage "Board supply voltage.";
CM_ SG_ 1409 SensorF_OD_BoardTemp "Temperature of board";
CM_ SG_ 1409 SensorF_OD_MemFree "Free memory in bytes.";
CM_ SG_ 1409 SensorF_OD_CpuUsage "Current CPU usage in %.";
CM_ SG_ 1409 SensorF_OD_OdEntrySendInterval "Interval for sending all readable OD entries. Sending is disabled if less than 5 ms.";
CM_ SG_ 1409 SensorF_OD_SendOdOnBootup "Whether to send all OD entries on bootup.";
CM_ SG_ 1409 SensorF_OD_HeartbeatInterval "Heartbeat Interval in milliseconds.";
CM_ SG_ 1409 SensorF_OD_DbcVersion "CANzero DBC version.";
CM_ SG_ 1409 SensorF_OD_StackVersion "CANzero stack version.";
CM_ SG_ 1409 SensorF_OD_ProtocolVersion "CANzero Protocol Version.";
CM_ SG_ 1409 SensorF_OD_NodeStatus "State of the node.";
CM_ SG_ 1409 SensorF_OD_NodeID "CANzero Node-ID.";
CM_ SG_ 1409 SensorF_SDO_RespCode "Response code of SDO access.";
CM_ SG_ 1409 SensorF_SDO_ID "Specifies SDO-ID of SensorF";
CM_ BO_ 1473 "DO NOT CHANGE ANYTHING HERE!
SDO Request Upload to node SensorF with Node-ID 0x1";
CM_ SG_ 1473 SensorF_OD_SetReset "Reset the position of the encoder and IMU to zero.";
CM_ SG_ 1473 SensorF_OD_Velocity "Estimated Pod velocity";
CM_ SG_ 1473 SensorF_OD_Position "Estimated Pod position";
CM_ SG_ 1473 SensorF_OD_StripeCount "Fiducial Stripe Counter";
CM_ SG_ 1473 SensorF_OD_MdbState "State of all mdbs if not the same on all mdbs inconsistant.";
CM_ SG_ 1473 SensorF_OD_Magnet_6_Temperature "Magnet_6_Temperature";
CM_ SG_ 1473 SensorF_OD_Magnet_5_Temperature "Magnet_5_Temperature";
CM_ SG_ 1473 SensorF_OD_Magnet_4_Temperature "Magnet_4_Temperature";
CM_ SG_ 1473 SensorF_OD_Magnet_3_Temperature "Magnet_3_Temperature";
CM_ SG_ 1473 SensorF_OD_Magnet_2_Temperature "Magnet_2_Temperature";
CM_ SG_ 1473 SensorF_OD_Magnet_1_Temperature "Magnet_1_Temperature";
CM_ SG_ 1473 SensorF_OD_ReservoirTemperature "Cooling Reservoir Temperature";
CM_ SG_ 1473 SensorF_OD_CoolingPressure "IMU cooling pressure.";
CM_ SG_ 1473 SensorF_OD_IMU_GyroZ "IMU gyro z";
CM_ SG_ 1473 SensorF_OD_IMU_GyroY "IMU gyro y";
CM_ SG_ 1473 SensorF_OD_IMU_GyroX "IMU gyro X";
CM_ SG_ 1473 SensorF_OD_IMU_AccelZ "IMU accel z";
CM_ SG_ 1473 SensorF_OD_IMU_AccelY "IMU accel y";
CM_ SG_ 1473 SensorF_OD_IMU_AccelX "IMU accel X";
CM_ SG_ 1473 SensorF_OD_IMU3_Temperature "Internal temperature of IMU3.";
CM_ SG_ 1473 SensorF_OD_IMU2_Temperature "Internal temperature of IMU2.";
CM_ SG_ 1473 SensorF_OD_IMU1_Temperature "Internal temperature of IMU1.";
CM_ SG_ 1473 SensorF_OD_IMU_number "Number of IMUs that are online.";
CM_ SG_ 1473 SensorF_OD_EncoderResetPosition "Reset the position of the encoder to zero.";
CM_ SG_ 1473 SensorF_OD_EncoderWheelDiameter "Diameter of the encoder wheel in mm.";
CM_ SG_ 1473 SensorF_OD_HVBatteryMode "Switch the HV Battery from discharging to charging mode.";
CM_ SG_ 1473 SensorF_OD_StateMachineActivate "If it is deactivated, then no signals are sent by stateMachine";
CM_ SG_ 1473 SensorF_OD_StateMachineInterval "Interval in milliseconds for the state machine execution.";
CM_ SG_ 1473 SensorF_OD_TelemetryCommands "Commands from Telemetry to State Machine";
CM_ SG_ 1473 SensorF_OD_samplingInterval "Sensor sampling interval in ms.";
CM_ SG_ 1473 SensorF_OD_CAN2_DelayedTxMe_0000 "Number of delayed TX messages on CAN2 because no messagebox was free.";
CM_ SG_ 1473 SensorF_OD_CAN2_ErrorStatus "Internal error status (e.g. Error active, Error passive, Bus Off)";
CM_ SG_ 1473 SensorF_OD_CAN2_DiscardedTx_0000 "Number of discarded TX messages on CAN2 because all messageboxes were full";
CM_ SG_ 1473 SensorF_OD_CAN2_Status "Status of CAN2.";
CM_ SG_ 1473 SensorF_OD_CAN2_Baudrate "Baudrate of CAN.";
CM_ SG_ 1473 SensorF_OD_CAN2_autoErrorReset "Automatic reset of errors.";
CM_ SG_ 1473 SensorF_OD_CAN2_lastErrorCode "Last error code.";
CM_ SG_ 1473 SensorF_OD_CAN2_RxErrCnt "Receive error count of CAN1.";
CM_ SG_ 1473 SensorF_OD_CAN2_TxErrCnt "Transmit error count of CAN1.";
CM_ SG_ 1473 SensorF_OD_CAN1_DelayedTxMe_0000 "Number of delayed TX messages on CAN1 because no messagebox was free.";
CM_ SG_ 1473 SensorF_OD_CAN1_ErrorStatus "Internal error status (e.g. Error active, Error passive, Bus Off)";
CM_ SG_ 1473 SensorF_OD_CAN1_DiscardedTx_0000 "Number of discarded TX messages on CAN1 because all messageboxes were full";
CM_ SG_ 1473 SensorF_OD_CAN1_Status "Status of CAN1.";
CM_ SG_ 1473 SensorF_OD_CAN1_Baudrate "Baudrate of CAN.";
CM_ SG_ 1473 SensorF_OD_CAN1_autoErrorReset "Automatic reset of errors.";
CM_ SG_ 1473 SensorF_OD_CAN1_lastErrorCode "Last error code.";
CM_ SG_ 1473 SensorF_OD_CAN1_RxErrCnt "Receive error count of CAN1.";
CM_ SG_ 1473 SensorF_OD_CAN1_TxErrCnt "Transmit error count of CAN1.";
CM_ SG_ 1473 SensorF_OD_BuildTime "Software build time in the format HHMMSS.";
CM_ SG_ 1473 SensorF_OD_BuildDate "Software build date in the format YYYYMMDD.";
CM_ SG_ 1473 SensorF_OD_ChipUID2 "Seccond part of unique ID of microcontroller.";
CM_ SG_ 1473 SensorF_OD_ChipUID1 "First part of unique ID of microcontroller.";
CM_ SG_ 1473 SensorF_OD_SdcOut "Measurement of Shutdown Circuit Output";
CM_ SG_ 1473 SensorF_OD_SdcIn "Measurement of Shutdown Circuit Input";
CM_ SG_ 1473 SensorF_OD_runtime "Runtime of chip in milliseconds.";
CM_ SG_ 1473 SensorF_OD_InputVoltage "Board supply voltage.";
CM_ SG_ 1473 SensorF_OD_BoardTemp "Temperature of board";
CM_ SG_ 1473 SensorF_OD_MemFree "Free memory in bytes.";
CM_ SG_ 1473 SensorF_OD_CpuUsage "Current CPU usage in %.";
CM_ SG_ 1473 SensorF_OD_OdEntrySendInterval "Interval for sending all readable OD entries. Sending is disabled if less than 5 ms.";
CM_ SG_ 1473 SensorF_OD_SendOdOnBootup "Whether to send all OD entries on bootup.";
CM_ SG_ 1473 SensorF_OD_HeartbeatInterval "Heartbeat Interval in milliseconds.";
CM_ SG_ 1473 SensorF_OD_DbcVersion "CANzero DBC version.";
CM_ SG_ 1473 SensorF_OD_StackVersion "CANzero stack version.";
CM_ SG_ 1473 SensorF_OD_ProtocolVersion "CANzero Protocol Version.";
CM_ SG_ 1473 SensorF_OD_NodeStatus "State of the node.";
CM_ SG_ 1473 SensorF_OD_NodeID "CANzero Node-ID.";
CM_ SG_ 1473 SensorF_SDO_ID "Specifies SDO-ID of SensorF";
CM_ BO_ 1537 "DO NOT CHANGE ANYTHING HERE!
SDO Request Download from node SensorF with Node-ID 0x1";
CM_ SG_ 1537 SensorF_SDO_ID "Specifies SDO-ID of SensorF";
CM_ BO_ 1793 "Heartbeat of node SensorF with Node-ID 0x1";
CM_ SG_ 1793 SensorF_NodeState "Heartbeat status of node SensorF";
CM_ BO_ 1857 "Bootloader transmit from node SensorF with Node-ID 0x1";
CM_ BO_ 1921 "Bootloader receive by node SensorF with Node-ID 0x1";
CM_ BO_ 130 "Emergency message of node SensorR with Node-ID 0x2";
CM_ SG_ 130 SensorR_E12_highLIMTemperature "Error when motor temperature is too high.";
CM_ SG_ 130 SensorR_E11_scimoPEerror101overc "Current of a single phase too high (for more than 4 samples).";
CM_ SG_ 130 SensorR_E10_scimoPEerror103sumcu "Sum of the phase current too high.";
CM_ SG_ 130 SensorR_E9_scimoPEerror102overcu "Current of a single phase too high (for more than 4 samples).";
CM_ SG_ 130 SensorR_E8_scimoPEerror024motTem "Error if motor temperature too high.";
CM_ SG_ 130 SensorR_E7_scimoPEerror020uZKmin "Error if intermediate circuit voltage too low.";
CM_ SG_ 130 SensorR_E6_scimoPEerror009Pulslo "Error if hardware enable not given.";
CM_ SG_ 130 SensorR_E5_accEmergencyStop "The acceleration can not be measured directly by any sensor";
CM_ SG_ 130 SensorR_E4_velEmergencyStop "The velocity can not be measured directly by any sensor";
CM_ SG_ 130 SensorR_E3_posEmergencyStop "The position can not be measured directly by any sensor";
CM_ SG_ 130 SensorR_E2_stripeEmergencyStop "PlausibilitxCheck goes wrong, the position is not wiithin the range of the stripes";
CM_ SG_ 130 SensorR_E1_trajectoryError "Error when they Trajectory differs to much from the setpoint.";
CM_ SG_ 130 SensorR_E0_OtherError "Other error.";
CM_ SG_ 130 SensorR_W10_highLIMTemperature "Warning when motor temperature is too high. FIXME";
CM_ SG_ 130 SensorR_W9_restrictingVelocity "Warning when required velocity is higher than allowed. FIXME";
CM_ SG_ 130 SensorR_W8_outOfLimModelBoundari "Warning when required thrust force is large and acceleration has a different sign. FIXME";
CM_ SG_ 130 SensorR_W7_highOscillations "Warning when high oscillations occur. FIXME";
CM_ SG_ 130 SensorR_W6_sciMoPEwarning104FETt "High temperature of FETs.";
CM_ SG_ 130 SensorR_W5_sciMoPEwarning069CPUt "High temperature of PE controller CPU.";
CM_ SG_ 130 SensorR_W4_stateEstimationAccWar "One acceleration measurement is out of range";
CM_ SG_ 130 SensorR_W3_stateEstimationPosWar "One position measurement is out of range";
CM_ SG_ 130 SensorR_W2_stateEstimationVelWar "One velocity measurement is out of range";
CM_ SG_ 130 SensorR_W1_stripeWarning "Warning when the measured position is not within the half allowed distance of the two nearest stripes";
CM_ SG_ 130 SensorR_W0_OtherWarning "Other warning.";
CM_ BO_ 386 "Transmit PDO 1 of node SensorR with Node-ID 0x2. Data of front IMU.";
CM_ SG_ 386 SensorR_TX_GyroFront_Z "Slope of front IMU in Z direction.";
CM_ SG_ 386 SensorR_TX_AccFront_Z "Acceleration of front IMU in Z direction.";
CM_ SG_ 386 SensorR_TX_AccFront_Y "Acceleration of front IMU in Y direction.";
CM_ SG_ 386 SensorR_TX_AccFront_X "Acceleration of front IMU in X direction.";
CM_ BO_ 514 "Transmit PDO 2 of node SensorR with Node-ID 0x2. RunState, Enabled, ErrorFlag, TrajectorySet";
CM_ SG_ 514 SensorR_TX_ErrorFlag "Error status of SensorR.";
CM_ SG_ 514 SensorR_TX_Enabled "Enable status of SensorR.";
CM_ SG_ 514 SensorR_TX_TrajectorySet "Flag for trajectorySet";
CM_ SG_ 514 SensorR_TX_RunState "State of run of SensorR.";
CM_ BO_ 578 "Receive PDO 2 of node SensorR with Node-ID 0x2.";
CM_ BO_ 642 "Transmit PDO 3 of node SensorR with Node-ID 0x2. Filtered data after StateEstimation";
CM_ SG_ 642 SensorR_TX_Pos "Filtered position by StateEstimation.";
CM_ SG_ 642 SensorR_TX_Vel "Filtered velocity by StateEstimation.";
CM_ SG_ 642 SensorR_TX_Acc "Filtered acceleration by StateEstimation.";
CM_ BO_ 706 "Receive PDO 3 of node SensorR with Node-ID 0x2";
CM_ SG_ 706 SensorR_RX_ErrorReset "Error reset signal for SensorR.";
CM_ SG_ 706 SensorR_RX_Enable "Enable signal for SensorR.";
CM_ SG_ 706 SensorR_RX_LaunchComm "Launch Command of SensorR.";
CM_ BO_ 770 "Transmit PDO 4 of node SensorR with Node-ID 0x2. Velocity of EncoderFront, rear and optical, Stripes";
CM_ SG_ 770 SensorR_TX_Vel_Optical "Velocity of optical Sensor.";
CM_ SG_ 770 SensorR_TX_Vel_EncoderRear "Velocity of Wheel Encoder rear.";
CM_ SG_ 770 SensorR_TX_Vel_EncoderFront "Velocity of Wheel Encoder front.";
CM_ BO_ 834 "Receive PDO 4 of node SensorR with Node-ID 0x2.";
CM_ BO_ 898 "Transmit PDO 5 of node SensorR with Node-ID 0x2. Gyroscope data of IMU front and rear in X and Y direction.";
CM_ SG_ 898 SensorR_TX_GyroRear_Y "Slope of rear IMU in Y direction.";
CM_ SG_ 898 SensorR_TX_GyroRear_X "Slope of rear IMU in X direction.";
CM_ SG_ 898 SensorR_TX_GyroFront_Y "Slope of front IMU in Y direction.";
CM_ SG_ 898 SensorR_TX_GyroFront_X "Slope of front IMU in X direction.";
CM_ BO_ 962 "Transmit PDO 6 of node SensorR with Node-ID 0x2";
CM_ BO_ 1026 "Transmit PDO 7 of node SensorR with Node-ID 0x2. Gap Height of left and right sensor.";
CM_ SG_ 1026 SensorR_TX_GapHeight_Right "Gap height of LIM right.";
CM_ SG_ 1026 SensorR_TX_GapHeight_Left "Gap height of LIM left.";
CM_ BO_ 1090 "Transmit PDO 8 of node SensorR with Node-ID 0x2";
CM_ BO_ 1154 "Transmit PDO 9 of node SensorR with Node-ID 0x2";
CM_ BO_ 1218 "Transmit PDO 10 of node SensorR with Node-ID 0x2. Send acceleration of IMU Rear.";
CM_ SG_ 1218 SensorR_TX_GyroRear_Z "Slope of rear IMU in Z direction.";
CM_ SG_ 1218 SensorR_TX_AccRear_Z "Acceleration of rear IMU in Z direction.";
CM_ SG_ 1218 SensorR_TX_AccRear_Y "Acceleration of rear IMU in Y direction.";
CM_ SG_ 1218 SensorR_TX_AccRear_X "Acceleration of rear IMU in X direction.";
CM_ BO_ 1282 "Transmit PDO 11 of node SensorR with Node-ID 0x2. Send position data of Encoder front, rear and optical and Stripes.";
CM_ SG_ 1282 SensorR_TX_StripeCounter_Right "Counting reflectors on the right site.";
CM_ SG_ 1282 SensorR_TX_StripeCounter_Left "Counting reflectors on the left site.";
CM_ SG_ 1282 SensorR_TX_Pos_Optical "Position of optical Sensor.";
CM_ SG_ 1282 SensorR_TX_Pos_EncoderRear "Position of Wheel Encoder rear.";
CM_ SG_ 1282 SensorR_TX_Pos_EncoderFront "Position of Wheel Encoder front.";
CM_ BO_ 1346 "Transmit PDO 12 of node SensorR with Node-ID 0x2.";
CM_ BO_ 1410 "DO NOT CHANGE ANYTHING HERE!
SDO Response of node SensorR with Node-ID 0x2";
CM_ SG_ 1410 SensorR_OD_posDeviationOptic "allowed deviation of position measurment of optical sensor";
CM_ SG_ 1410 SensorR_OD_posDeviationEncoder "allowed deviation of position measurment of encoders";
CM_ SG_ 1410 SensorR_OD_velDeviationOptic "allowed deviation of velocity measurment of optical sensor";
CM_ SG_ 1410 SensorR_OD_velDeviationEncoder "allowed deviation of velocity measurment of encoders";
CM_ SG_ 1410 SensorR_OD_accDeviation "allowed deviation of IMUs";
CM_ SG_ 1410 SensorR_OD_EnableSignalGeneratio "enable signalgeneration for testing SE";
CM_ SG_ 1410 SensorR_OD_PositionGlitch "allowed difference in m between estimated pod position and stripe position";
CM_ SG_ 1410 SensorR_OD_ReflectorDistance "distance between 2 reflectors in m";
CM_ SG_ 1410 SensorR_OD_StripeMode "0 means left, 1 means right, 2 means both";
CM_ SG_ 1410 SensorR_OD_opc_lowpass_TcI "timeconstant of PT1 for current adjustment of OPC";
CM_ SG_ 1410 SensorR_OD_opc_lowpass_Tcf "timeconstant of PT1 for frequency adjustment of OPC";
CM_ SG_ 1410 SensorR_OD_opc_F_decrease "parameter of how quickly force is decreased while breaking";
CM_ SG_ 1410 SensorR_OD_opc_v_threshold "Velocity when to reduce to current. FIXME Add parameter how much to reduce the current.";
CM_ SG_ 1410 SensorR_OD_opc_v_max "Velocity when to stop accelerating.";
CM_ SG_ 1410 SensorR_OD_opc_T_acc "Time to accelerate.";
CM_ SG_ 1410 SensorR_OD_opc_F_max "Maximum force to set for acceleration. (Is internally used as a maximum current.)";
CM_ SG_ 1410 SensorR_OD_opc_t_run_max "Max time to check the flip flop";
CM_ SG_ 1410 SensorR_OD_opc_brakeFlag "Manual setting of brakes flag.";
CM_ SG_ 1410 SensorR_OD_DebugCVOPCfreq "Debugging";
CM_ SG_ 1410 SensorR_OD_DebugCascadedIreq "Debugging";
CM_ SG_ 1410 SensorR_OD_opc_ratelimiter_f "Rate Limiter Freq.";
CM_ SG_ 1410 SensorR_OD_maxRunDistance "Estimated run length based on the velocity profile.";
CM_ SG_ 1410 SensorR_OD_FinishedDelay "Time to stay in launching mode after end of trajectory..";
CM_ SG_ 1410 SensorR_OD_Current4Stopping "Current set for stopping (in A).";
CM_ SG_ 1410 SensorR_OD_AdaptModelByCurrent "Select whether to use the measured current to adapt the model.";
CM_ SG_ 1410 SensorR_OD_CVOPCTcFreq "Lowpass filter constant of F_req.";
CM_ SG_ 1410 SensorR_OD_CVOPCImin "Minimum current for current varied OPC.";
CM_ SG_ 1410 SensorR_OD_CascadedKpDecreaseCur "Specify the factor to decreae current (in A/s).";
CM_ SG_ 1410 SensorR_OD_CascadedKpIncreaseCur "Specify the factor to increase current (in A/s).";
CM_ SG_ 1410 SensorR_OD_CascadedFreqCurUpdate "Specify how often to update the required current in the cascaded control.";
CM_ SG_ 1410 SensorR_OD_CascadedMaxSetForceDe "Specify the max force delta when no current is modified.";
CM_ SG_ 1410 SensorR_OD_CurrentForConstantVel "Current for cruising (in FFCC).";
CM_ SG_ 1410 SensorR_OD_AccAtCurrentMeasured "Acceleration with a specified constant current (Default 230 / 3=76.7) (FFCVOPC).";
CM_ SG_ 1410 SensorR_OD_CVOPCHystereseF "Specify the Hysterese amplitude when to change for acc or dec.";
CM_ SG_ 1410 SensorR_OD_CVOPCReduceCurrentWhi "Specify by which factor to reduce the const current while cruising with const current control.";
CM_ SG_ 1410 SensorR_OD_CVOPCDeltaVelHigherCu "Specify at which absolute velocity error the higher current should be selected (although v_req = const).";
CM_ SG_ 1410 SensorR_OD_CVOPCSmoothingDeltaVe "Specify at which velocity deviation stronger low pass filtering should end. FIXME Do not use a hard boundary.";
CM_ SG_ 1410 SensorR_OD_CVOPCTcI "Lowpass filter constant of current (for CVOPC and FFCVOPC).";
CM_ SG_ 1410 SensorR_OD_CVOPCTcf "Lowpass filter constant of frequency.";
CM_ SG_ 1410 SensorR_OD_CVOPCImax "Maximum current for current varied OPC.";
CM_ SG_ 1410 SensorR_OD_VelocityController "Select which velocity controller to choose (CC ConstantCurrent, CVFF CurrentVariedFeedForward, CVFB VariedCurrentFeedBack, CAS Cascaded)";
CM_ SG_ 1410 SensorR_OD_TC_f "Time constant for the required frequency.";
CM_ SG_ 1410 SensorR_OD_TC_I "Time constant for the required current.";
CM_ SG_ 1410 SensorR_OD_EstimatedRunLength "Estimated run length based on the velocity profile.";
CM_ SG_ 1410 SensorR_OD_RunProfile_V4 "Velocity for the fith point in the velocity profile.";
CM_ SG_ 1410 SensorR_OD_RunProfile_T4 "Time for the fith point in the velocity profile.";
CM_ SG_ 1410 SensorR_OD_RunProfile_V3 "Velocity for the forth point in the velocity profile.";
CM_ SG_ 1410 SensorR_OD_RunProfile_T3 "Time for the forth point in the velocity profile.";
CM_ SG_ 1410 SensorR_OD_RunProfile_V2 "Velocity for the third point in the velocity profile.";
CM_ SG_ 1410 SensorR_OD_RunProfile_T2 "Time for the third point in the velocity profile.";
CM_ SG_ 1410 SensorR_OD_RunProfile_V1 "Velocity for the second point in the velocity profile.";
CM_ SG_ 1410 SensorR_OD_RunProfile_T1 "Time for the second point in the velocity profile.";
CM_ SG_ 1410 SensorR_OD_RunProfile_V0 "Velocity for the first point in the velocity profile.";
CM_ SG_ 1410 SensorR_OD_RunProfile_T0 "Time for the first point in the velocity profile.";
CM_ SG_ 1410 SensorR_OD_SetFinish "Manual setting of finished flag.";
CM_ SG_ 1410 SensorR_OD_RunMode "Whether to do dynamic run (0), levitation (1) or manual control (2).";
CM_ SG_ 1410 SensorR_OD_VdcReduceFactor "Factor to tune Vdc.";
CM_ SG_ 1410 SensorR_OD_MaxRequiredVelocity "Maximum required velocity the OPC accepts.";
CM_ SG_ 1410 SensorR_OD_WarningThreshholdForL "Time where deviation from the required velocity is considered.";
CM_ SG_ 1410 SensorR_OD_MaxCtrlErrorDuration "Time where deviation from the required velocity is considered. (Done by high level control.) FIXME";
CM_ SG_ 1410 SensorR_OD_MaxCtrlError "Maximum deviation from the required velocity for a specified time. (Done by high level control.) FIXME";
CM_ SG_ 1410 SensorR_OD_FminCtrl "Force saturation in OPC (lower boundary). Scaled by (-1). 922 is maximum.";
CM_ SG_ 1410 SensorR_OD_FmaxCtrl "Force saturation in OPC (upper boundary). 1004 is maximum.";
CM_ SG_ 1410 SensorR_OD_PodMass "Mass of pod.";
CM_ SG_ 1410 SensorR_OD_CurrentReq "Required current for LIM (AC RMS coil current controlled by current controller).";
CM_ SG_ 1410 SensorR_OD_CtrlMode "Whether to use V-control (0) or I-control (1).";
CM_ SG_ 1410 SensorR_OD_OpcKi "Integrator gain for OPC.";
CM_ SG_ 1410 SensorR_OD_OpcKp "Product gain for OPC.";
CM_ SG_ 1410 SensorR_OD_ExecTimeReadSensors "Execution time of the sensor readings in milliseconds.";
CM_ SG_ 1410 SensorR_OD_ExecTimeControl "Execution time of the control in milliseconds.";
CM_ SG_ 1410 SensorR_OD_ExecTimeStateEst "Execution time of the State Estimation in milliseconds.";
CM_ SG_ 1410 SensorR_OD_ExecTimeOverall "Execution time of the whole TrajectoryControl task.";
CM_ SG_ 1410 SensorR_OD_IMU3_Temperature "Internal temperature of IMU3.";
CM_ SG_ 1410 SensorR_OD_IMU2_Temperature "Internal temperature of IMU2.";
CM_ SG_ 1410 SensorR_OD_IMU1_Temperature "Internal temperature of IMU1.";
CM_ SG_ 1410 SensorR_OD_IMU_number "Number of IMUs that are online.";
CM_ SG_ 1410 SensorR_OD_EncoderResetPosition "Reset the position of the encoder to zero.";
CM_ SG_ 1410 SensorR_OD_EncoderWheelDiameter "Diameter of the encoder wheel in mm.";
CM_ SG_ 1410 SensorR_OD_samplingInterval "Sensor sampling interval in ms.";
CM_ SG_ 1410 SensorR_OD_CAN2_DelayedTxMessage "Number of delayed TX messages on CAN2 because no messagebox was free.";
CM_ SG_ 1410 SensorR_OD_CAN2_ErrorStatus "Internal error status (e.g. Error active, Error passive, Bus Off)";
CM_ SG_ 1410 SensorR_OD_CAN2_DiscardedTxMessa "Number of discarded TX messages on CAN2 because all messageboxes were full";
CM_ SG_ 1410 SensorR_OD_CAN2_Status "Status of CAN2.";
CM_ SG_ 1410 SensorR_OD_CAN2_Baudrate "Baudrate of CAN.";
CM_ SG_ 1410 SensorR_OD_CAN2_autoErrorReset "Automatic reset of errors.";
CM_ SG_ 1410 SensorR_OD_CAN2_lastErrorCode "Last error code.";
CM_ SG_ 1410 SensorR_OD_CAN2_RxErrCnt "Receive error count of CAN1.";
CM_ SG_ 1410 SensorR_OD_CAN2_TxErrCnt "Transmit error count of CAN1.";
CM_ SG_ 1410 SensorR_OD_CAN1_DelayedTxMessage "Number of delayed TX messages on CAN1 because no messagebox was free.";
CM_ SG_ 1410 SensorR_OD_CAN1_ErrorStatus "Internal error status (e.g. Error active, Error passive, Bus Off)";
CM_ SG_ 1410 SensorR_OD_CAN1_DiscardedTxMessa "Number of discarded TX messages on CAN1 because all messageboxes were full";
CM_ SG_ 1410 SensorR_OD_CAN1_Status "Status of CAN1.";
CM_ SG_ 1410 SensorR_OD_CAN1_Baudrate "Baudrate of CAN.";
CM_ SG_ 1410 SensorR_OD_CAN1_autoErrorReset "Automatic reset of errors.";
CM_ SG_ 1410 SensorR_OD_CAN1_lastErrorCode "Last error code.";
CM_ SG_ 1410 SensorR_OD_CAN1_RxErrCnt "Receive error count of CAN1.";
CM_ SG_ 1410 SensorR_OD_CAN1_TxErrCnt "Transmit error count of CAN1.";
CM_ SG_ 1410 SensorR_OD_BuildTime "Software build time in the format HHMMSS.";
CM_ SG_ 1410 SensorR_OD_BuildDate "Software build date in the format YYYYMMDD.";
CM_ SG_ 1410 SensorR_OD_ChipUID2 "Seccond part of unique ID of microcontroller.";
CM_ SG_ 1410 SensorR_OD_ChipUID1 "First part of unique ID of microcontroller.";
CM_ SG_ 1410 SensorR_OD_SdcOut "Measurement of Shutdown Circuit Output";
CM_ SG_ 1410 SensorR_OD_SdcIn "Measurement of Shutdown Circuit Input";
CM_ SG_ 1410 SensorR_OD_runtime "Runtime of chip in milliseconds.";
CM_ SG_ 1410 SensorR_OD_InputVoltage "Board supply voltage.";
CM_ SG_ 1410 SensorR_OD_BoardTemp "Temperature of board";
CM_ SG_ 1410 SensorR_OD_MemFree "Free memory in bytes.";
CM_ SG_ 1410 SensorR_OD_CpuUsage "Current CPU usage in %.";
CM_ SG_ 1410 SensorR_OD_OdEntrySendInterval "Interval for sending all readable OD entries. Sending is disabled if less than 5 ms.";
CM_ SG_ 1410 SensorR_OD_SendOdOnBootup "Whether to send all OD entries on bootup.";
CM_ SG_ 1410 SensorR_OD_HeartbeatInterval "Heartbeat Interval in milliseconds.";
CM_ SG_ 1410 SensorR_OD_DbcVersion "CANzero DBC version.";
CM_ SG_ 1410 SensorR_OD_StackVersion "CANzero stack version.";
CM_ SG_ 1410 SensorR_OD_ProtocolVersion "CANzero Protocol Version.";
CM_ SG_ 1410 SensorR_OD_NodeStatus "State of the node.";
CM_ SG_ 1410 SensorR_OD_NodeID "CANzero Node-ID.";
CM_ SG_ 1410 SensorR_SDO_RespCode "Response code of SDO access.";
CM_ SG_ 1410 SensorR_SDO_ID "Specifies SDO-ID of SensorR";
CM_ BO_ 1474 "DO NOT CHANGE ANYTHING HERE!
SDO Request Upload to node SensorR with Node-ID 0x2";
CM_ SG_ 1474 SensorR_OD_posDeviationOptic "allowed deviation of position measurment of optical sensor";
CM_ SG_ 1474 SensorR_OD_posDeviationEncoder "allowed deviation of position measurment of encoders";
CM_ SG_ 1474 SensorR_OD_velDeviationOptic "allowed deviation of velocity measurment of optical sensor";
CM_ SG_ 1474 SensorR_OD_velDeviationEncoder "allowed deviation of velocity measurment of encoders";
CM_ SG_ 1474 SensorR_OD_accDeviation "allowed deviation of IMUs";
CM_ SG_ 1474 SensorR_OD_EnableSignalGene_0000 "enable signalgeneration for testing SE";
CM_ SG_ 1474 SensorR_OD_PositionGlitch "allowed difference in m between estimated pod position and stripe position";
CM_ SG_ 1474 SensorR_OD_ReflectorDistance "distance between 2 reflectors in m";
CM_ SG_ 1474 SensorR_OD_StripeMode "0 means left, 1 means right, 2 means both";
CM_ SG_ 1474 SensorR_OD_opc_lowpass_TcI "timeconstant of PT1 for current adjustment of OPC";
CM_ SG_ 1474 SensorR_OD_opc_lowpass_Tcf "timeconstant of PT1 for frequency adjustment of OPC";
CM_ SG_ 1474 SensorR_OD_opc_F_decrease "parameter of how quickly force is decreased while breaking";
CM_ SG_ 1474 SensorR_OD_opc_v_threshold "Velocity when to reduce to current. FIXME Add parameter how much to reduce the current.";
CM_ SG_ 1474 SensorR_OD_opc_v_max "Velocity when to stop accelerating.";
CM_ SG_ 1474 SensorR_OD_opc_T_acc "Time to accelerate.";
CM_ SG_ 1474 SensorR_OD_opc_F_max "Maximum force to set for acceleration. (Is internally used as a maximum current.)";
CM_ SG_ 1474 SensorR_OD_opc_t_run_max "Max time to check the flip flop";
CM_ SG_ 1474 SensorR_OD_opc_brakeFlag "Manual setting of brakes flag.";
CM_ SG_ 1474 SensorR_OD_DebugCVOPCfreq "Debugging";
CM_ SG_ 1474 SensorR_OD_DebugCascadedIreq "Debugging";
CM_ SG_ 1474 SensorR_OD_opc_ratelimiter_f "Rate Limiter Freq.";
CM_ SG_ 1474 SensorR_OD_maxRunDistance "Estimated run length based on the velocity profile.";
CM_ SG_ 1474 SensorR_OD_FinishedDelay "Time to stay in launching mode after end of trajectory..";
CM_ SG_ 1474 SensorR_OD_Current4Stopping "Current set for stopping (in A).";
CM_ SG_ 1474 SensorR_OD_AdaptModelByCurrent "Select whether to use the measured current to adapt the model.";
CM_ SG_ 1474 SensorR_OD_CVOPCTcFreq "Lowpass filter constant of F_req.";
CM_ SG_ 1474 SensorR_OD_CVOPCImin "Minimum current for current varied OPC.";
CM_ SG_ 1474 SensorR_OD_CascadedKpDecrea_0000 "Specify the factor to decreae current (in A/s).";
CM_ SG_ 1474 SensorR_OD_CascadedKpIncrea_0000 "Specify the factor to increase current (in A/s).";
CM_ SG_ 1474 SensorR_OD_CascadedFreqCurUpdate "Specify how often to update the required current in the cascaded control.";
CM_ SG_ 1474 SensorR_OD_CascadedMaxSetFo_0000 "Specify the max force delta when no current is modified.";
CM_ SG_ 1474 SensorR_OD_CurrentForConsta_0000 "Current for cruising (in FFCC).";
CM_ SG_ 1474 SensorR_OD_AccAtCurrentMeasured "Acceleration with a specified constant current (Default 230 / 3=76.7) (FFCVOPC).";
CM_ SG_ 1474 SensorR_OD_CVOPCHystereseF "Specify the Hysterese amplitude when to change for acc or dec.";
CM_ SG_ 1474 SensorR_OD_CVOPCReduceCurre_0000 "Specify by which factor to reduce the const current while cruising with const current control.";
CM_ SG_ 1474 SensorR_OD_CVOPCDeltaVelHig_0000 "Specify at which absolute velocity error the higher current should be selected (although v_req = const).";
CM_ SG_ 1474 SensorR_OD_CVOPCSmoothingDe_0000 "Specify at which velocity deviation stronger low pass filtering should end. FIXME Do not use a hard boundary.";
CM_ SG_ 1474 SensorR_OD_CVOPCTcI "Lowpass filter constant of current (for CVOPC and FFCVOPC).";
CM_ SG_ 1474 SensorR_OD_CVOPCTcf "Lowpass filter constant of frequency.";
CM_ SG_ 1474 SensorR_OD_CVOPCImax "Maximum current for current varied OPC.";
CM_ SG_ 1474 SensorR_OD_VelocityController "Select which velocity controller to choose (CC ConstantCurrent, CVFF CurrentVariedFeedForward, CVFB VariedCurrentFeedBack, CAS Cascaded)";
CM_ SG_ 1474 SensorR_OD_TC_f "Time constant for the required frequency.";
CM_ SG_ 1474 SensorR_OD_TC_I "Time constant for the required current.";
CM_ SG_ 1474 SensorR_OD_EstimatedRunLength "Estimated run length based on the velocity profile.";
CM_ SG_ 1474 SensorR_OD_RunProfile_V4 "Velocity for the fith point in the velocity profile.";
CM_ SG_ 1474 SensorR_OD_RunProfile_T4 "Time for the fith point in the velocity profile.";
CM_ SG_ 1474 SensorR_OD_RunProfile_V3 "Velocity for the forth point in the velocity profile.";
CM_ SG_ 1474 SensorR_OD_RunProfile_T3 "Time for the forth point in the velocity profile.";
CM_ SG_ 1474 SensorR_OD_RunProfile_V2 "Velocity for the third point in the velocity profile.";
CM_ SG_ 1474 SensorR_OD_RunProfile_T2 "Time for the third point in the velocity profile.";
CM_ SG_ 1474 SensorR_OD_RunProfile_V1 "Velocity for the second point in the velocity profile.";
CM_ SG_ 1474 SensorR_OD_RunProfile_T1 "Time for the second point in the velocity profile.";
CM_ SG_ 1474 SensorR_OD_RunProfile_V0 "Velocity for the first point in the velocity profile.";
CM_ SG_ 1474 SensorR_OD_RunProfile_T0 "Time for the first point in the velocity profile.";
CM_ SG_ 1474 SensorR_OD_SetFinish "Manual setting of finished flag.";
CM_ SG_ 1474 SensorR_OD_RunMode "Whether to do dynamic run (0), levitation (1) or manual control (2).";
CM_ SG_ 1474 SensorR_OD_VdcReduceFactor "Factor to tune Vdc.";
CM_ SG_ 1474 SensorR_OD_MaxRequiredVelocity "Maximum required velocity the OPC accepts.";
CM_ SG_ 1474 SensorR_OD_WarningThreshhol_0000 "Time where deviation from the required velocity is considered.";
CM_ SG_ 1474 SensorR_OD_MaxCtrlErrorDuration "Time where deviation from the required velocity is considered. (Done by high level control.) FIXME";
CM_ SG_ 1474 SensorR_OD_MaxCtrlError "Maximum deviation from the required velocity for a specified time. (Done by high level control.) FIXME";
CM_ SG_ 1474 SensorR_OD_FminCtrl "Force saturation in OPC (lower boundary). Scaled by (-1). 922 is maximum.";
CM_ SG_ 1474 SensorR_OD_FmaxCtrl "Force saturation in OPC (upper boundary). 1004 is maximum.";
CM_ SG_ 1474 SensorR_OD_PodMass "Mass of pod.";
CM_ SG_ 1474 SensorR_OD_CurrentReq "Required current for LIM (AC RMS coil current controlled by current controller).";
CM_ SG_ 1474 SensorR_OD_CtrlMode "Whether to use V-control (0) or I-control (1).";
CM_ SG_ 1474 SensorR_OD_OpcKi "Integrator gain for OPC.";
CM_ SG_ 1474 SensorR_OD_OpcKp "Product gain for OPC.";
CM_ SG_ 1474 SensorR_OD_ExecTimeReadSensors "Execution time of the sensor readings in milliseconds.";
CM_ SG_ 1474 SensorR_OD_ExecTimeControl "Execution time of the control in milliseconds.";
CM_ SG_ 1474 SensorR_OD_ExecTimeStateEst "Execution time of the State Estimation in milliseconds.";
CM_ SG_ 1474 SensorR_OD_ExecTimeOverall "Execution time of the whole TrajectoryControl task.";
CM_ SG_ 1474 SensorR_OD_IMU3_Temperature "Internal temperature of IMU3.";
CM_ SG_ 1474 SensorR_OD_IMU2_Temperature "Internal temperature of IMU2.";
CM_ SG_ 1474 SensorR_OD_IMU1_Temperature "Internal temperature of IMU1.";
CM_ SG_ 1474 SensorR_OD_IMU_number "Number of IMUs that are online.";
CM_ SG_ 1474 SensorR_OD_EncoderResetPosition "Reset the position of the encoder to zero.";
CM_ SG_ 1474 SensorR_OD_EncoderWheelDiameter "Diameter of the encoder wheel in mm.";
CM_ SG_ 1474 SensorR_OD_samplingInterval "Sensor sampling interval in ms.";
CM_ SG_ 1474 SensorR_OD_CAN2_DelayedTxMe_0000 "Number of delayed TX messages on CAN2 because no messagebox was free.";
CM_ SG_ 1474 SensorR_OD_CAN2_ErrorStatus "Internal error status (e.g. Error active, Error passive, Bus Off)";
CM_ SG_ 1474 SensorR_OD_CAN2_DiscardedTx_0000 "Number of discarded TX messages on CAN2 because all messageboxes were full";
CM_ SG_ 1474 SensorR_OD_CAN2_Status "Status of CAN2.";
CM_ SG_ 1474 SensorR_OD_CAN2_Baudrate "Baudrate of CAN.";
CM_ SG_ 1474 SensorR_OD_CAN2_autoErrorReset "Automatic reset of errors.";
CM_ SG_ 1474 SensorR_OD_CAN2_lastErrorCode "Last error code.";
CM_ SG_ 1474 SensorR_OD_CAN2_RxErrCnt "Receive error count of CAN1.";
CM_ SG_ 1474 SensorR_OD_CAN2_TxErrCnt "Transmit error count of CAN1.";
CM_ SG_ 1474 SensorR_OD_CAN1_DelayedTxMe_0000 "Number of delayed TX messages on CAN1 because no messagebox was free.";
CM_ SG_ 1474 SensorR_OD_CAN1_ErrorStatus "Internal error status (e.g. Error active, Error passive, Bus Off)";
CM_ SG_ 1474 SensorR_OD_CAN1_DiscardedTx_0000 "Number of discarded TX messages on CAN1 because all messageboxes were full";
CM_ SG_ 1474 SensorR_OD_CAN1_Status "Status of CAN1.";
CM_ SG_ 1474 SensorR_OD_CAN1_Baudrate "Baudrate of CAN.";
CM_ SG_ 1474 SensorR_OD_CAN1_autoErrorReset "Automatic reset of errors.";
CM_ SG_ 1474 SensorR_OD_CAN1_lastErrorCode "Last error code.";
CM_ SG_ 1474 SensorR_OD_CAN1_RxErrCnt "Receive error count of CAN1.";
CM_ SG_ 1474 SensorR_OD_CAN1_TxErrCnt "Transmit error count of CAN1.";
CM_ SG_ 1474 SensorR_OD_BuildTime "Software build time in the format HHMMSS.";
CM_ SG_ 1474 SensorR_OD_BuildDate "Software build date in the format YYYYMMDD.";
CM_ SG_ 1474 SensorR_OD_ChipUID2 "Seccond part of unique ID of microcontroller.";
CM_ SG_ 1474 SensorR_OD_ChipUID1 "First part of unique ID of microcontroller.";
CM_ SG_ 1474 SensorR_OD_SdcOut "Measurement of Shutdown Circuit Output";
CM_ SG_ 1474 SensorR_OD_SdcIn "Measurement of Shutdown Circuit Input";
CM_ SG_ 1474 SensorR_OD_runtime "Runtime of chip in milliseconds.";
CM_ SG_ 1474 SensorR_OD_InputVoltage "Board supply voltage.";
CM_ SG_ 1474 SensorR_OD_BoardTemp "Temperature of board";
CM_ SG_ 1474 SensorR_OD_MemFree "Free memory in bytes.";
CM_ SG_ 1474 SensorR_OD_CpuUsage "Current CPU usage in %.";
CM_ SG_ 1474 SensorR_OD_OdEntrySendInterval "Interval for sending all readable OD entries. Sending is disabled if less than 5 ms.";
CM_ SG_ 1474 SensorR_OD_SendOdOnBootup "Whether to send all OD entries on bootup.";
CM_ SG_ 1474 SensorR_OD_HeartbeatInterval "Heartbeat Interval in milliseconds.";
CM_ SG_ 1474 SensorR_OD_DbcVersion "CANzero DBC version.";
CM_ SG_ 1474 SensorR_OD_StackVersion "CANzero stack version.";
CM_ SG_ 1474 SensorR_OD_ProtocolVersion "CANzero Protocol Version.";
CM_ SG_ 1474 SensorR_OD_NodeStatus "State of the node.";
CM_ SG_ 1474 SensorR_OD_NodeID "CANzero Node-ID.";
CM_ SG_ 1474 SensorR_SDO_ID "Specifies SDO-ID of SensorR";
CM_ BO_ 1538 "DO NOT CHANGE ANYTHING HERE!
SDO Request Download from node SensorR with Node-ID 0x2";
CM_ SG_ 1538 SensorR_SDO_ID "Specifies SDO-ID of SensorR";
CM_ BO_ 1794 "Heartbeat of node SensorR with Node-ID 0x2";
CM_ SG_ 1794 SensorR_NodeState "Heartbeat status of node SensorR";
CM_ BO_ 1858 "Bootloader transmit from node SensorR with Node-ID 0x2";
CM_ BO_ 1922 "Bootloader receive by node SensorR with Node-ID 0x2";
CM_ BO_ 145 "Emergency message of node BrakeF with Node-ID 0x11";
CM_ SG_ 145 BrakeF_E5_retractUnsuccesful_ope "Instruction to retract was received, but the SDC is detected to be open";
CM_ SG_ 145 BrakeF_E4_retractUnsuccesful_not "Instruction to retract was received, but the ECU is not enabled";
CM_ SG_ 145 BrakeF_E3_retractUnsuccesful_err "Instruction to retract was received, but an error flag inhibited retraction";
CM_ SG_ 145 BrakeF_E2_commWatchdogTimeout "Communication Watchdog timeout. It took more than the time set to receive a new message from the state machine";
CM_ SG_ 145 BrakeF_E1_pressureTooLow "Pressure tank has a lower value than the provided LowerControlLimit";
CM_ SG_ 145 BrakeF_E0_pressureTooHigh "Pressure tank has a higher value than the provided UpperControlLimit";
CM_ SG_ 145 BrakeF_W3_externalError "SDC reading indicates it's open, but there's no internal error in the ECU";
CM_ SG_ 145 BrakeF_W2_enableWithAnError "The ECU was enabled with an error flag";
CM_ SG_ 145 BrakeF_W1_highPressureRetracting "Pressure higher than desired was measured in the acting chamber";
CM_ SG_ 145 BrakeF_W0_highPressureActingCham "Pressure higher than desired was measured in the acting chamber";
BA_DEF_ SG_  "GenSigSendType" ENUM  "Cyclic","OnWrite","OnWriteWithRepetition","OnChange","OnChangeWithRepetition","IfActive","IfActiveWithRepetition","NoSigSendType";
BA_DEF_ BO_  "GenMsgSendType" ENUM  "Cyclic","not_used","not_used","not_used","not_used","Cyclic","not_used","IfActive","NoMsgSendType";
BA_DEF_  "BusType" STRING ;
BA_DEF_  "DBName" STRING ;
BA_DEF_ BO_  "GenMsgCycleTime" INT 2 50000;
BA_DEF_ BO_  "GenMsgDelayTime" INT 1 1000;
BA_DEF_ BO_  "GenMsgNrOfRepetitions" INT 1 999999;
BA_DEF_ SG_  "GenSigStartValue" FLOAT 0 100000000000;
BA_DEF_  "CANzero_ProtocolVersion" STRING ;
BA_DEF_  "CANzero_DBCVersion" INT 0 16777215;
BA_DEF_  "CANzero_SDOClientName" STRING ;
BA_DEF_  "CANzero_NMTMasterName" STRING ;
BA_DEF_ BU_  "CANzero_NodeID" HEX 0 63;
BA_DEF_ SG_  "CANzero_SDO_Group" STRING ;
BA_DEF_ SG_  "CANzero_SDO_AccessIfOperational" ENUM  "No","Yes";
BA_DEF_ SG_  "CANzero_SDO_AccessType" ENUM  "Read Write","Read Only","Write Only";
BA_DEF_ SG_  "CANzero_SDO_Default" FLOAT 0 0;
BA_DEF_ SG_  "SystemSignalLongSymbol" STRING ;
BA_DEF_DEF_  "GenSigSendType" "Cyclic";
BA_DEF_DEF_  "GenMsgSendType" "NoMsgSendType";
BA_DEF_DEF_  "BusType" "";
BA_DEF_DEF_  "DBName" "";
BA_DEF_DEF_  "GenMsgCycleTime" 100;
BA_DEF_DEF_  "GenMsgDelayTime" 1;
BA_DEF_DEF_  "GenMsgNrOfRepetitions" 1;
BA_DEF_DEF_  "GenSigStartValue" 0;
BA_DEF_DEF_  "CANzero_ProtocolVersion" "";
BA_DEF_DEF_  "CANzero_DBCVersion" 0;
BA_DEF_DEF_  "CANzero_SDOClientName" "Master";
BA_DEF_DEF_  "CANzero_NMTMasterName" "Master";
BA_DEF_DEF_  "CANzero_NodeID" 0;
BA_DEF_DEF_  "CANzero_SDO_Group" "";
BA_DEF_DEF_  "CANzero_SDO_AccessIfOperational" "No";
BA_DEF_DEF_  "CANzero_SDO_AccessType" "Read Write";
BA_DEF_DEF_  "CANzero_SDO_Default" 0;
BA_DEF_DEF_  "SystemSignalLongSymbol" "";
BA_ "BusType" "CAN";
BA_ "CANzero_ProtocolVersion" "V1.0";
BA_ "CANzero_DBCVersion" 198;
BA_ "CANzero_SDOClientName" "TelemetryNode";
BA_ "DBName" "pod2022";
BA_ "CANzero_NodeID" BU_ TelemetryNode 34;
BA_ "CANzero_NodeID" BU_ SensorF 1;
BA_ "CANzero_NodeID" BU_ SensorR 2;
BA_ "CANzero_NodeID" BU_ BrakeF 17;
BA_ "CANzero_NodeID" BU_ BrakeR 18;
BA_ "CANzero_NodeID" BU_ PDU 26;
BA_ "CANzero_NodeID" BU_ HVCU 10;
BA_ "CANzero_NodeID" BU_ HVTU 25;
BA_ "CANzero_NodeID" BU_ MDB1 33;
BA_ "CANzero_NodeID" BU_ MDB2 35;
BA_ "CANzero_NodeID" BU_ MDB3 39;
BA_ "CANzero_NodeID" BU_ MDB4 40;
BA_ "CANzero_NodeID" BU_ MDB5 41;
BA_ "CANzero_NodeID" BU_ MDB6 49;
BA_ "CANzero_NodeID" BU_ Track 50;
BA_ "CANzero_NodeID" BU_ CLU 20;
BA_ "GenSigStartValue" SG_ 1041 BrakeF_TX_Pressure_Reservoir 400;
BA_ "GenSigStartValue" SG_ 1089 SensorF_TX_BatteryTemp 600;
BA_ "GenSigStartValue" SG_ 1153 SensorF_Cooling_Temp 600;
BA_ "GenSigStartValue" SG_ 1153 SensorF_LIMT_Stator_4 266.666666666667;
BA_ "GenSigStartValue" SG_ 1153 SensorF_LIMT_Stator_3 266.666666666667;
BA_ "GenSigStartValue" SG_ 1153 SensorF_LIMT_Stator_2 266.666666666667;
BA_ "GenSigStartValue" SG_ 1153 SensorF_LIMT_Stator_1 266.666666666667;
BA_ "CANzero_SDO_AccessType" SG_ 1409 SensorF_OD_SetReset 2;
BA_ "CANzero_SDO_AccessIfOperational" SG_ 1409 SensorF_OD_SetReset 1;
BA_ "CANzero_SDO_AccessType" SG_ 1409 SensorF_OD_Velocity 1;
BA_ "CANzero_SDO_AccessIfOperational" SG_ 1409 SensorF_OD_Velocity 1;
BA_ "GenSigStartValue" SG_ 1409 SensorF_OD_Velocity 10000.0;
BA_ "CANzero_SDO_AccessType" SG_ 1409 SensorF_OD_Position 1;
BA_ "CANzero_SDO_AccessIfOperational" SG_ 1409 SensorF_OD_Position 1;
BA_ "GenSigStartValue" SG_ 1409 SensorF_OD_Position 10000.0;
BA_ "CANzero_SDO_AccessType" SG_ 1409 SensorF_OD_StripeCount 1;
BA_ "CANzero_SDO_AccessIfOperational" SG_ 1409 SensorF_OD_StripeCount 1;
BA_ "CANzero_SDO_AccessIfOperational" SG_ 1409 SensorF_OD_MdbState 1;
BA_ "CANzero_SDO_AccessType" SG_ 1409 SensorF_OD_Magnet_6_Temperature 1;
BA_ "CANzero_SDO_AccessIfOperational" SG_ 1409 SensorF_OD_Magnet_6_Temperature 1;
BA_ "GenSigStartValue" SG_ 1409 SensorF_OD_Magnet_6_Temperature 11000.0;
BA_ "CANzero_SDO_Default" SG_ 1409 SensorF_OD_Magnet_6_Temperature 10;
BA_ "CANzero_SDO_AccessType" SG_ 1409 SensorF_OD_Magnet_5_Temperature 1;
BA_ "CANzero_SDO_AccessIfOperational" SG_ 1409 SensorF_OD_Magnet_5_Temperature 1;
BA_ "GenSigStartValue" SG_ 1409 SensorF_OD_Magnet_5_Temperature 11000.0;
BA_ "CANzero_SDO_Default" SG_ 1409 SensorF_OD_Magnet_5_Temperature 10;
BA_ "CANzero_SDO_AccessType" SG_ 1409 SensorF_OD_Magnet_4_Temperature 1;
BA_ "CANzero_SDO_AccessIfOperational" SG_ 1409 SensorF_OD_Magnet_4_Temperature 1;
BA_ "GenSigStartValue" SG_ 1409 SensorF_OD_Magnet_4_Temperature 11000.0;
BA_ "CANzero_SDO_Default" SG_ 1409 SensorF_OD_Magnet_4_Temperature 10;
BA_ "CANzero_SDO_AccessType" SG_ 1409 SensorF_OD_Magnet_3_Temperature 1;
BA_ "CANzero_SDO_AccessIfOperational" SG_ 1409 SensorF_OD_Magnet_3_Temperature 1;
BA_ "GenSigStartValue" SG_ 1409 SensorF_OD_Magnet_3_Temperature 11000.0;
BA_ "CANzero_SDO_Default" SG_ 1409 SensorF_OD_Magnet_3_Temperature 10;
BA_ "CANzero_SDO_AccessType" SG_ 1409 SensorF_OD_Magnet_2_Temperature 1;
BA_ "CANzero_SDO_AccessIfOperational" SG_ 1409 SensorF_OD_Magnet_2_Temperature 1;
BA_ "GenSigStartValue" SG_ 1409 SensorF_OD_Magnet_2_Temperature 11000.0;
BA_ "CANzero_SDO_Default" SG_ 1409 SensorF_OD_Magnet_2_Temperature 10;
BA_ "CANzero_SDO_AccessType" SG_ 1409 SensorF_OD_Magnet_1_Temperature 1;
BA_ "CANzero_SDO_AccessIfOperational" SG_ 1409 SensorF_OD_Magnet_1_Temperature 1;
BA_ "GenSigStartValue" SG_ 1409 SensorF_OD_Magnet_1_Temperature 11000.0;
BA_ "CANzero_SDO_Default" SG_ 1409 SensorF_OD_Magnet_1_Temperature 10;
BA_ "CANzero_SDO_AccessType" SG_ 1409 SensorF_OD_ReservoirTemperature 1;
BA_ "CANzero_SDO_AccessIfOperational" SG_ 1409 SensorF_OD_ReservoirTemperature 1;
BA_ "GenSigStartValue" SG_ 1409 SensorF_OD_ReservoirTemperature 18000.0;
BA_ "CANzero_SDO_Default" SG_ 1409 SensorF_OD_ReservoirTemperature 80;
BA_ "CANzero_SDO_AccessType" SG_ 1409 SensorF_OD_CoolingPressure 1;
BA_ "CANzero_SDO_AccessIfOperational" SG_ 1409 SensorF_OD_CoolingPressure 1;
BA_ "GenSigStartValue" SG_ 1409 SensorF_OD_CoolingPressure 9810.0;
BA_ "CANzero_SDO_Default" SG_ 1409 SensorF_OD_CoolingPressure -1.9;
BA_ "CANzero_SDO_AccessType" SG_ 1409 SensorF_OD_IMU_GyroZ 1;
BA_ "CANzero_SDO_AccessIfOperational" SG_ 1409 SensorF_OD_IMU_GyroZ 1;
BA_ "GenSigStartValue" SG_ 1409 SensorF_OD_IMU_GyroZ 10000.0;
BA_ "CANzero_SDO_AccessType" SG_ 1409 SensorF_OD_IMU_GyroY 1;
BA_ "CANzero_SDO_AccessIfOperational" SG_ 1409 SensorF_OD_IMU_GyroY 1;
BA_ "GenSigStartValue" SG_ 1409 SensorF_OD_IMU_GyroY 10000.0;
BA_ "CANzero_SDO_AccessType" SG_ 1409 SensorF_OD_IMU_GyroX 1;
BA_ "CANzero_SDO_AccessIfOperational" SG_ 1409 SensorF_OD_IMU_GyroX 1;
BA_ "GenSigStartValue" SG_ 1409 SensorF_OD_IMU_GyroX 10000.0;
BA_ "CANzero_SDO_AccessType" SG_ 1409 SensorF_OD_IMU_AccelZ 1;
BA_ "CANzero_SDO_AccessIfOperational" SG_ 1409 SensorF_OD_IMU_AccelZ 1;
BA_ "GenSigStartValue" SG_ 1409 SensorF_OD_IMU_AccelZ 10000.0;
BA_ "CANzero_SDO_AccessType" SG_ 1409 SensorF_OD_IMU_AccelY 1;
BA_ "CANzero_SDO_AccessIfOperational" SG_ 1409 SensorF_OD_IMU_AccelY 1;
BA_ "GenSigStartValue" SG_ 1409 SensorF_OD_IMU_AccelY 10000.0;
BA_ "CANzero_SDO_AccessType" SG_ 1409 SensorF_OD_IMU_AccelX 1;
BA_ "CANzero_SDO_AccessIfOperational" SG_ 1409 SensorF_OD_IMU_AccelX 1;
BA_ "GenSigStartValue" SG_ 1409 SensorF_OD_IMU_AccelX 10000.0;
BA_ "CANzero_SDO_AccessType" SG_ 1409 SensorF_OD_IMU3_Temperature 1;
BA_ "CANzero_SDO_AccessIfOperational" SG_ 1409 SensorF_OD_IMU3_Temperature 1;
BA_ "GenSigStartValue" SG_ 1409 SensorF_OD_IMU3_Temperature 10000.0;
BA_ "CANzero_SDO_AccessType" SG_ 1409 SensorF_OD_IMU2_Temperature 1;
BA_ "CANzero_SDO_AccessIfOperational" SG_ 1409 SensorF_OD_IMU2_Temperature 1;
BA_ "GenSigStartValue" SG_ 1409 SensorF_OD_IMU2_Temperature 10000.0;
BA_ "CANzero_SDO_AccessType" SG_ 1409 SensorF_OD_IMU1_Temperature 1;
BA_ "CANzero_SDO_AccessIfOperational" SG_ 1409 SensorF_OD_IMU1_Temperature 1;
BA_ "GenSigStartValue" SG_ 1409 SensorF_OD_IMU1_Temperature 10000.0;
BA_ "CANzero_SDO_AccessType" SG_ 1409 SensorF_OD_IMU_number 1;
BA_ "CANzero_SDO_AccessIfOperational" SG_ 1409 SensorF_OD_IMU_number 1;
BA_ "CANzero_SDO_AccessType" SG_ 1409 SensorF_OD_EncoderResetPosition 2;
BA_ "CANzero_SDO_AccessIfOperational" SG_ 1409 SensorF_OD_EncoderResetPosition 1;
BA_ "CANzero_SDO_AccessIfOperational" SG_ 1409 SensorF_OD_EncoderWheelDiameter 1;
BA_ "GenSigStartValue" SG_ 1409 SensorF_OD_EncoderWheelDiameter 15000.0;
BA_ "CANzero_SDO_Default" SG_ 1409 SensorF_OD_EncoderWheelDiameter 75;
BA_ "CANzero_SDO_AccessIfOperational" SG_ 1409 SensorF_OD_HVBatteryMode 1;
BA_ "CANzero_SDO_AccessIfOperational" SG_ 1409 SensorF_OD_StateMachineActivate 1;
BA_ "CANzero_SDO_AccessIfOperational" SG_ 1409 SensorF_OD_StateMachineInterval 1;
BA_ "GenSigStartValue" SG_ 1409 SensorF_OD_StateMachineInterval 10.0;
BA_ "CANzero_SDO_Default" SG_ 1409 SensorF_OD_StateMachineInterval 10;
BA_ "CANzero_SDO_AccessIfOperational" SG_ 1409 SensorF_OD_TelemetryCommands 1;
BA_ "CANzero_SDO_AccessIfOperational" SG_ 1409 SensorF_OD_samplingInterval 1;
BA_ "GenSigStartValue" SG_ 1409 SensorF_OD_samplingInterval 1000.0;
BA_ "CANzero_SDO_Default" SG_ 1409 SensorF_OD_samplingInterval 10;
BA_ "CANzero_SDO_Group" SG_ 1409 SensorF_OD_CAN2_DelayedTxMessage "CAN";
BA_ "CANzero_SDO_AccessType" SG_ 1409 SensorF_OD_CAN2_DelayedTxMessage 1;
BA_ "CANzero_SDO_AccessIfOperational" SG_ 1409 SensorF_OD_CAN2_DelayedTxMessage 1;
BA_ "SystemSignalLongSymbol" SG_ 1409 SensorF_OD_CAN2_DelayedTxMessage "SensorF_OD_CAN2_DelayedTxMessages";
BA_ "CANzero_SDO_Group" SG_ 1409 SensorF_OD_CAN2_ErrorStatus "CAN";
BA_ "CANzero_SDO_AccessType" SG_ 1409 SensorF_OD_CAN2_ErrorStatus 1;
BA_ "CANzero_SDO_AccessIfOperational" SG_ 1409 SensorF_OD_CAN2_ErrorStatus 1;
BA_ "CANzero_SDO_Group" SG_ 1409 SensorF_OD_CAN2_DiscardedTxMessa "CAN";
BA_ "CANzero_SDO_AccessType" SG_ 1409 SensorF_OD_CAN2_DiscardedTxMessa 1;
BA_ "CANzero_SDO_AccessIfOperational" SG_ 1409 SensorF_OD_CAN2_DiscardedTxMessa 1;
BA_ "SystemSignalLongSymbol" SG_ 1409 SensorF_OD_CAN2_DiscardedTxMessa "SensorF_OD_CAN2_DiscardedTxMessages";
BA_ "CANzero_SDO_Group" SG_ 1409 SensorF_OD_CAN2_Status "CAN";
BA_ "CANzero_SDO_AccessType" SG_ 1409 SensorF_OD_CAN2_Status 1;
BA_ "CANzero_SDO_AccessIfOperational" SG_ 1409 SensorF_OD_CAN2_Status 1;
BA_ "CANzero_SDO_Group" SG_ 1409 SensorF_OD_CAN2_Baudrate "CAN";
BA_ "CANzero_SDO_AccessIfOperational" SG_ 1409 SensorF_OD_CAN2_Baudrate 1;
BA_ "GenSigStartValue" SG_ 1409 SensorF_OD_CAN2_Baudrate 1000.0;
BA_ "CANzero_SDO_Default" SG_ 1409 SensorF_OD_CAN2_Baudrate 1000;
BA_ "CANzero_SDO_Group" SG_ 1409 SensorF_OD_CAN2_autoErrorReset "CAN";
BA_ "CANzero_SDO_AccessIfOperational" SG_ 1409 SensorF_OD_CAN2_autoErrorReset 1;
BA_ "GenSigStartValue" SG_ 1409 SensorF_OD_CAN2_autoErrorReset 1.0;
BA_ "CANzero_SDO_Default" SG_ 1409 SensorF_OD_CAN2_autoErrorReset 1;
BA_ "CANzero_SDO_Group" SG_ 1409 SensorF_OD_CAN2_lastErrorCode "CAN";
BA_ "CANzero_SDO_AccessType" SG_ 1409 SensorF_OD_CAN2_lastErrorCode 1;
BA_ "CANzero_SDO_AccessIfOperational" SG_ 1409 SensorF_OD_CAN2_lastErrorCode 1;
BA_ "CANzero_SDO_Group" SG_ 1409 SensorF_OD_CAN2_RxErrCnt "CAN";
BA_ "CANzero_SDO_AccessType" SG_ 1409 SensorF_OD_CAN2_RxErrCnt 1;
BA_ "CANzero_SDO_AccessIfOperational" SG_ 1409 SensorF_OD_CAN2_RxErrCnt 1;
BA_ "CANzero_SDO_Group" SG_ 1409 SensorF_OD_CAN2_TxErrCnt "CAN";
BA_ "CANzero_SDO_AccessType" SG_ 1409 SensorF_OD_CAN2_TxErrCnt 1;
BA_ "CANzero_SDO_AccessIfOperational" SG_ 1409 SensorF_OD_CAN2_TxErrCnt 1;
BA_ "CANzero_SDO_Group" SG_ 1409 SensorF_OD_CAN1_DelayedTxMessage "CAN";
BA_ "CANzero_SDO_AccessType" SG_ 1409 SensorF_OD_CAN1_DelayedTxMessage 1;
BA_ "CANzero_SDO_AccessIfOperational" SG_ 1409 SensorF_OD_CAN1_DelayedTxMessage 1;
BA_ "SystemSignalLongSymbol" SG_ 1409 SensorF_OD_CAN1_DelayedTxMessage "SensorF_OD_CAN1_DelayedTxMessages";
BA_ "CANzero_SDO_Group" SG_ 1409 SensorF_OD_CAN1_ErrorStatus "CAN";
BA_ "CANzero_SDO_AccessType" SG_ 1409 SensorF_OD_CAN1_ErrorStatus 1;
BA_ "CANzero_SDO_AccessIfOperational" SG_ 1409 SensorF_OD_CAN1_ErrorStatus 1;
BA_ "CANzero_SDO_Group" SG_ 1409 SensorF_OD_CAN1_DiscardedTxMessa "CAN";
BA_ "CANzero_SDO_AccessType" SG_ 1409 SensorF_OD_CAN1_DiscardedTxMessa 1;
BA_ "CANzero_SDO_AccessIfOperational" SG_ 1409 SensorF_OD_CAN1_DiscardedTxMessa 1;
BA_ "SystemSignalLongSymbol" SG_ 1409 SensorF_OD_CAN1_DiscardedTxMessa "SensorF_OD_CAN1_DiscardedTxMessages";
BA_ "CANzero_SDO_Group" SG_ 1409 SensorF_OD_CAN1_Status "CAN";
BA_ "CANzero_SDO_AccessType" SG_ 1409 SensorF_OD_CAN1_Status 1;
BA_ "CANzero_SDO_AccessIfOperational" SG_ 1409 SensorF_OD_CAN1_Status 1;
BA_ "CANzero_SDO_Group" SG_ 1409 SensorF_OD_CAN1_Baudrate "CAN";
BA_ "CANzero_SDO_AccessIfOperational" SG_ 1409 SensorF_OD_CAN1_Baudrate 1;
BA_ "GenSigStartValue" SG_ 1409 SensorF_OD_CAN1_Baudrate 1000.0;
BA_ "CANzero_SDO_Default" SG_ 1409 SensorF_OD_CAN1_Baudrate 1000;
BA_ "CANzero_SDO_Group" SG_ 1409 SensorF_OD_CAN1_autoErrorReset "CAN";
BA_ "CANzero_SDO_AccessIfOperational" SG_ 1409 SensorF_OD_CAN1_autoErrorReset 1;
BA_ "GenSigStartValue" SG_ 1409 SensorF_OD_CAN1_autoErrorReset 1.0;
BA_ "CANzero_SDO_Default" SG_ 1409 SensorF_OD_CAN1_autoErrorReset 1;
BA_ "CANzero_SDO_Group" SG_ 1409 SensorF_OD_CAN1_lastErrorCode "CAN";
BA_ "CANzero_SDO_AccessType" SG_ 1409 SensorF_OD_CAN1_lastErrorCode 1;
BA_ "CANzero_SDO_AccessIfOperational" SG_ 1409 SensorF_OD_CAN1_lastErrorCode 1;
BA_ "CANzero_SDO_Group" SG_ 1409 SensorF_OD_CAN1_RxErrCnt "CAN";
BA_ "CANzero_SDO_AccessType" SG_ 1409 SensorF_OD_CAN1_RxErrCnt 1;
BA_ "CANzero_SDO_AccessIfOperational" SG_ 1409 SensorF_OD_CAN1_RxErrCnt 1;
BA_ "CANzero_SDO_Group" SG_ 1409 SensorF_OD_CAN1_TxErrCnt "CAN";
BA_ "CANzero_SDO_AccessType" SG_ 1409 SensorF_OD_CAN1_TxErrCnt 1;
BA_ "CANzero_SDO_AccessIfOperational" SG_ 1409 SensorF_OD_CAN1_TxErrCnt 1;
BA_ "CANzero_SDO_AccessType" SG_ 1409 SensorF_OD_BuildTime 1;
BA_ "CANzero_SDO_AccessIfOperational" SG_ 1409 SensorF_OD_BuildTime 1;
BA_ "CANzero_SDO_AccessType" SG_ 1409 SensorF_OD_BuildDate 1;
BA_ "CANzero_SDO_AccessIfOperational" SG_ 1409 SensorF_OD_BuildDate 1;
BA_ "CANzero_SDO_AccessType" SG_ 1409 SensorF_OD_ChipUID2 1;
BA_ "CANzero_SDO_AccessIfOperational" SG_ 1409 SensorF_OD_ChipUID2 1;
BA_ "CANzero_SDO_AccessType" SG_ 1409 SensorF_OD_ChipUID1 1;
BA_ "CANzero_SDO_AccessIfOperational" SG_ 1409 SensorF_OD_ChipUID1 1;
BA_ "CANzero_SDO_AccessType" SG_ 1409 SensorF_OD_SdcOut 1;
BA_ "CANzero_SDO_AccessIfOperational" SG_ 1409 SensorF_OD_SdcOut 1;
BA_ "CANzero_SDO_AccessType" SG_ 1409 SensorF_OD_SdcIn 1;
BA_ "CANzero_SDO_AccessIfOperational" SG_ 1409 SensorF_OD_SdcIn 1;
BA_ "CANzero_SDO_AccessType" SG_ 1409 SensorF_OD_runtime 1;
BA_ "CANzero_SDO_AccessIfOperational" SG_ 1409 SensorF_OD_runtime 1;
BA_ "CANzero_SDO_AccessType" SG_ 1409 SensorF_OD_InputVoltage 1;
BA_ "CANzero_SDO_AccessIfOperational" SG_ 1409 SensorF_OD_InputVoltage 1;
BA_ "CANzero_SDO_AccessType" SG_ 1409 SensorF_OD_BoardTemp 1;
BA_ "CANzero_SDO_AccessIfOperational" SG_ 1409 SensorF_OD_BoardTemp 1;
BA_ "GenSigStartValue" SG_ 1409 SensorF_OD_BoardTemp 3000.0;
BA_ "CANzero_SDO_AccessType" SG_ 1409 SensorF_OD_MemFree 1;
BA_ "CANzero_SDO_AccessIfOperational" SG_ 1409 SensorF_OD_MemFree 1;
BA_ "CANzero_SDO_AccessType" SG_ 1409 SensorF_OD_CpuUsage 1;
BA_ "CANzero_SDO_AccessIfOperational" SG_ 1409 SensorF_OD_CpuUsage 1;
BA_ "CANzero_SDO_AccessIfOperational" SG_ 1409 SensorF_OD_OdEntrySendInterval 1;
BA_ "GenSigStartValue" SG_ 1409 SensorF_OD_OdEntrySendInterval 50.0;
BA_ "CANzero_SDO_Default" SG_ 1409 SensorF_OD_OdEntrySendInterval 50;
BA_ "CANzero_SDO_AccessIfOperational" SG_ 1409 SensorF_OD_SendOdOnBootup 1;
BA_ "CANzero_SDO_AccessIfOperational" SG_ 1409 SensorF_OD_HeartbeatInterval 1;
BA_ "GenSigStartValue" SG_ 1409 SensorF_OD_HeartbeatInterval 250.0;
BA_ "CANzero_SDO_Default" SG_ 1409 SensorF_OD_HeartbeatInterval 250;
BA_ "CANzero_SDO_AccessType" SG_ 1409 SensorF_OD_DbcVersion 1;
BA_ "CANzero_SDO_AccessIfOperational" SG_ 1409 SensorF_OD_DbcVersion 1;
BA_ "CANzero_SDO_AccessType" SG_ 1409 SensorF_OD_StackVersion 1;
BA_ "CANzero_SDO_AccessIfOperational" SG_ 1409 SensorF_OD_StackVersion 1;
BA_ "CANzero_SDO_AccessType" SG_ 1409 SensorF_OD_ProtocolVersion 1;
BA_ "CANzero_SDO_AccessIfOperational" SG_ 1409 SensorF_OD_ProtocolVersion 1;
BA_ "GenSigStartValue" SG_ 1409 SensorF_OD_ProtocolVersion 1.0;
BA_ "CANzero_SDO_Default" SG_ 1409 SensorF_OD_ProtocolVersion 1;
BA_ "CANzero_SDO_AccessType" SG_ 1409 SensorF_OD_NodeStatus 1;
BA_ "CANzero_SDO_AccessIfOperational" SG_ 1409 SensorF_OD_NodeStatus 1;
BA_ "CANzero_SDO_AccessType" SG_ 1409 SensorF_OD_NodeID 1;
BA_ "CANzero_SDO_AccessIfOperational" SG_ 1409 SensorF_OD_NodeID 1;
BA_ "CANzero_SDO_AccessType" SG_ 1473 SensorF_OD_SetReset 2;
BA_ "CANzero_SDO_AccessIfOperational" SG_ 1473 SensorF_OD_SetReset 1;
BA_ "CANzero_SDO_AccessType" SG_ 1473 SensorF_OD_Velocity 1;
BA_ "CANzero_SDO_AccessIfOperational" SG_ 1473 SensorF_OD_Velocity 1;
BA_ "GenSigStartValue" SG_ 1473 SensorF_OD_Velocity 10000.0;
BA_ "CANzero_SDO_AccessType" SG_ 1473 SensorF_OD_Position 1;
BA_ "CANzero_SDO_AccessIfOperational" SG_ 1473 SensorF_OD_Position 1;
BA_ "GenSigStartValue" SG_ 1473 SensorF_OD_Position 10000.0;
BA_ "CANzero_SDO_AccessType" SG_ 1473 SensorF_OD_StripeCount 1;
BA_ "CANzero_SDO_AccessIfOperational" SG_ 1473 SensorF_OD_StripeCount 1;
BA_ "CANzero_SDO_AccessIfOperational" SG_ 1473 SensorF_OD_MdbState 1;
BA_ "CANzero_SDO_AccessType" SG_ 1473 SensorF_OD_Magnet_6_Temperature 1;
BA_ "CANzero_SDO_AccessIfOperational" SG_ 1473 SensorF_OD_Magnet_6_Temperature 1;
BA_ "GenSigStartValue" SG_ 1473 SensorF_OD_Magnet_6_Temperature 11000.0;
BA_ "CANzero_SDO_Default" SG_ 1473 SensorF_OD_Magnet_6_Temperature 10;
BA_ "CANzero_SDO_AccessType" SG_ 1473 SensorF_OD_Magnet_5_Temperature 1;
BA_ "CANzero_SDO_AccessIfOperational" SG_ 1473 SensorF_OD_Magnet_5_Temperature 1;
BA_ "GenSigStartValue" SG_ 1473 SensorF_OD_Magnet_5_Temperature 11000.0;
BA_ "CANzero_SDO_Default" SG_ 1473 SensorF_OD_Magnet_5_Temperature 10;
BA_ "CANzero_SDO_AccessType" SG_ 1473 SensorF_OD_Magnet_4_Temperature 1;
BA_ "CANzero_SDO_AccessIfOperational" SG_ 1473 SensorF_OD_Magnet_4_Temperature 1;
BA_ "GenSigStartValue" SG_ 1473 SensorF_OD_Magnet_4_Temperature 11000.0;
BA_ "CANzero_SDO_Default" SG_ 1473 SensorF_OD_Magnet_4_Temperature 10;
BA_ "CANzero_SDO_AccessType" SG_ 1473 SensorF_OD_Magnet_3_Temperature 1;
BA_ "CANzero_SDO_AccessIfOperational" SG_ 1473 SensorF_OD_Magnet_3_Temperature 1;
BA_ "GenSigStartValue" SG_ 1473 SensorF_OD_Magnet_3_Temperature 11000.0;
BA_ "CANzero_SDO_Default" SG_ 1473 SensorF_OD_Magnet_3_Temperature 10;
BA_ "CANzero_SDO_AccessType" SG_ 1473 SensorF_OD_Magnet_2_Temperature 1;
BA_ "CANzero_SDO_AccessIfOperational" SG_ 1473 SensorF_OD_Magnet_2_Temperature 1;
BA_ "GenSigStartValue" SG_ 1473 SensorF_OD_Magnet_2_Temperature 11000.0;
BA_ "CANzero_SDO_Default" SG_ 1473 SensorF_OD_Magnet_2_Temperature 10;
BA_ "CANzero_SDO_AccessType" SG_ 1473 SensorF_OD_Magnet_1_Temperature 1;
BA_ "CANzero_SDO_AccessIfOperational" SG_ 1473 SensorF_OD_Magnet_1_Temperature 1;
BA_ "GenSigStartValue" SG_ 1473 SensorF_OD_Magnet_1_Temperature 11000.0;
BA_ "CANzero_SDO_Default" SG_ 1473 SensorF_OD_Magnet_1_Temperature 10;
BA_ "CANzero_SDO_AccessType" SG_ 1473 SensorF_OD_ReservoirTemperature 1;
BA_ "CANzero_SDO_AccessIfOperational" SG_ 1473 SensorF_OD_ReservoirTemperature 1;
BA_ "GenSigStartValue" SG_ 1473 SensorF_OD_ReservoirTemperature 18000.0;
BA_ "CANzero_SDO_Default" SG_ 1473 SensorF_OD_ReservoirTemperature 80;
BA_ "CANzero_SDO_AccessType" SG_ 1473 SensorF_OD_CoolingPressure 1;
BA_ "CANzero_SDO_AccessIfOperational" SG_ 1473 SensorF_OD_CoolingPressure 1;
BA_ "GenSigStartValue" SG_ 1473 SensorF_OD_CoolingPressure 9810.0;
BA_ "CANzero_SDO_Default" SG_ 1473 SensorF_OD_CoolingPressure -1.9;
BA_ "CANzero_SDO_AccessType" SG_ 1473 SensorF_OD_IMU_GyroZ 1;
BA_ "CANzero_SDO_AccessIfOperational" SG_ 1473 SensorF_OD_IMU_GyroZ 1;
BA_ "GenSigStartValue" SG_ 1473 SensorF_OD_IMU_GyroZ 10000.0;
BA_ "CANzero_SDO_AccessType" SG_ 1473 SensorF_OD_IMU_GyroY 1;
BA_ "CANzero_SDO_AccessIfOperational" SG_ 1473 SensorF_OD_IMU_GyroY 1;
BA_ "GenSigStartValue" SG_ 1473 SensorF_OD_IMU_GyroY 10000.0;
BA_ "CANzero_SDO_AccessType" SG_ 1473 SensorF_OD_IMU_GyroX 1;
BA_ "CANzero_SDO_AccessIfOperational" SG_ 1473 SensorF_OD_IMU_GyroX 1;
BA_ "GenSigStartValue" SG_ 1473 SensorF_OD_IMU_GyroX 10000.0;
BA_ "CANzero_SDO_AccessType" SG_ 1473 SensorF_OD_IMU_AccelZ 1;
BA_ "CANzero_SDO_AccessIfOperational" SG_ 1473 SensorF_OD_IMU_AccelZ 1;
BA_ "GenSigStartValue" SG_ 1473 SensorF_OD_IMU_AccelZ 10000.0;
BA_ "CANzero_SDO_AccessType" SG_ 1473 SensorF_OD_IMU_AccelY 1;
BA_ "CANzero_SDO_AccessIfOperational" SG_ 1473 SensorF_OD_IMU_AccelY 1;
BA_ "GenSigStartValue" SG_ 1473 SensorF_OD_IMU_AccelY 10000.0;
BA_ "CANzero_SDO_AccessType" SG_ 1473 SensorF_OD_IMU_AccelX 1;
BA_ "CANzero_SDO_AccessIfOperational" SG_ 1473 SensorF_OD_IMU_AccelX 1;
BA_ "GenSigStartValue" SG_ 1473 SensorF_OD_IMU_AccelX 10000.0;
BA_ "CANzero_SDO_AccessType" SG_ 1473 SensorF_OD_IMU3_Temperature 1;
BA_ "CANzero_SDO_AccessIfOperational" SG_ 1473 SensorF_OD_IMU3_Temperature 1;
BA_ "GenSigStartValue" SG_ 1473 SensorF_OD_IMU3_Temperature 10000.0;
BA_ "CANzero_SDO_AccessType" SG_ 1473 SensorF_OD_IMU2_Temperature 1;
BA_ "CANzero_SDO_AccessIfOperational" SG_ 1473 SensorF_OD_IMU2_Temperature 1;
BA_ "GenSigStartValue" SG_ 1473 SensorF_OD_IMU2_Temperature 10000.0;
BA_ "CANzero_SDO_AccessType" SG_ 1473 SensorF_OD_IMU1_Temperature 1;
BA_ "CANzero_SDO_AccessIfOperational" SG_ 1473 SensorF_OD_IMU1_Temperature 1;
BA_ "GenSigStartValue" SG_ 1473 SensorF_OD_IMU1_Temperature 10000.0;
BA_ "CANzero_SDO_AccessType" SG_ 1473 SensorF_OD_IMU_number 1;
BA_ "CANzero_SDO_AccessIfOperational" SG_ 1473 SensorF_OD_IMU_number 1;
BA_ "CANzero_SDO_AccessType" SG_ 1473 SensorF_OD_EncoderResetPosition 2;
BA_ "CANzero_SDO_AccessIfOperational" SG_ 1473 SensorF_OD_EncoderResetPosition 1;
BA_ "CANzero_SDO_AccessIfOperational" SG_ 1473 SensorF_OD_EncoderWheelDiameter 1;
BA_ "GenSigStartValue" SG_ 1473 SensorF_OD_EncoderWheelDiameter 15000.0;
BA_ "CANzero_SDO_Default" SG_ 1473 SensorF_OD_EncoderWheelDiameter 75;
BA_ "CANzero_SDO_AccessIfOperational" SG_ 1473 SensorF_OD_HVBatteryMode 1;
BA_ "CANzero_SDO_AccessIfOperational" SG_ 1473 SensorF_OD_StateMachineActivate 1;
BA_ "CANzero_SDO_AccessIfOperational" SG_ 1473 SensorF_OD_StateMachineInterval 1;
BA_ "GenSigStartValue" SG_ 1473 SensorF_OD_StateMachineInterval 10.0;
BA_ "CANzero_SDO_Default" SG_ 1473 SensorF_OD_StateMachineInterval 10;
BA_ "CANzero_SDO_AccessIfOperational" SG_ 1473 SensorF_OD_TelemetryCommands 1;
BA_ "CANzero_SDO_AccessIfOperational" SG_ 1473 SensorF_OD_samplingInterval 1;
BA_ "GenSigStartValue" SG_ 1473 SensorF_OD_samplingInterval 1000.0;
BA_ "CANzero_SDO_Default" SG_ 1473 SensorF_OD_samplingInterval 10;
BA_ "CANzero_SDO_Group" SG_ 1473 SensorF_OD_CAN2_DelayedTxMe_0000 "CAN";
BA_ "CANzero_SDO_AccessType" SG_ 1473 SensorF_OD_CAN2_DelayedTxMe_0000 1;
BA_ "CANzero_SDO_AccessIfOperational" SG_ 1473 SensorF_OD_CAN2_DelayedTxMe_0000 1;
BA_ "SystemSignalLongSymbol" SG_ 1473 SensorF_OD_CAN2_DelayedTxMe_0000 "SensorF_OD_CAN2_DelayedTxMessages";
BA_ "CANzero_SDO_Group" SG_ 1473 SensorF_OD_CAN2_ErrorStatus "CAN";
BA_ "CANzero_SDO_AccessType" SG_ 1473 SensorF_OD_CAN2_ErrorStatus 1;
BA_ "CANzero_SDO_AccessIfOperational" SG_ 1473 SensorF_OD_CAN2_ErrorStatus 1;
BA_ "CANzero_SDO_Group" SG_ 1473 SensorF_OD_CAN2_DiscardedTx_0000 "CAN";
BA_ "CANzero_SDO_AccessType" SG_ 1473 SensorF_OD_CAN2_DiscardedTx_0000 1;
BA_ "CANzero_SDO_AccessIfOperational" SG_ 1473 SensorF_OD_CAN2_DiscardedTx_0000 1;
BA_ "SystemSignalLongSymbol" SG_ 1473 SensorF_OD_CAN2_DiscardedTx_0000 "SensorF_OD_CAN2_DiscardedTxMessages";
BA_ "CANzero_SDO_Group" SG_ 1473 SensorF_OD_CAN2_Status "CAN";
BA_ "CANzero_SDO_AccessType" SG_ 1473 SensorF_OD_CAN2_Status 1;
BA_ "CANzero_SDO_AccessIfOperational" SG_ 1473 SensorF_OD_CAN2_Status 1;
BA_ "CANzero_SDO_Group" SG_ 1473 SensorF_OD_CAN2_Baudrate "CAN";
BA_ "CANzero_SDO_AccessIfOperational" SG_ 1473 SensorF_OD_CAN2_Baudrate 1;
BA_ "GenSigStartValue" SG_ 1473 SensorF_OD_CAN2_Baudrate 1000.0;
BA_ "CANzero_SDO_Default" SG_ 1473 SensorF_OD_CAN2_Baudrate 1000;
BA_ "CANzero_SDO_Group" SG_ 1473 SensorF_OD_CAN2_autoErrorReset "CAN";
BA_ "CANzero_SDO_AccessIfOperational" SG_ 1473 SensorF_OD_CAN2_autoErrorReset 1;
BA_ "GenSigStartValue" SG_ 1473 SensorF_OD_CAN2_autoErrorReset 1.0;
BA_ "CANzero_SDO_Default" SG_ 1473 SensorF_OD_CAN2_autoErrorReset 1;
BA_ "CANzero_SDO_Group" SG_ 1473 SensorF_OD_CAN2_lastErrorCode "CAN";
BA_ "CANzero_SDO_AccessType" SG_ 1473 SensorF_OD_CAN2_lastErrorCode 1;
BA_ "CANzero_SDO_AccessIfOperational" SG_ 1473 SensorF_OD_CAN2_lastErrorCode 1;
BA_ "CANzero_SDO_Group" SG_ 1473 SensorF_OD_CAN2_RxErrCnt "CAN";
BA_ "CANzero_SDO_AccessType" SG_ 1473 SensorF_OD_CAN2_RxErrCnt 1;
BA_ "CANzero_SDO_AccessIfOperational" SG_ 1473 SensorF_OD_CAN2_RxErrCnt 1;
BA_ "CANzero_SDO_Group" SG_ 1473 SensorF_OD_CAN2_TxErrCnt "CAN";
BA_ "CANzero_SDO_AccessType" SG_ 1473 SensorF_OD_CAN2_TxErrCnt 1;
BA_ "CANzero_SDO_AccessIfOperational" SG_ 1473 SensorF_OD_CAN2_TxErrCnt 1;
BA_ "CANzero_SDO_Group" SG_ 1473 SensorF_OD_CAN1_DelayedTxMe_0000 "CAN";
BA_ "CANzero_SDO_AccessType" SG_ 1473 SensorF_OD_CAN1_DelayedTxMe_0000 1;
BA_ "CANzero_SDO_AccessIfOperational" SG_ 1473 SensorF_OD_CAN1_DelayedTxMe_0000 1;
BA_ "SystemSignalLongSymbol" SG_ 1473 SensorF_OD_CAN1_DelayedTxMe_0000 "SensorF_OD_CAN1_DelayedTxMessages";
BA_ "CANzero_SDO_Group" SG_ 1473 SensorF_OD_CAN1_ErrorStatus "CAN";
BA_ "CANzero_SDO_AccessType" SG_ 1473 SensorF_OD_CAN1_ErrorStatus 1;
BA_ "CANzero_SDO_AccessIfOperational" SG_ 1473 SensorF_OD_CAN1_ErrorStatus 1;
BA_ "CANzero_SDO_Group" SG_ 1473 SensorF_OD_CAN1_DiscardedTx_0000 "CAN";
BA_ "CANzero_SDO_AccessType" SG_ 1473 SensorF_OD_CAN1_DiscardedTx_0000 1;
BA_ "CANzero_SDO_AccessIfOperational" SG_ 1473 SensorF_OD_CAN1_DiscardedTx_0000 1;
BA_ "SystemSignalLongSymbol" SG_ 1473 SensorF_OD_CAN1_DiscardedTx_0000 "SensorF_OD_CAN1_DiscardedTxMessages";
BA_ "CANzero_SDO_Group" SG_ 1473 SensorF_OD_CAN1_Status "CAN";
BA_ "CANzero_SDO_AccessType" SG_ 1473 SensorF_OD_CAN1_Status 1;
BA_ "CANzero_SDO_AccessIfOperational" SG_ 1473 SensorF_OD_CAN1_Status 1;
BA_ "CANzero_SDO_Group" SG_ 1473 SensorF_OD_CAN1_Baudrate "CAN";
BA_ "CANzero_SDO_AccessIfOperational" SG_ 1473 SensorF_OD_CAN1_Baudrate 1;
BA_ "GenSigStartValue" SG_ 1473 SensorF_OD_CAN1_Baudrate 1000.0;
BA_ "CANzero_SDO_Default" SG_ 1473 SensorF_OD_CAN1_Baudrate 1000;
BA_ "CANzero_SDO_Group" SG_ 1473 SensorF_OD_CAN1_autoErrorReset "CAN";
BA_ "CANzero_SDO_AccessIfOperational" SG_ 1473 SensorF_OD_CAN1_autoErrorReset 1;
BA_ "GenSigStartValue" SG_ 1473 SensorF_OD_CAN1_autoErrorReset 1.0;
BA_ "CANzero_SDO_Default" SG_ 1473 SensorF_OD_CAN1_autoErrorReset 1;
BA_ "CANzero_SDO_Group" SG_ 1473 SensorF_OD_CAN1_lastErrorCode "CAN";
BA_ "CANzero_SDO_AccessType" SG_ 1473 SensorF_OD_CAN1_lastErrorCode 1;
BA_ "CANzero_SDO_AccessIfOperational" SG_ 1473 SensorF_OD_CAN1_lastErrorCode 1;
BA_ "CANzero_SDO_Group" SG_ 1473 SensorF_OD_CAN1_RxErrCnt "CAN";
BA_ "CANzero_SDO_AccessType" SG_ 1473 SensorF_OD_CAN1_RxErrCnt 1;
BA_ "CANzero_SDO_AccessIfOperational" SG_ 1473 SensorF_OD_CAN1_RxErrCnt 1;
BA_ "CANzero_SDO_Group" SG_ 1473 SensorF_OD_CAN1_TxErrCnt "CAN";
BA_ "CANzero_SDO_AccessType" SG_ 1473 SensorF_OD_CAN1_TxErrCnt 1;
BA_ "CANzero_SDO_AccessIfOperational" SG_ 1473 SensorF_OD_CAN1_TxErrCnt 1;
BA_ "CANzero_SDO_AccessType" SG_ 1473 SensorF_OD_BuildTime 1;
BA_ "CANzero_SDO_AccessIfOperational" SG_ 1473 SensorF_OD_BuildTime 1;
BA_ "CANzero_SDO_AccessType" SG_ 1473 SensorF_OD_BuildDate 1;
BA_ "CANzero_SDO_AccessIfOperational" SG_ 1473 SensorF_OD_BuildDate 1;
BA_ "CANzero_SDO_AccessType" SG_ 1473 SensorF_OD_ChipUID2 1;
BA_ "CANzero_SDO_AccessIfOperational" SG_ 1473 SensorF_OD_ChipUID2 1;
BA_ "CANzero_SDO_AccessType" SG_ 1473 SensorF_OD_ChipUID1 1;
BA_ "CANzero_SDO_AccessIfOperational" SG_ 1473 SensorF_OD_ChipUID1 1;
BA_ "CANzero_SDO_AccessType" SG_ 1473 SensorF_OD_SdcOut 1;
BA_ "CANzero_SDO_AccessIfOperational" SG_ 1473 SensorF_OD_SdcOut 1;
BA_ "CANzero_SDO_AccessType" SG_ 1473 SensorF_OD_SdcIn 1;
BA_ "CANzero_SDO_AccessIfOperational" SG_ 1473 SensorF_OD_SdcIn 1;
BA_ "CANzero_SDO_AccessType" SG_ 1473 SensorF_OD_runtime 1;
BA_ "CANzero_SDO_AccessIfOperational" SG_ 1473 SensorF_OD_runtime 1;
BA_ "CANzero_SDO_AccessType" SG_ 1473 SensorF_OD_InputVoltage 1;
BA_ "CANzero_SDO_AccessIfOperational" SG_ 1473 SensorF_OD_InputVoltage 1;
BA_ "CANzero_SDO_AccessType" SG_ 1473 SensorF_OD_BoardTemp 1;
BA_ "CANzero_SDO_AccessIfOperational" SG_ 1473 SensorF_OD_BoardTemp 1;
BA_ "GenSigStartValue" SG_ 1473 SensorF_OD_BoardTemp 3000.0;
BA_ "CANzero_SDO_AccessType" SG_ 1473 SensorF_OD_MemFree 1;
BA_ "CANzero_SDO_AccessIfOperational" SG_ 1473 SensorF_OD_MemFree 1;
BA_ "CANzero_SDO_AccessType" SG_ 1473 SensorF_OD_CpuUsage 1;
BA_ "CANzero_SDO_AccessIfOperational" SG_ 1473 SensorF_OD_CpuUsage 1;
BA_ "CANzero_SDO_AccessIfOperational" SG_ 1473 SensorF_OD_OdEntrySendInterval 1;
BA_ "GenSigStartValue" SG_ 1473 SensorF_OD_OdEntrySendInterval 50.0;
BA_ "CANzero_SDO_Default" SG_ 1473 SensorF_OD_OdEntrySendInterval 50;
BA_ "CANzero_SDO_AccessIfOperational" SG_ 1473 SensorF_OD_SendOdOnBootup 1;
BA_ "CANzero_SDO_AccessIfOperational" SG_ 1473 SensorF_OD_HeartbeatInterval 1;
BA_ "GenSigStartValue" SG_ 1473 SensorF_OD_HeartbeatInterval 250.0;
BA_ "CANzero_SDO_Default" SG_ 1473 SensorF_OD_HeartbeatInterval 250;
BA_ "CANzero_SDO_AccessType" SG_ 1473 SensorF_OD_DbcVersion 1;
BA_ "CANzero_SDO_AccessIfOperational" SG_ 1473 SensorF_OD_DbcVersion 1;
BA_ "CANzero_SDO_AccessType" SG_ 1473 SensorF_OD_StackVersion 1;
BA_ "CANzero_SDO_AccessIfOperational" SG_ 1473 SensorF_OD_StackVersion 1;
BA_ "CANzero_SDO_AccessType" SG_ 1473 SensorF_OD_ProtocolVersion 1;
BA_ "CANzero_SDO_AccessIfOperational" SG_ 1473 SensorF_OD_ProtocolVersion 1;
BA_ "GenSigStartValue" SG_ 1473 SensorF_OD_ProtocolVersion 1.0;
BA_ "CANzero_SDO_Default" SG_ 1473 SensorF_OD_ProtocolVersion 1;
BA_ "CANzero_SDO_AccessType" SG_ 1473 SensorF_OD_NodeStatus 1;
BA_ "CANzero_SDO_AccessIfOperational" SG_ 1473 SensorF_OD_NodeStatus 1;
BA_ "CANzero_SDO_AccessType" SG_ 1473 SensorF_OD_NodeID 1;
BA_ "CANzero_SDO_AccessIfOperational" SG_ 1473 SensorF_OD_NodeID 1;
BA_ "SystemSignalLongSymbol" SG_ 130 SensorR_E11_scimoPEerror101overc "SensorR_E11_scimoPEerror101overcurrent";
BA_ "SystemSignalLongSymbol" SG_ 130 SensorR_E10_scimoPEerror103sumcu "SensorR_E10_scimoPEerror103sumcurrent";
BA_ "SystemSignalLongSymbol" SG_ 130 SensorR_E9_scimoPEerror102overcu "SensorR_E9_scimoPEerror102overcurrent";
BA_ "SystemSignalLongSymbol" SG_ 130 SensorR_E8_scimoPEerror024motTem "SensorR_E8_scimoPEerror024motTemp";
BA_ "SystemSignalLongSymbol" SG_ 130 SensorR_E6_scimoPEerror009Pulslo "SensorR_E6_scimoPEerror009Pulslock";
BA_ "SystemSignalLongSymbol" SG_ 130 SensorR_W8_outOfLimModelBoundari "SensorR_W8_outOfLimModelBoundaries";
BA_ "SystemSignalLongSymbol" SG_ 130 SensorR_W6_sciMoPEwarning104FETt "SensorR_W6_sciMoPEwarning104FETtemp";
BA_ "SystemSignalLongSymbol" SG_ 130 SensorR_W5_sciMoPEwarning069CPUt "SensorR_W5_sciMoPEwarning069CPUtemp";
BA_ "SystemSignalLongSymbol" SG_ 130 SensorR_W4_stateEstimationAccWar "SensorR_W4_stateEstimationAccWarning";
BA_ "SystemSignalLongSymbol" SG_ 130 SensorR_W3_stateEstimationPosWar "SensorR_W3_stateEstimationPosWarning";
BA_ "SystemSignalLongSymbol" SG_ 130 SensorR_W2_stateEstimationVelWar "SensorR_W2_stateEstimationVelWarning";
BA_ "GenSigStartValue" SG_ 1154 SensorR_LIMT_Coil_3 50;
BA_ "GenSigStartValue" SG_ 1154 SensorR_LIMT_Coil_2 50;
BA_ "GenSigStartValue" SG_ 1154 SensorR_LIMT_Coil_1 50;
BA_ "CANzero_SDO_AccessIfOperational" SG_ 1410 SensorR_OD_posDeviationOptic 1;
BA_ "GenSigStartValue" SG_ 1410 SensorR_OD_posDeviationOptic 40.0;
BA_ "CANzero_SDO_Default" SG_ 1410 SensorR_OD_posDeviationOptic 4;
BA_ "CANzero_SDO_AccessIfOperational" SG_ 1410 SensorR_OD_posDeviationEncoder 1;
BA_ "GenSigStartValue" SG_ 1410 SensorR_OD_posDeviationEncoder 40.0;
BA_ "CANzero_SDO_Default" SG_ 1410 SensorR_OD_posDeviationEncoder 4;
BA_ "CANzero_SDO_AccessIfOperational" SG_ 1410 SensorR_OD_velDeviationOptic 1;
BA_ "GenSigStartValue" SG_ 1410 SensorR_OD_velDeviationOptic 20.0;
BA_ "CANzero_SDO_Default" SG_ 1410 SensorR_OD_velDeviationOptic 2;
BA_ "CANzero_SDO_AccessIfOperational" SG_ 1410 SensorR_OD_velDeviationEncoder 1;
BA_ "GenSigStartValue" SG_ 1410 SensorR_OD_velDeviationEncoder 20.0;
BA_ "CANzero_SDO_Default" SG_ 1410 SensorR_OD_velDeviationEncoder 2;
BA_ "CANzero_SDO_AccessIfOperational" SG_ 1410 SensorR_OD_accDeviation 1;
BA_ "GenSigStartValue" SG_ 1410 SensorR_OD_accDeviation 40.0;
BA_ "CANzero_SDO_Default" SG_ 1410 SensorR_OD_accDeviation 4;
BA_ "CANzero_SDO_AccessIfOperational" SG_ 1410 SensorR_OD_EnableSignalGeneratio 1;
BA_ "SystemSignalLongSymbol" SG_ 1410 SensorR_OD_EnableSignalGeneratio "SensorR_OD_EnableSignalGeneration";
BA_ "CANzero_SDO_AccessIfOperational" SG_ 1410 SensorR_OD_PositionGlitch 1;
BA_ "GenSigStartValue" SG_ 1410 SensorR_OD_PositionGlitch 50.0;
BA_ "CANzero_SDO_Default" SG_ 1410 SensorR_OD_PositionGlitch 5;
BA_ "CANzero_SDO_AccessIfOperational" SG_ 1410 SensorR_OD_ReflectorDistance 1;
BA_ "GenSigStartValue" SG_ 1410 SensorR_OD_ReflectorDistance 200.0;
BA_ "CANzero_SDO_Default" SG_ 1410 SensorR_OD_ReflectorDistance 20;
BA_ "CANzero_SDO_AccessIfOperational" SG_ 1410 SensorR_OD_StripeMode 1;
BA_ "GenSigStartValue" SG_ 1410 SensorR_OD_StripeMode 1.0;
BA_ "CANzero_SDO_Default" SG_ 1410 SensorR_OD_StripeMode 1;
BA_ "CANzero_SDO_AccessIfOperational" SG_ 1410 SensorR_OD_opc_lowpass_TcI 1;
BA_ "GenSigStartValue" SG_ 1410 SensorR_OD_opc_lowpass_TcI 2.0;
BA_ "CANzero_SDO_Default" SG_ 1410 SensorR_OD_opc_lowpass_TcI 0.02;
BA_ "CANzero_SDO_AccessIfOperational" SG_ 1410 SensorR_OD_opc_lowpass_Tcf 1;
BA_ "GenSigStartValue" SG_ 1410 SensorR_OD_opc_lowpass_Tcf 2.0;
BA_ "CANzero_SDO_Default" SG_ 1410 SensorR_OD_opc_lowpass_Tcf 0.02;
BA_ "CANzero_SDO_AccessIfOperational" SG_ 1410 SensorR_OD_opc_F_decrease 1;
BA_ "GenSigStartValue" SG_ 1410 SensorR_OD_opc_F_decrease 25.0;
BA_ "CANzero_SDO_Default" SG_ 1410 SensorR_OD_opc_F_decrease 0.25;
BA_ "CANzero_SDO_AccessIfOperational" SG_ 1410 SensorR_OD_opc_v_threshold 1;
BA_ "GenSigStartValue" SG_ 1410 SensorR_OD_opc_v_threshold 25.0;
BA_ "CANzero_SDO_Default" SG_ 1410 SensorR_OD_opc_v_threshold 0.25;
BA_ "CANzero_SDO_AccessIfOperational" SG_ 1410 SensorR_OD_opc_v_max 1;
BA_ "GenSigStartValue" SG_ 1410 SensorR_OD_opc_v_max 200.0;
BA_ "CANzero_SDO_Default" SG_ 1410 SensorR_OD_opc_v_max 2.0;
BA_ "CANzero_SDO_AccessIfOperational" SG_ 1410 SensorR_OD_opc_T_acc 1;
BA_ "GenSigStartValue" SG_ 1410 SensorR_OD_opc_T_acc 20.0;
BA_ "CANzero_SDO_Default" SG_ 1410 SensorR_OD_opc_T_acc 2.0;
BA_ "CANzero_SDO_AccessIfOperational" SG_ 1410 SensorR_OD_opc_F_max 1;
BA_ "GenSigStartValue" SG_ 1410 SensorR_OD_opc_F_max 90.0;
BA_ "CANzero_SDO_Default" SG_ 1410 SensorR_OD_opc_F_max 90;
BA_ "CANzero_SDO_AccessIfOperational" SG_ 1410 SensorR_OD_opc_t_run_max 1;
BA_ "GenSigStartValue" SG_ 1410 SensorR_OD_opc_t_run_max 40.0;
BA_ "CANzero_SDO_Default" SG_ 1410 SensorR_OD_opc_t_run_max 4.0;
BA_ "CANzero_SDO_AccessIfOperational" SG_ 1410 SensorR_OD_opc_brakeFlag 1;
BA_ "CANzero_SDO_AccessIfOperational" SG_ 1410 SensorR_OD_DebugCVOPCfreq 1;
BA_ "GenSigStartValue" SG_ 1410 SensorR_OD_DebugCVOPCfreq 32000.0;
BA_ "CANzero_SDO_AccessIfOperational" SG_ 1410 SensorR_OD_DebugCascadedIreq 1;
BA_ "GenSigStartValue" SG_ 1410 SensorR_OD_DebugCascadedIreq 32000.0;
BA_ "CANzero_SDO_AccessIfOperational" SG_ 1410 SensorR_OD_opc_ratelimiter_f 1;
BA_ "GenSigStartValue" SG_ 1410 SensorR_OD_opc_ratelimiter_f 37000.0;
BA_ "CANzero_SDO_Default" SG_ 1410 SensorR_OD_opc_ratelimiter_f 500;
BA_ "CANzero_SDO_AccessIfOperational" SG_ 1410 SensorR_OD_maxRunDistance 1;
BA_ "GenSigStartValue" SG_ 1410 SensorR_OD_maxRunDistance 38000.0;
BA_ "CANzero_SDO_Default" SG_ 1410 SensorR_OD_maxRunDistance 300;
BA_ "CANzero_SDO_AccessIfOperational" SG_ 1410 SensorR_OD_FinishedDelay 1;
BA_ "GenSigStartValue" SG_ 1410 SensorR_OD_FinishedDelay 2500.0;
BA_ "CANzero_SDO_Default" SG_ 1410 SensorR_OD_FinishedDelay 2500;
BA_ "CANzero_SDO_AccessIfOperational" SG_ 1410 SensorR_OD_Current4Stopping 1;
BA_ "GenSigStartValue" SG_ 1410 SensorR_OD_Current4Stopping 500.0;
BA_ "CANzero_SDO_Default" SG_ 1410 SensorR_OD_Current4Stopping 50.0;
BA_ "CANzero_SDO_AccessIfOperational" SG_ 1410 SensorR_OD_AdaptModelByCurrent 1;
BA_ "CANzero_SDO_AccessIfOperational" SG_ 1410 SensorR_OD_CVOPCTcFreq 1;
BA_ "GenSigStartValue" SG_ 1410 SensorR_OD_CVOPCTcFreq 100.0;
BA_ "CANzero_SDO_Default" SG_ 1410 SensorR_OD_CVOPCTcFreq 100;
BA_ "CANzero_SDO_AccessIfOperational" SG_ 1410 SensorR_OD_CVOPCImin 1;
BA_ "GenSigStartValue" SG_ 1410 SensorR_OD_CVOPCImin 50.0;
BA_ "CANzero_SDO_Default" SG_ 1410 SensorR_OD_CVOPCImin 50;
BA_ "CANzero_SDO_AccessIfOperational" SG_ 1410 SensorR_OD_CascadedKpDecreaseCur 1;
BA_ "GenSigStartValue" SG_ 1410 SensorR_OD_CascadedKpDecreaseCur 400.0;
BA_ "CANzero_SDO_Default" SG_ 1410 SensorR_OD_CascadedKpDecreaseCur 40.0;
BA_ "SystemSignalLongSymbol" SG_ 1410 SensorR_OD_CascadedKpDecreaseCur "SensorR_OD_CascadedKpDecreaseCurrent";
BA_ "CANzero_SDO_AccessIfOperational" SG_ 1410 SensorR_OD_CascadedKpIncreaseCur 1;
BA_ "GenSigStartValue" SG_ 1410 SensorR_OD_CascadedKpIncreaseCur 400.0;
BA_ "CANzero_SDO_Default" SG_ 1410 SensorR_OD_CascadedKpIncreaseCur 40.0;
BA_ "SystemSignalLongSymbol" SG_ 1410 SensorR_OD_CascadedKpIncreaseCur "SensorR_OD_CascadedKpIncreaseCurrent";
BA_ "CANzero_SDO_AccessIfOperational" SG_ 1410 SensorR_OD_CascadedFreqCurUpdate 1;
BA_ "GenSigStartValue" SG_ 1410 SensorR_OD_CascadedFreqCurUpdate 100.0;
BA_ "CANzero_SDO_Default" SG_ 1410 SensorR_OD_CascadedFreqCurUpdate 0.1;
BA_ "CANzero_SDO_AccessIfOperational" SG_ 1410 SensorR_OD_CascadedMaxSetForceDe 1;
BA_ "GenSigStartValue" SG_ 1410 SensorR_OD_CascadedMaxSetForceDe 1000.0;
BA_ "CANzero_SDO_Default" SG_ 1410 SensorR_OD_CascadedMaxSetForceDe 100;
BA_ "SystemSignalLongSymbol" SG_ 1410 SensorR_OD_CascadedMaxSetForceDe "SensorR_OD_CascadedMaxSetForceDelta";
BA_ "CANzero_SDO_AccessIfOperational" SG_ 1410 SensorR_OD_CurrentForConstantVel 1;
BA_ "GenSigStartValue" SG_ 1410 SensorR_OD_CurrentForConstantVel 8000.0;
BA_ "CANzero_SDO_Default" SG_ 1410 SensorR_OD_CurrentForConstantVel 80.0;
BA_ "SystemSignalLongSymbol" SG_ 1410 SensorR_OD_CurrentForConstantVel "SensorR_OD_CurrentForConstantVelocity";
BA_ "CANzero_SDO_AccessIfOperational" SG_ 1410 SensorR_OD_AccAtCurrentMeasured 1;
BA_ "GenSigStartValue" SG_ 1410 SensorR_OD_AccAtCurrentMeasured 7700.0;
BA_ "CANzero_SDO_Default" SG_ 1410 SensorR_OD_AccAtCurrentMeasured 77.0;
BA_ "CANzero_SDO_AccessIfOperational" SG_ 1410 SensorR_OD_CVOPCHystereseF 1;
BA_ "GenSigStartValue" SG_ 1410 SensorR_OD_CVOPCHystereseF 4000.0;
BA_ "CANzero_SDO_Default" SG_ 1410 SensorR_OD_CVOPCHystereseF 400;
BA_ "CANzero_SDO_AccessIfOperational" SG_ 1410 SensorR_OD_CVOPCReduceCurrentWhi 1;
BA_ "GenSigStartValue" SG_ 1410 SensorR_OD_CVOPCReduceCurrentWhi 90.0;
BA_ "CANzero_SDO_Default" SG_ 1410 SensorR_OD_CVOPCReduceCurrentWhi 0.9;
BA_ "SystemSignalLongSymbol" SG_ 1410 SensorR_OD_CVOPCReduceCurrentWhi "SensorR_OD_CVOPCReduceCurrentWhileCruising";
BA_ "CANzero_SDO_AccessIfOperational" SG_ 1410 SensorR_OD_CVOPCDeltaVelHigherCu 1;
BA_ "GenSigStartValue" SG_ 1410 SensorR_OD_CVOPCDeltaVelHigherCu 30.0;
BA_ "CANzero_SDO_Default" SG_ 1410 SensorR_OD_CVOPCDeltaVelHigherCu 0.3;
BA_ "SystemSignalLongSymbol" SG_ 1410 SensorR_OD_CVOPCDeltaVelHigherCu "SensorR_OD_CVOPCDeltaVelHigherCurrent";
BA_ "CANzero_SDO_AccessIfOperational" SG_ 1410 SensorR_OD_CVOPCSmoothingDeltaVe 1;
BA_ "GenSigStartValue" SG_ 1410 SensorR_OD_CVOPCSmoothingDeltaVe 5.0;
BA_ "CANzero_SDO_Default" SG_ 1410 SensorR_OD_CVOPCSmoothingDeltaVe 0.05;
BA_ "SystemSignalLongSymbol" SG_ 1410 SensorR_OD_CVOPCSmoothingDeltaVe "SensorR_OD_CVOPCSmoothingDeltaVelocity";
BA_ "CANzero_SDO_AccessIfOperational" SG_ 1410 SensorR_OD_CVOPCTcI 1;
BA_ "GenSigStartValue" SG_ 1410 SensorR_OD_CVOPCTcI 300.0;
BA_ "CANzero_SDO_Default" SG_ 1410 SensorR_OD_CVOPCTcI 300;
BA_ "CANzero_SDO_AccessIfOperational" SG_ 1410 SensorR_OD_CVOPCTcf 1;
BA_ "GenSigStartValue" SG_ 1410 SensorR_OD_CVOPCTcf 1000.0;
BA_ "CANzero_SDO_Default" SG_ 1410 SensorR_OD_CVOPCTcf 1000;
BA_ "CANzero_SDO_AccessIfOperational" SG_ 1410 SensorR_OD_CVOPCImax 1;
BA_ "GenSigStartValue" SG_ 1410 SensorR_OD_CVOPCImax 200.0;
BA_ "CANzero_SDO_Default" SG_ 1410 SensorR_OD_CVOPCImax 200;
BA_ "CANzero_SDO_AccessIfOperational" SG_ 1410 SensorR_OD_VelocityController 1;
BA_ "CANzero_SDO_AccessIfOperational" SG_ 1410 SensorR_OD_TC_f 1;
BA_ "GenSigStartValue" SG_ 1410 SensorR_OD_TC_f 150.0;
BA_ "CANzero_SDO_Default" SG_ 1410 SensorR_OD_TC_f 150;
BA_ "CANzero_SDO_AccessIfOperational" SG_ 1410 SensorR_OD_TC_I 1;
BA_ "GenSigStartValue" SG_ 1410 SensorR_OD_TC_I 150.0;
BA_ "CANzero_SDO_Default" SG_ 1410 SensorR_OD_TC_I 150;
BA_ "CANzero_SDO_AccessType" SG_ 1410 SensorR_OD_EstimatedRunLength 1;
BA_ "CANzero_SDO_AccessIfOperational" SG_ 1410 SensorR_OD_EstimatedRunLength 1;
BA_ "GenSigStartValue" SG_ 1410 SensorR_OD_EstimatedRunLength 32000.0;
BA_ "CANzero_SDO_AccessIfOperational" SG_ 1410 SensorR_OD_RunProfile_V4 1;
BA_ "GenSigStartValue" SG_ 1410 SensorR_OD_RunProfile_V4 32700.0;
BA_ "CANzero_SDO_AccessIfOperational" SG_ 1410 SensorR_OD_RunProfile_T4 1;
BA_ "GenSigStartValue" SG_ 1410 SensorR_OD_RunProfile_T4 450.0;
BA_ "CANzero_SDO_Default" SG_ 1410 SensorR_OD_RunProfile_T4 4500;
BA_ "CANzero_SDO_AccessIfOperational" SG_ 1410 SensorR_OD_RunProfile_V3 1;
BA_ "GenSigStartValue" SG_ 1410 SensorR_OD_RunProfile_V3 32800.0;
BA_ "CANzero_SDO_Default" SG_ 1410 SensorR_OD_RunProfile_V3 1;
BA_ "CANzero_SDO_AccessIfOperational" SG_ 1410 SensorR_OD_RunProfile_T3 1;
BA_ "GenSigStartValue" SG_ 1410 SensorR_OD_RunProfile_T3 350.0;
BA_ "CANzero_SDO_Default" SG_ 1410 SensorR_OD_RunProfile_T3 3500;
BA_ "CANzero_SDO_AccessIfOperational" SG_ 1410 SensorR_OD_RunProfile_V2 1;
BA_ "GenSigStartValue" SG_ 1410 SensorR_OD_RunProfile_V2 32800.0;
BA_ "CANzero_SDO_Default" SG_ 1410 SensorR_OD_RunProfile_V2 1;
BA_ "CANzero_SDO_AccessIfOperational" SG_ 1410 SensorR_OD_RunProfile_T2 1;
BA_ "GenSigStartValue" SG_ 1410 SensorR_OD_RunProfile_T2 300.0;
BA_ "CANzero_SDO_Default" SG_ 1410 SensorR_OD_RunProfile_T2 3000;
BA_ "CANzero_SDO_AccessIfOperational" SG_ 1410 SensorR_OD_RunProfile_V1 1;
BA_ "GenSigStartValue" SG_ 1410 SensorR_OD_RunProfile_V1 32705.0;
BA_ "CANzero_SDO_Default" SG_ 1410 SensorR_OD_RunProfile_V1 0.05;
BA_ "CANzero_SDO_AccessIfOperational" SG_ 1410 SensorR_OD_RunProfile_T1 1;
BA_ "GenSigStartValue" SG_ 1410 SensorR_OD_RunProfile_T1 100.0;
BA_ "CANzero_SDO_Default" SG_ 1410 SensorR_OD_RunProfile_T1 1000;
BA_ "CANzero_SDO_AccessIfOperational" SG_ 1410 SensorR_OD_RunProfile_V0 1;
BA_ "GenSigStartValue" SG_ 1410 SensorR_OD_RunProfile_V0 32700.0;
BA_ "CANzero_SDO_AccessIfOperational" SG_ 1410 SensorR_OD_RunProfile_T0 1;
BA_ "CANzero_SDO_AccessIfOperational" SG_ 1410 SensorR_OD_SetFinish 1;
BA_ "CANzero_SDO_AccessIfOperational" SG_ 1410 SensorR_OD_RunMode 1;
BA_ "CANzero_SDO_AccessIfOperational" SG_ 1410 SensorR_OD_VdcReduceFactor 1;
BA_ "GenSigStartValue" SG_ 1410 SensorR_OD_VdcReduceFactor 9.499999999999998;
BA_ "CANzero_SDO_Default" SG_ 1410 SensorR_OD_VdcReduceFactor 0.95;
BA_ "CANzero_SDO_AccessIfOperational" SG_ 1410 SensorR_OD_MaxRequiredVelocity 1;
BA_ "GenSigStartValue" SG_ 1410 SensorR_OD_MaxRequiredVelocity 190.0;
BA_ "CANzero_SDO_Default" SG_ 1410 SensorR_OD_MaxRequiredVelocity 19;
BA_ "CANzero_SDO_AccessIfOperational" SG_ 1410 SensorR_OD_WarningThreshholdForL 1;
BA_ "GenSigStartValue" SG_ 1410 SensorR_OD_WarningThreshholdForL 900.0;
BA_ "CANzero_SDO_Default" SG_ 1410 SensorR_OD_WarningThreshholdForL 0.9;
BA_ "SystemSignalLongSymbol" SG_ 1410 SensorR_OD_WarningThreshholdForL "SensorR_OD_WarningThreshholdForLimModelOutOfBoundaries";
BA_ "CANzero_SDO_AccessIfOperational" SG_ 1410 SensorR_OD_MaxCtrlErrorDuration 1;
BA_ "GenSigStartValue" SG_ 1410 SensorR_OD_MaxCtrlErrorDuration 50.0;
BA_ "CANzero_SDO_Default" SG_ 1410 SensorR_OD_MaxCtrlErrorDuration 0.5;
BA_ "CANzero_SDO_AccessIfOperational" SG_ 1410 SensorR_OD_MaxCtrlError 1;
BA_ "GenSigStartValue" SG_ 1410 SensorR_OD_MaxCtrlError 150.0;
BA_ "CANzero_SDO_Default" SG_ 1410 SensorR_OD_MaxCtrlError 1.5;
BA_ "CANzero_SDO_AccessIfOperational" SG_ 1410 SensorR_OD_FminCtrl 1;
BA_ "GenSigStartValue" SG_ 1410 SensorR_OD_FminCtrl 922.0;
BA_ "CANzero_SDO_Default" SG_ 1410 SensorR_OD_FminCtrl 922;
BA_ "CANzero_SDO_AccessIfOperational" SG_ 1410 SensorR_OD_FmaxCtrl 1;
BA_ "GenSigStartValue" SG_ 1410 SensorR_OD_FmaxCtrl 1004.0;
BA_ "CANzero_SDO_Default" SG_ 1410 SensorR_OD_FmaxCtrl 1004;
BA_ "CANzero_SDO_AccessIfOperational" SG_ 1410 SensorR_OD_PodMass 1;
BA_ "GenSigStartValue" SG_ 1410 SensorR_OD_PodMass 2300.0;
BA_ "CANzero_SDO_Default" SG_ 1410 SensorR_OD_PodMass 230.0;
BA_ "CANzero_SDO_AccessIfOperational" SG_ 1410 SensorR_OD_CurrentReq 1;
BA_ "GenSigStartValue" SG_ 1410 SensorR_OD_CurrentReq 1050.0;
BA_ "CANzero_SDO_Default" SG_ 1410 SensorR_OD_CurrentReq 105.0;
BA_ "CANzero_SDO_AccessIfOperational" SG_ 1410 SensorR_OD_CtrlMode 1;
BA_ "GenSigStartValue" SG_ 1410 SensorR_OD_CtrlMode 1.0;
BA_ "CANzero_SDO_Default" SG_ 1410 SensorR_OD_CtrlMode 1;
BA_ "CANzero_SDO_AccessIfOperational" SG_ 1410 SensorR_OD_OpcKi 1;
BA_ "GenSigStartValue" SG_ 1410 SensorR_OD_OpcKi 50.0;
BA_ "CANzero_SDO_Default" SG_ 1410 SensorR_OD_OpcKi 0.5;
BA_ "CANzero_SDO_AccessIfOperational" SG_ 1410 SensorR_OD_OpcKp 1;
BA_ "GenSigStartValue" SG_ 1410 SensorR_OD_OpcKp 600.0;
BA_ "CANzero_SDO_Default" SG_ 1410 SensorR_OD_OpcKp 6.0;
BA_ "CANzero_SDO_AccessIfOperational" SG_ 1410 SensorR_OD_ExecTimeReadSensors 1;
BA_ "CANzero_SDO_AccessIfOperational" SG_ 1410 SensorR_OD_ExecTimeControl 1;
BA_ "CANzero_SDO_AccessIfOperational" SG_ 1410 SensorR_OD_ExecTimeStateEst 1;
BA_ "CANzero_SDO_AccessIfOperational" SG_ 1410 SensorR_OD_ExecTimeOverall 1;
BA_ "CANzero_SDO_AccessType" SG_ 1410 SensorR_OD_IMU3_Temperature 1;
BA_ "CANzero_SDO_AccessIfOperational" SG_ 1410 SensorR_OD_IMU3_Temperature 1;
BA_ "GenSigStartValue" SG_ 1410 SensorR_OD_IMU3_Temperature 10000.0;
BA_ "CANzero_SDO_AccessType" SG_ 1410 SensorR_OD_IMU2_Temperature 1;
BA_ "CANzero_SDO_AccessIfOperational" SG_ 1410 SensorR_OD_IMU2_Temperature 1;
BA_ "GenSigStartValue" SG_ 1410 SensorR_OD_IMU2_Temperature 10000.0;
BA_ "CANzero_SDO_AccessType" SG_ 1410 SensorR_OD_IMU1_Temperature 1;
BA_ "CANzero_SDO_AccessIfOperational" SG_ 1410 SensorR_OD_IMU1_Temperature 1;
BA_ "GenSigStartValue" SG_ 1410 SensorR_OD_IMU1_Temperature 10000.0;
BA_ "CANzero_SDO_AccessType" SG_ 1410 SensorR_OD_IMU_number 1;
BA_ "CANzero_SDO_AccessIfOperational" SG_ 1410 SensorR_OD_IMU_number 1;
BA_ "CANzero_SDO_AccessType" SG_ 1410 SensorR_OD_EncoderResetPosition 2;
BA_ "CANzero_SDO_AccessIfOperational" SG_ 1410 SensorR_OD_EncoderResetPosition 1;
BA_ "CANzero_SDO_AccessIfOperational" SG_ 1410 SensorR_OD_EncoderWheelDiameter 1;
BA_ "GenSigStartValue" SG_ 1410 SensorR_OD_EncoderWheelDiameter 15000.0;
BA_ "CANzero_SDO_Default" SG_ 1410 SensorR_OD_EncoderWheelDiameter 75;
BA_ "CANzero_SDO_AccessIfOperational" SG_ 1410 SensorR_OD_samplingInterval 1;
BA_ "GenSigStartValue" SG_ 1410 SensorR_OD_samplingInterval 1000.0;
BA_ "CANzero_SDO_Default" SG_ 1410 SensorR_OD_samplingInterval 10;
BA_ "CANzero_SDO_Group" SG_ 1410 SensorR_OD_CAN2_DelayedTxMessage "CAN";
BA_ "CANzero_SDO_AccessType" SG_ 1410 SensorR_OD_CAN2_DelayedTxMessage 1;
BA_ "CANzero_SDO_AccessIfOperational" SG_ 1410 SensorR_OD_CAN2_DelayedTxMessage 1;
BA_ "SystemSignalLongSymbol" SG_ 1410 SensorR_OD_CAN2_DelayedTxMessage "SensorR_OD_CAN2_DelayedTxMessages";
BA_ "CANzero_SDO_Group" SG_ 1410 SensorR_OD_CAN2_ErrorStatus "CAN";
BA_ "CANzero_SDO_AccessType" SG_ 1410 SensorR_OD_CAN2_ErrorStatus 1;
BA_ "CANzero_SDO_AccessIfOperational" SG_ 1410 SensorR_OD_CAN2_ErrorStatus 1;
BA_ "CANzero_SDO_Group" SG_ 1410 SensorR_OD_CAN2_DiscardedTxMessa "CAN";
BA_ "CANzero_SDO_AccessType" SG_ 1410 SensorR_OD_CAN2_DiscardedTxMessa 1;
BA_ "CANzero_SDO_AccessIfOperational" SG_ 1410 SensorR_OD_CAN2_DiscardedTxMessa 1;
BA_ "SystemSignalLongSymbol" SG_ 1410 SensorR_OD_CAN2_DiscardedTxMessa "SensorR_OD_CAN2_DiscardedTxMessages";
BA_ "CANzero_SDO_Group" SG_ 1410 SensorR_OD_CAN2_Status "CAN";
BA_ "CANzero_SDO_AccessType" SG_ 1410 SensorR_OD_CAN2_Status 1;
BA_ "CANzero_SDO_AccessIfOperational" SG_ 1410 SensorR_OD_CAN2_Status 1;
BA_ "CANzero_SDO_Group" SG_ 1410 SensorR_OD_CAN2_Baudrate "CAN";
BA_ "CANzero_SDO_AccessIfOperational" SG_ 1410 SensorR_OD_CAN2_Baudrate 1;
BA_ "GenSigStartValue" SG_ 1410 SensorR_OD_CAN2_Baudrate 1000.0;
BA_ "CANzero_SDO_Default" SG_ 1410 SensorR_OD_CAN2_Baudrate 1000;
BA_ "CANzero_SDO_Group" SG_ 1410 SensorR_OD_CAN2_autoErrorReset "CAN";
BA_ "CANzero_SDO_AccessIfOperational" SG_ 1410 SensorR_OD_CAN2_autoErrorReset 1;
BA_ "GenSigStartValue" SG_ 1410 SensorR_OD_CAN2_autoErrorReset 1.0;
BA_ "CANzero_SDO_Default" SG_ 1410 SensorR_OD_CAN2_autoErrorReset 1;
BA_ "CANzero_SDO_Group" SG_ 1410 SensorR_OD_CAN2_lastErrorCode "CAN";
BA_ "CANzero_SDO_AccessType" SG_ 1410 SensorR_OD_CAN2_lastErrorCode 1;
BA_ "CANzero_SDO_AccessIfOperational" SG_ 1410 SensorR_OD_CAN2_lastErrorCode 1;
BA_ "CANzero_SDO_Group" SG_ 1410 SensorR_OD_CAN2_RxErrCnt "CAN";
BA_ "CANzero_SDO_AccessType" SG_ 1410 SensorR_OD_CAN2_RxErrCnt 1;
BA_ "CANzero_SDO_AccessIfOperational" SG_ 1410 SensorR_OD_CAN2_RxErrCnt 1;
BA_ "CANzero_SDO_Group" SG_ 1410 SensorR_OD_CAN2_TxErrCnt "CAN";
BA_ "CANzero_SDO_AccessType" SG_ 1410 SensorR_OD_CAN2_TxErrCnt 1;
BA_ "CANzero_SDO_AccessIfOperational" SG_ 1410 SensorR_OD_CAN2_TxErrCnt 1;
BA_ "CANzero_SDO_Group" SG_ 1410 SensorR_OD_CAN1_DelayedTxMessage "CAN";
BA_ "CANzero_SDO_AccessType" SG_ 1410 SensorR_OD_CAN1_DelayedTxMessage 1;
BA_ "CANzero_SDO_AccessIfOperational" SG_ 1410 SensorR_OD_CAN1_DelayedTxMessage 1;
BA_ "SystemSignalLongSymbol" SG_ 1410 SensorR_OD_CAN1_DelayedTxMessage "SensorR_OD_CAN1_DelayedTxMessages";
BA_ "CANzero_SDO_Group" SG_ 1410 SensorR_OD_CAN1_ErrorStatus "CAN";
BA_ "CANzero_SDO_AccessType" SG_ 1410 SensorR_OD_CAN1_ErrorStatus 1;
BA_ "CANzero_SDO_AccessIfOperational" SG_ 1410 SensorR_OD_CAN1_ErrorStatus 1;
BA_ "CANzero_SDO_Group" SG_ 1410 SensorR_OD_CAN1_DiscardedTxMessa "CAN";
BA_ "CANzero_SDO_AccessType" SG_ 1410 SensorR_OD_CAN1_DiscardedTxMessa 1;
BA_ "CANzero_SDO_AccessIfOperational" SG_ 1410 SensorR_OD_CAN1_DiscardedTxMessa 1;
BA_ "SystemSignalLongSymbol" SG_ 1410 SensorR_OD_CAN1_DiscardedTxMessa "SensorR_OD_CAN1_DiscardedTxMessages";
BA_ "CANzero_SDO_Group" SG_ 1410 SensorR_OD_CAN1_Status "CAN";
BA_ "CANzero_SDO_AccessType" SG_ 1410 SensorR_OD_CAN1_Status 1;
BA_ "CANzero_SDO_AccessIfOperational" SG_ 1410 SensorR_OD_CAN1_Status 1;
BA_ "CANzero_SDO_Group" SG_ 1410 SensorR_OD_CAN1_Baudrate "CAN";
BA_ "CANzero_SDO_AccessIfOperational" SG_ 1410 SensorR_OD_CAN1_Baudrate 1;
BA_ "GenSigStartValue" SG_ 1410 SensorR_OD_CAN1_Baudrate 1000.0;
BA_ "CANzero_SDO_Default" SG_ 1410 SensorR_OD_CAN1_Baudrate 1000;
BA_ "CANzero_SDO_Group" SG_ 1410 SensorR_OD_CAN1_autoErrorReset "CAN";
BA_ "CANzero_SDO_AccessIfOperational" SG_ 1410 SensorR_OD_CAN1_autoErrorReset 1;
BA_ "GenSigStartValue" SG_ 1410 SensorR_OD_CAN1_autoErrorReset 1.0;
BA_ "CANzero_SDO_Default" SG_ 1410 SensorR_OD_CAN1_autoErrorReset 1;
BA_ "CANzero_SDO_Group" SG_ 1410 SensorR_OD_CAN1_lastErrorCode "CAN";
BA_ "CANzero_SDO_AccessType" SG_ 1410 SensorR_OD_CAN1_lastErrorCode 1;
BA_ "CANzero_SDO_AccessIfOperational" SG_ 1410 SensorR_OD_CAN1_lastErrorCode 1;
BA_ "CANzero_SDO_Group" SG_ 1410 SensorR_OD_CAN1_RxErrCnt "CAN";
BA_ "CANzero_SDO_AccessType" SG_ 1410 SensorR_OD_CAN1_RxErrCnt 1;
BA_ "CANzero_SDO_AccessIfOperational" SG_ 1410 SensorR_OD_CAN1_RxErrCnt 1;
BA_ "CANzero_SDO_Group" SG_ 1410 SensorR_OD_CAN1_TxErrCnt "CAN";
BA_ "CANzero_SDO_AccessType" SG_ 1410 SensorR_OD_CAN1_TxErrCnt 1;
BA_ "CANzero_SDO_AccessIfOperational" SG_ 1410 SensorR_OD_CAN1_TxErrCnt 1;
BA_ "CANzero_SDO_AccessType" SG_ 1410 SensorR_OD_BuildTime 1;
BA_ "CANzero_SDO_AccessIfOperational" SG_ 1410 SensorR_OD_BuildTime 1;
BA_ "CANzero_SDO_AccessType" SG_ 1410 SensorR_OD_BuildDate 1;
BA_ "CANzero_SDO_AccessIfOperational" SG_ 1410 SensorR_OD_BuildDate 1;
BA_ "CANzero_SDO_AccessType" SG_ 1410 SensorR_OD_ChipUID2 1;
BA_ "CANzero_SDO_AccessIfOperational" SG_ 1410 SensorR_OD_ChipUID2 1;
BA_ "CANzero_SDO_AccessType" SG_ 1410 SensorR_OD_ChipUID1 1;
BA_ "CANzero_SDO_AccessIfOperational" SG_ 1410 SensorR_OD_ChipUID1 1;
BA_ "CANzero_SDO_AccessType" SG_ 1410 SensorR_OD_SdcOut 1;
BA_ "CANzero_SDO_AccessIfOperational" SG_ 1410 SensorR_OD_SdcOut 1;
BA_ "CANzero_SDO_AccessType" SG_ 1410 SensorR_OD_SdcIn 1;
BA_ "CANzero_SDO_AccessIfOperational" SG_ 1410 SensorR_OD_SdcIn 1;
BA_ "CANzero_SDO_AccessType" SG_ 1410 SensorR_OD_runtime 1;
BA_ "CANzero_SDO_AccessIfOperational" SG_ 1410 SensorR_OD_runtime 1;
BA_ "CANzero_SDO_AccessType" SG_ 1410 SensorR_OD_InputVoltage 1;
BA_ "CANzero_SDO_AccessIfOperational" SG_ 1410 SensorR_OD_InputVoltage 1;
BA_ "CANzero_SDO_AccessType" SG_ 1410 SensorR_OD_BoardTemp 1;
BA_ "CANzero_SDO_AccessIfOperational" SG_ 1410 SensorR_OD_BoardTemp 1;
BA_ "GenSigStartValue" SG_ 1410 SensorR_OD_BoardTemp 3000.0;
BA_ "CANzero_SDO_AccessType" SG_ 1410 SensorR_OD_MemFree 1;
BA_ "CANzero_SDO_AccessIfOperational" SG_ 1410 SensorR_OD_MemFree 1;
BA_ "CANzero_SDO_AccessType" SG_ 1410 SensorR_OD_CpuUsage 1;
BA_ "CANzero_SDO_AccessIfOperational" SG_ 1410 SensorR_OD_CpuUsage 1;
BA_ "CANzero_SDO_AccessIfOperational" SG_ 1410 SensorR_OD_OdEntrySendInterval 1;
BA_ "GenSigStartValue" SG_ 1410 SensorR_OD_OdEntrySendInterval 50.0;
BA_ "CANzero_SDO_Default" SG_ 1410 SensorR_OD_OdEntrySendInterval 50;
BA_ "CANzero_SDO_AccessIfOperational" SG_ 1410 SensorR_OD_SendOdOnBootup 1;
BA_ "CANzero_SDO_AccessIfOperational" SG_ 1410 SensorR_OD_HeartbeatInterval 1;
BA_ "GenSigStartValue" SG_ 1410 SensorR_OD_HeartbeatInterval 250.0;
BA_ "CANzero_SDO_Default" SG_ 1410 SensorR_OD_HeartbeatInterval 250;
BA_ "CANzero_SDO_AccessType" SG_ 1410 SensorR_OD_DbcVersion 1;
BA_ "CANzero_SDO_AccessIfOperational" SG_ 1410 SensorR_OD_DbcVersion 1;
BA_ "CANzero_SDO_AccessType" SG_ 1410 SensorR_OD_StackVersion 1;
BA_ "CANzero_SDO_AccessIfOperational" SG_ 1410 SensorR_OD_StackVersion 1;
BA_ "CANzero_SDO_AccessType" SG_ 1410 SensorR_OD_ProtocolVersion 1;
BA_ "CANzero_SDO_AccessIfOperational" SG_ 1410 SensorR_OD_ProtocolVersion 1;
BA_ "GenSigStartValue" SG_ 1410 SensorR_OD_ProtocolVersion 1.0;
BA_ "CANzero_SDO_Default" SG_ 1410 SensorR_OD_ProtocolVersion 1;
BA_ "CANzero_SDO_AccessType" SG_ 1410 SensorR_OD_NodeStatus 1;
BA_ "CANzero_SDO_AccessIfOperational" SG_ 1410 SensorR_OD_NodeStatus 1;
BA_ "CANzero_SDO_AccessType" SG_ 1410 SensorR_OD_NodeID 1;
BA_ "CANzero_SDO_AccessIfOperational" SG_ 1410 SensorR_OD_NodeID 1;
BA_ "CANzero_SDO_AccessIfOperational" SG_ 1474 SensorR_OD_posDeviationOptic 1;
BA_ "GenSigStartValue" SG_ 1474 SensorR_OD_posDeviationOptic 40.0;
BA_ "CANzero_SDO_Default" SG_ 1474 SensorR_OD_posDeviationOptic 4;
BA_ "CANzero_SDO_AccessIfOperational" SG_ 1474 SensorR_OD_posDeviationEncoder 1;
BA_ "GenSigStartValue" SG_ 1474 SensorR_OD_posDeviationEncoder 40.0;
BA_ "CANzero_SDO_Default" SG_ 1474 SensorR_OD_posDeviationEncoder 4;
BA_ "CANzero_SDO_AccessIfOperational" SG_ 1474 SensorR_OD_velDeviationOptic 1;
BA_ "GenSigStartValue" SG_ 1474 SensorR_OD_velDeviationOptic 20.0;
BA_ "CANzero_SDO_Default" SG_ 1474 SensorR_OD_velDeviationOptic 2;
BA_ "CANzero_SDO_AccessIfOperational" SG_ 1474 SensorR_OD_velDeviationEncoder 1;
BA_ "GenSigStartValue" SG_ 1474 SensorR_OD_velDeviationEncoder 20.0;
BA_ "CANzero_SDO_Default" SG_ 1474 SensorR_OD_velDeviationEncoder 2;
BA_ "CANzero_SDO_AccessIfOperational" SG_ 1474 SensorR_OD_accDeviation 1;
BA_ "GenSigStartValue" SG_ 1474 SensorR_OD_accDeviation 40.0;
BA_ "CANzero_SDO_Default" SG_ 1474 SensorR_OD_accDeviation 4;
BA_ "CANzero_SDO_AccessIfOperational" SG_ 1474 SensorR_OD_EnableSignalGene_0000 1;
BA_ "SystemSignalLongSymbol" SG_ 1474 SensorR_OD_EnableSignalGene_0000 "SensorR_OD_EnableSignalGeneration";
BA_ "CANzero_SDO_AccessIfOperational" SG_ 1474 SensorR_OD_PositionGlitch 1;
BA_ "GenSigStartValue" SG_ 1474 SensorR_OD_PositionGlitch 50.0;
BA_ "CANzero_SDO_Default" SG_ 1474 SensorR_OD_PositionGlitch 5;
BA_ "CANzero_SDO_AccessIfOperational" SG_ 1474 SensorR_OD_ReflectorDistance 1;
BA_ "GenSigStartValue" SG_ 1474 SensorR_OD_ReflectorDistance 200.0;
BA_ "CANzero_SDO_Default" SG_ 1474 SensorR_OD_ReflectorDistance 20;
BA_ "CANzero_SDO_AccessIfOperational" SG_ 1474 SensorR_OD_StripeMode 1;
BA_ "GenSigStartValue" SG_ 1474 SensorR_OD_StripeMode 1.0;
BA_ "CANzero_SDO_Default" SG_ 1474 SensorR_OD_StripeMode 1;
BA_ "CANzero_SDO_AccessIfOperational" SG_ 1474 SensorR_OD_opc_lowpass_TcI 1;
BA_ "GenSigStartValue" SG_ 1474 SensorR_OD_opc_lowpass_TcI 2.0;
BA_ "CANzero_SDO_Default" SG_ 1474 SensorR_OD_opc_lowpass_TcI 0.02;
BA_ "CANzero_SDO_AccessIfOperational" SG_ 1474 SensorR_OD_opc_lowpass_Tcf 1;
BA_ "GenSigStartValue" SG_ 1474 SensorR_OD_opc_lowpass_Tcf 2.0;
BA_ "CANzero_SDO_Default" SG_ 1474 SensorR_OD_opc_lowpass_Tcf 0.02;
BA_ "CANzero_SDO_AccessIfOperational" SG_ 1474 SensorR_OD_opc_F_decrease 1;
BA_ "GenSigStartValue" SG_ 1474 SensorR_OD_opc_F_decrease 25.0;
BA_ "CANzero_SDO_Default" SG_ 1474 SensorR_OD_opc_F_decrease 0.25;
BA_ "CANzero_SDO_AccessIfOperational" SG_ 1474 SensorR_OD_opc_v_threshold 1;
BA_ "GenSigStartValue" SG_ 1474 SensorR_OD_opc_v_threshold 25.0;
BA_ "CANzero_SDO_Default" SG_ 1474 SensorR_OD_opc_v_threshold 0.25;
BA_ "CANzero_SDO_AccessIfOperational" SG_ 1474 SensorR_OD_opc_v_max 1;
BA_ "GenSigStartValue" SG_ 1474 SensorR_OD_opc_v_max 200.0;
BA_ "CANzero_SDO_Default" SG_ 1474 SensorR_OD_opc_v_max 2.0;
BA_ "CANzero_SDO_AccessIfOperational" SG_ 1474 SensorR_OD_opc_T_acc 1;
BA_ "GenSigStartValue" SG_ 1474 SensorR_OD_opc_T_acc 20.0;
BA_ "CANzero_SDO_Default" SG_ 1474 SensorR_OD_opc_T_acc 2.0;
BA_ "CANzero_SDO_AccessIfOperational" SG_ 1474 SensorR_OD_opc_F_max 1;
BA_ "GenSigStartValue" SG_ 1474 SensorR_OD_opc_F_max 90.0;
BA_ "CANzero_SDO_Default" SG_ 1474 SensorR_OD_opc_F_max 90;
BA_ "CANzero_SDO_AccessIfOperational" SG_ 1474 SensorR_OD_opc_t_run_max 1;
BA_ "GenSigStartValue" SG_ 1474 SensorR_OD_opc_t_run_max 40.0;
BA_ "CANzero_SDO_Default" SG_ 1474 SensorR_OD_opc_t_run_max 4.0;
BA_ "CANzero_SDO_AccessIfOperational" SG_ 1474 SensorR_OD_opc_brakeFlag 1;
BA_ "CANzero_SDO_AccessIfOperational" SG_ 1474 SensorR_OD_DebugCVOPCfreq 1;
BA_ "GenSigStartValue" SG_ 1474 SensorR_OD_DebugCVOPCfreq 32000.0;
BA_ "CANzero_SDO_AccessIfOperational" SG_ 1474 SensorR_OD_DebugCascadedIreq 1;
BA_ "GenSigStartValue" SG_ 1474 SensorR_OD_DebugCascadedIreq 32000.0;
BA_ "CANzero_SDO_AccessIfOperational" SG_ 1474 SensorR_OD_opc_ratelimiter_f 1;
BA_ "GenSigStartValue" SG_ 1474 SensorR_OD_opc_ratelimiter_f 37000.0;
BA_ "CANzero_SDO_Default" SG_ 1474 SensorR_OD_opc_ratelimiter_f 500;
BA_ "CANzero_SDO_AccessIfOperational" SG_ 1474 SensorR_OD_maxRunDistance 1;
BA_ "GenSigStartValue" SG_ 1474 SensorR_OD_maxRunDistance 38000.0;
BA_ "CANzero_SDO_Default" SG_ 1474 SensorR_OD_maxRunDistance 300;
BA_ "CANzero_SDO_AccessIfOperational" SG_ 1474 SensorR_OD_FinishedDelay 1;
BA_ "GenSigStartValue" SG_ 1474 SensorR_OD_FinishedDelay 2500.0;
BA_ "CANzero_SDO_Default" SG_ 1474 SensorR_OD_FinishedDelay 2500;
BA_ "CANzero_SDO_AccessIfOperational" SG_ 1474 SensorR_OD_Current4Stopping 1;
BA_ "GenSigStartValue" SG_ 1474 SensorR_OD_Current4Stopping 500.0;
BA_ "CANzero_SDO_Default" SG_ 1474 SensorR_OD_Current4Stopping 50.0;
BA_ "CANzero_SDO_AccessIfOperational" SG_ 1474 SensorR_OD_AdaptModelByCurrent 1;
BA_ "CANzero_SDO_AccessIfOperational" SG_ 1474 SensorR_OD_CVOPCTcFreq 1;
BA_ "GenSigStartValue" SG_ 1474 SensorR_OD_CVOPCTcFreq 100.0;
BA_ "CANzero_SDO_Default" SG_ 1474 SensorR_OD_CVOPCTcFreq 100;
BA_ "CANzero_SDO_AccessIfOperational" SG_ 1474 SensorR_OD_CVOPCImin 1;
BA_ "GenSigStartValue" SG_ 1474 SensorR_OD_CVOPCImin 50.0;
BA_ "CANzero_SDO_Default" SG_ 1474 SensorR_OD_CVOPCImin 50;
BA_ "CANzero_SDO_AccessIfOperational" SG_ 1474 SensorR_OD_CascadedKpDecrea_0000 1;
BA_ "GenSigStartValue" SG_ 1474 SensorR_OD_CascadedKpDecrea_0000 400.0;
BA_ "CANzero_SDO_Default" SG_ 1474 SensorR_OD_CascadedKpDecrea_0000 40.0;
BA_ "SystemSignalLongSymbol" SG_ 1474 SensorR_OD_CascadedKpDecrea_0000 "SensorR_OD_CascadedKpDecreaseCurrent";
BA_ "CANzero_SDO_AccessIfOperational" SG_ 1474 SensorR_OD_CascadedKpIncrea_0000 1;
BA_ "GenSigStartValue" SG_ 1474 SensorR_OD_CascadedKpIncrea_0000 400.0;
BA_ "CANzero_SDO_Default" SG_ 1474 SensorR_OD_CascadedKpIncrea_0000 40.0;
BA_ "SystemSignalLongSymbol" SG_ 1474 SensorR_OD_CascadedKpIncrea_0000 "SensorR_OD_CascadedKpIncreaseCurrent";
BA_ "CANzero_SDO_AccessIfOperational" SG_ 1474 SensorR_OD_CascadedFreqCurUpdate 1;
BA_ "GenSigStartValue" SG_ 1474 SensorR_OD_CascadedFreqCurUpdate 100.0;
BA_ "CANzero_SDO_Default" SG_ 1474 SensorR_OD_CascadedFreqCurUpdate 0.1;
BA_ "CANzero_SDO_AccessIfOperational" SG_ 1474 SensorR_OD_CascadedMaxSetFo_0000 1;
BA_ "GenSigStartValue" SG_ 1474 SensorR_OD_CascadedMaxSetFo_0000 1000.0;
BA_ "CANzero_SDO_Default" SG_ 1474 SensorR_OD_CascadedMaxSetFo_0000 100;
BA_ "SystemSignalLongSymbol" SG_ 1474 SensorR_OD_CascadedMaxSetFo_0000 "SensorR_OD_CascadedMaxSetForceDelta";
BA_ "CANzero_SDO_AccessIfOperational" SG_ 1474 SensorR_OD_CurrentForConsta_0000 1;
BA_ "GenSigStartValue" SG_ 1474 SensorR_OD_CurrentForConsta_0000 8000.0;
BA_ "CANzero_SDO_Default" SG_ 1474 SensorR_OD_CurrentForConsta_0000 80.0;
BA_ "SystemSignalLongSymbol" SG_ 1474 SensorR_OD_CurrentForConsta_0000 "SensorR_OD_CurrentForConstantVelocity";
BA_ "CANzero_SDO_AccessIfOperational" SG_ 1474 SensorR_OD_AccAtCurrentMeasured 1;
BA_ "GenSigStartValue" SG_ 1474 SensorR_OD_AccAtCurrentMeasured 7700.0;
BA_ "CANzero_SDO_Default" SG_ 1474 SensorR_OD_AccAtCurrentMeasured 77.0;
BA_ "CANzero_SDO_AccessIfOperational" SG_ 1474 SensorR_OD_CVOPCHystereseF 1;
BA_ "GenSigStartValue" SG_ 1474 SensorR_OD_CVOPCHystereseF 4000.0;
BA_ "CANzero_SDO_Default" SG_ 1474 SensorR_OD_CVOPCHystereseF 400;
BA_ "CANzero_SDO_AccessIfOperational" SG_ 1474 SensorR_OD_CVOPCReduceCurre_0000 1;
BA_ "GenSigStartValue" SG_ 1474 SensorR_OD_CVOPCReduceCurre_0000 90.0;
BA_ "CANzero_SDO_Default" SG_ 1474 SensorR_OD_CVOPCReduceCurre_0000 0.9;
BA_ "SystemSignalLongSymbol" SG_ 1474 SensorR_OD_CVOPCReduceCurre_0000 "SensorR_OD_CVOPCReduceCurrentWhileCruising";
BA_ "CANzero_SDO_AccessIfOperational" SG_ 1474 SensorR_OD_CVOPCDeltaVelHig_0000 1;
BA_ "GenSigStartValue" SG_ 1474 SensorR_OD_CVOPCDeltaVelHig_0000 30.0;
BA_ "CANzero_SDO_Default" SG_ 1474 SensorR_OD_CVOPCDeltaVelHig_0000 0.3;
BA_ "SystemSignalLongSymbol" SG_ 1474 SensorR_OD_CVOPCDeltaVelHig_0000 "SensorR_OD_CVOPCDeltaVelHigherCurrent";
BA_ "CANzero_SDO_AccessIfOperational" SG_ 1474 SensorR_OD_CVOPCSmoothingDe_0000 1;
BA_ "GenSigStartValue" SG_ 1474 SensorR_OD_CVOPCSmoothingDe_0000 5.0;
BA_ "CANzero_SDO_Default" SG_ 1474 SensorR_OD_CVOPCSmoothingDe_0000 0.05;
BA_ "SystemSignalLongSymbol" SG_ 1474 SensorR_OD_CVOPCSmoothingDe_0000 "SensorR_OD_CVOPCSmoothingDeltaVelocity";
BA_ "CANzero_SDO_AccessIfOperational" SG_ 1474 SensorR_OD_CVOPCTcI 1;
BA_ "GenSigStartValue" SG_ 1474 SensorR_OD_CVOPCTcI 300.0;
BA_ "CANzero_SDO_Default" SG_ 1474 SensorR_OD_CVOPCTcI 300;
BA_ "CANzero_SDO_AccessIfOperational" SG_ 1474 SensorR_OD_CVOPCTcf 1;
BA_ "GenSigStartValue" SG_ 1474 SensorR_OD_CVOPCTcf 1000.0;
BA_ "CANzero_SDO_Default" SG_ 1474 SensorR_OD_CVOPCTcf 1000;
BA_ "CANzero_SDO_AccessIfOperational" SG_ 1474 SensorR_OD_CVOPCImax 1;
BA_ "GenSigStartValue" SG_ 1474 SensorR_OD_CVOPCImax 200.0;
BA_ "CANzero_SDO_Default" SG_ 1474 SensorR_OD_CVOPCImax 200;
BA_ "CANzero_SDO_AccessIfOperational" SG_ 1474 SensorR_OD_VelocityController 1;
BA_ "CANzero_SDO_AccessIfOperational" SG_ 1474 SensorR_OD_TC_f 1;
BA_ "GenSigStartValue" SG_ 1474 SensorR_OD_TC_f 150.0;
BA_ "CANzero_SDO_Default" SG_ 1474 SensorR_OD_TC_f 150;
BA_ "CANzero_SDO_AccessIfOperational" SG_ 1474 SensorR_OD_TC_I 1;
BA_ "GenSigStartValue" SG_ 1474 SensorR_OD_TC_I 150.0;
BA_ "CANzero_SDO_Default" SG_ 1474 SensorR_OD_TC_I 150;
BA_ "CANzero_SDO_AccessType" SG_ 1474 SensorR_OD_EstimatedRunLength 1;
BA_ "CANzero_SDO_AccessIfOperational" SG_ 1474 SensorR_OD_EstimatedRunLength 1;
BA_ "GenSigStartValue" SG_ 1474 SensorR_OD_EstimatedRunLength 32000.0;
BA_ "CANzero_SDO_AccessIfOperational" SG_ 1474 SensorR_OD_RunProfile_V4 1;
BA_ "GenSigStartValue" SG_ 1474 SensorR_OD_RunProfile_V4 32700.0;
BA_ "CANzero_SDO_AccessIfOperational" SG_ 1474 SensorR_OD_RunProfile_T4 1;
BA_ "GenSigStartValue" SG_ 1474 SensorR_OD_RunProfile_T4 450.0;
BA_ "CANzero_SDO_Default" SG_ 1474 SensorR_OD_RunProfile_T4 4500;
BA_ "CANzero_SDO_AccessIfOperational" SG_ 1474 SensorR_OD_RunProfile_V3 1;
BA_ "GenSigStartValue" SG_ 1474 SensorR_OD_RunProfile_V3 32800.0;
BA_ "CANzero_SDO_Default" SG_ 1474 SensorR_OD_RunProfile_V3 1;
BA_ "CANzero_SDO_AccessIfOperational" SG_ 1474 SensorR_OD_RunProfile_T3 1;
BA_ "GenSigStartValue" SG_ 1474 SensorR_OD_RunProfile_T3 350.0;
BA_ "CANzero_SDO_Default" SG_ 1474 SensorR_OD_RunProfile_T3 3500;
BA_ "CANzero_SDO_AccessIfOperational" SG_ 1474 SensorR_OD_RunProfile_V2 1;
BA_ "GenSigStartValue" SG_ 1474 SensorR_OD_RunProfile_V2 32800.0;
BA_ "CANzero_SDO_Default" SG_ 1474 SensorR_OD_RunProfile_V2 1;
BA_ "CANzero_SDO_AccessIfOperational" SG_ 1474 SensorR_OD_RunProfile_T2 1;
BA_ "GenSigStartValue" SG_ 1474 SensorR_OD_RunProfile_T2 300.0;
BA_ "CANzero_SDO_Default" SG_ 1474 SensorR_OD_RunProfile_T2 3000;
BA_ "CANzero_SDO_AccessIfOperational" SG_ 1474 SensorR_OD_RunProfile_V1 1;
BA_ "GenSigStartValue" SG_ 1474 SensorR_OD_RunProfile_V1 32705.0;
BA_ "CANzero_SDO_Default" SG_ 1474 SensorR_OD_RunProfile_V1 0.05;
BA_ "CANzero_SDO_AccessIfOperational" SG_ 1474 SensorR_OD_RunProfile_T1 1;
BA_ "GenSigStartValue" SG_ 1474 SensorR_OD_RunProfile_T1 100.0;
BA_ "CANzero_SDO_Default" SG_ 1474 SensorR_OD_RunProfile_T1 1000;
BA_ "CANzero_SDO_AccessIfOperational" SG_ 1474 SensorR_OD_RunProfile_V0 1;
BA_ "GenSigStartValue" SG_ 1474 SensorR_OD_RunProfile_V0 32700.0;
BA_ "CANzero_SDO_AccessIfOperational" SG_ 1474 SensorR_OD_RunProfile_T0 1;
BA_ "CANzero_SDO_AccessIfOperational" SG_ 1474 SensorR_OD_SetFinish 1;
BA_ "CANzero_SDO_AccessIfOperational" SG_ 1474 SensorR_OD_RunMode 1;
BA_ "CANzero_SDO_AccessIfOperational" SG_ 1474 SensorR_OD_VdcReduceFactor 1;
BA_ "GenSigStartValue" SG_ 1474 SensorR_OD_VdcReduceFactor 9.499999999999998;
BA_ "CANzero_SDO_Default" SG_ 1474 SensorR_OD_VdcReduceFactor 0.95;
BA_ "CANzero_SDO_AccessIfOperational" SG_ 1474 SensorR_OD_MaxRequiredVelocity 1;
BA_ "GenSigStartValue" SG_ 1474 SensorR_OD_MaxRequiredVelocity 190.0;
BA_ "CANzero_SDO_Default" SG_ 1474 SensorR_OD_MaxRequiredVelocity 19;
BA_ "CANzero_SDO_AccessIfOperational" SG_ 1474 SensorR_OD_WarningThreshhol_0000 1;
BA_ "GenSigStartValue" SG_ 1474 SensorR_OD_WarningThreshhol_0000 900.0;
BA_ "CANzero_SDO_Default" SG_ 1474 SensorR_OD_WarningThreshhol_0000 0.9;
BA_ "SystemSignalLongSymbol" SG_ 1474 SensorR_OD_WarningThreshhol_0000 "SensorR_OD_WarningThreshholdForLimModelOutOfBoundaries";
BA_ "CANzero_SDO_AccessIfOperational" SG_ 1474 SensorR_OD_MaxCtrlErrorDuration 1;
BA_ "GenSigStartValue" SG_ 1474 SensorR_OD_MaxCtrlErrorDuration 50.0;
BA_ "CANzero_SDO_Default" SG_ 1474 SensorR_OD_MaxCtrlErrorDuration 0.5;
BA_ "CANzero_SDO_AccessIfOperational" SG_ 1474 SensorR_OD_MaxCtrlError 1;
BA_ "GenSigStartValue" SG_ 1474 SensorR_OD_MaxCtrlError 150.0;
BA_ "CANzero_SDO_Default" SG_ 1474 SensorR_OD_MaxCtrlError 1.5;
BA_ "CANzero_SDO_AccessIfOperational" SG_ 1474 SensorR_OD_FminCtrl 1;
BA_ "GenSigStartValue" SG_ 1474 SensorR_OD_FminCtrl 922.0;
BA_ "CANzero_SDO_Default" SG_ 1474 SensorR_OD_FminCtrl 922;
BA_ "CANzero_SDO_AccessIfOperational" SG_ 1474 SensorR_OD_FmaxCtrl 1;
BA_ "GenSigStartValue" SG_ 1474 SensorR_OD_FmaxCtrl 1004.0;
BA_ "CANzero_SDO_Default" SG_ 1474 SensorR_OD_FmaxCtrl 1004;
BA_ "CANzero_SDO_AccessIfOperational" SG_ 1474 SensorR_OD_PodMass 1;
BA_ "GenSigStartValue" SG_ 1474 SensorR_OD_PodMass 2300.0;
BA_ "CANzero_SDO_Default" SG_ 1474 SensorR_OD_PodMass 230.0;
BA_ "CANzero_SDO_AccessIfOperational" SG_ 1474 SensorR_OD_CurrentReq 1;
BA_ "GenSigStartValue" SG_ 1474 SensorR_OD_CurrentReq 1050.0;
BA_ "CANzero_SDO_Default" SG_ 1474 SensorR_OD_CurrentReq 105.0;
BA_ "CANzero_SDO_AccessIfOperational" SG_ 1474 SensorR_OD_CtrlMode 1;
BA_ "GenSigStartValue" SG_ 1474 SensorR_OD_CtrlMode 1.0;
BA_ "CANzero_SDO_Default" SG_ 1474 SensorR_OD_CtrlMode 1;
BA_ "CANzero_SDO_AccessIfOperational" SG_ 1474 SensorR_OD_OpcKi 1;
BA_ "GenSigStartValue" SG_ 1474 SensorR_OD_OpcKi 50.0;
BA_ "CANzero_SDO_Default" SG_ 1474 SensorR_OD_OpcKi 0.5;
BA_ "CANzero_SDO_AccessIfOperational" SG_ 1474 SensorR_OD_OpcKp 1;
BA_ "GenSigStartValue" SG_ 1474 SensorR_OD_OpcKp 600.0;
BA_ "CANzero_SDO_Default" SG_ 1474 SensorR_OD_OpcKp 6.0;
BA_ "CANzero_SDO_AccessIfOperational" SG_ 1474 SensorR_OD_ExecTimeReadSensors 1;
BA_ "CANzero_SDO_AccessIfOperational" SG_ 1474 SensorR_OD_ExecTimeControl 1;
BA_ "CANzero_SDO_AccessIfOperational" SG_ 1474 SensorR_OD_ExecTimeStateEst 1;
BA_ "CANzero_SDO_AccessIfOperational" SG_ 1474 SensorR_OD_ExecTimeOverall 1;
BA_ "CANzero_SDO_AccessType" SG_ 1474 SensorR_OD_IMU3_Temperature 1;
BA_ "CANzero_SDO_AccessIfOperational" SG_ 1474 SensorR_OD_IMU3_Temperature 1;
BA_ "GenSigStartValue" SG_ 1474 SensorR_OD_IMU3_Temperature 10000.0;
BA_ "CANzero_SDO_AccessType" SG_ 1474 SensorR_OD_IMU2_Temperature 1;
BA_ "CANzero_SDO_AccessIfOperational" SG_ 1474 SensorR_OD_IMU2_Temperature 1;
BA_ "GenSigStartValue" SG_ 1474 SensorR_OD_IMU2_Temperature 10000.0;
BA_ "CANzero_SDO_AccessType" SG_ 1474 SensorR_OD_IMU1_Temperature 1;
BA_ "CANzero_SDO_AccessIfOperational" SG_ 1474 SensorR_OD_IMU1_Temperature 1;
BA_ "GenSigStartValue" SG_ 1474 SensorR_OD_IMU1_Temperature 10000.0;
BA_ "CANzero_SDO_AccessType" SG_ 1474 SensorR_OD_IMU_number 1;
BA_ "CANzero_SDO_AccessIfOperational" SG_ 1474 SensorR_OD_IMU_number 1;
BA_ "CANzero_SDO_AccessType" SG_ 1474 SensorR_OD_EncoderResetPosition 2;
BA_ "CANzero_SDO_AccessIfOperational" SG_ 1474 SensorR_OD_EncoderResetPosition 1;
BA_ "CANzero_SDO_AccessIfOperational" SG_ 1474 SensorR_OD_EncoderWheelDiameter 1;
BA_ "GenSigStartValue" SG_ 1474 SensorR_OD_EncoderWheelDiameter 15000.0;
BA_ "CANzero_SDO_Default" SG_ 1474 SensorR_OD_EncoderWheelDiameter 75;
BA_ "CANzero_SDO_AccessIfOperational" SG_ 1474 SensorR_OD_samplingInterval 1;
BA_ "GenSigStartValue" SG_ 1474 SensorR_OD_samplingInterval 1000.0;
BA_ "CANzero_SDO_Default" SG_ 1474 SensorR_OD_samplingInterval 10;
BA_ "CANzero_SDO_Group" SG_ 1474 SensorR_OD_CAN2_DelayedTxMe_0000 "CAN";
BA_ "CANzero_SDO_AccessType" SG_ 1474 SensorR_OD_CAN2_DelayedTxMe_0000 1;
BA_ "CANzero_SDO_AccessIfOperational" SG_ 1474 SensorR_OD_CAN2_DelayedTxMe_0000 1;
BA_ "SystemSignalLongSymbol" SG_ 1474 SensorR_OD_CAN2_DelayedTxMe_0000 "SensorR_OD_CAN2_DelayedTxMessages";
BA_ "CANzero_SDO_Group" SG_ 1474 SensorR_OD_CAN2_ErrorStatus "CAN";
BA_ "CANzero_SDO_AccessType" SG_ 1474 SensorR_OD_CAN2_ErrorStatus 1;
BA_ "CANzero_SDO_AccessIfOperational" SG_ 1474 SensorR_OD_CAN2_ErrorStatus 1;
BA_ "CANzero_SDO_Group" SG_ 1474 SensorR_OD_CAN2_DiscardedTx_0000 "CAN";
BA_ "CANzero_SDO_AccessType" SG_ 1474 SensorR_OD_CAN2_DiscardedTx_0000 1;
BA_ "CANzero_SDO_AccessIfOperational" SG_ 1474 SensorR_OD_CAN2_DiscardedTx_0000 1;
BA_ "SystemSignalLongSymbol" SG_ 1474 SensorR_OD_CAN2_DiscardedTx_0000 "SensorR_OD_CAN2_DiscardedTxMessages";
BA_ "CANzero_SDO_Group" SG_ 1474 SensorR_OD_CAN2_Status "CAN";
BA_ "CANzero_SDO_AccessType" SG_ 1474 SensorR_OD_CAN2_Status 1;
BA_ "CANzero_SDO_AccessIfOperational" SG_ 1474 SensorR_OD_CAN2_Status 1;
BA_ "CANzero_SDO_Group" SG_ 1474 SensorR_OD_CAN2_Baudrate "CAN";
BA_ "CANzero_SDO_AccessIfOperational" SG_ 1474 SensorR_OD_CAN2_Baudrate 1;
BA_ "GenSigStartValue" SG_ 1474 SensorR_OD_CAN2_Baudrate 1000.0;
BA_ "CANzero_SDO_Default" SG_ 1474 SensorR_OD_CAN2_Baudrate 1000;
BA_ "CANzero_SDO_Group" SG_ 1474 SensorR_OD_CAN2_autoErrorReset "CAN";
BA_ "CANzero_SDO_AccessIfOperational" SG_ 1474 SensorR_OD_CAN2_autoErrorReset 1;
BA_ "GenSigStartValue" SG_ 1474 SensorR_OD_CAN2_autoErrorReset 1.0;
BA_ "CANzero_SDO_Default" SG_ 1474 SensorR_OD_CAN2_autoErrorReset 1;
BA_ "CANzero_SDO_Group" SG_ 1474 SensorR_OD_CAN2_lastErrorCode "CAN";
BA_ "CANzero_SDO_AccessType" SG_ 1474 SensorR_OD_CAN2_lastErrorCode 1;
BA_ "CANzero_SDO_AccessIfOperational" SG_ 1474 SensorR_OD_CAN2_lastErrorCode 1;
BA_ "CANzero_SDO_Group" SG_ 1474 SensorR_OD_CAN2_RxErrCnt "CAN";
BA_ "CANzero_SDO_AccessType" SG_ 1474 SensorR_OD_CAN2_RxErrCnt 1;
BA_ "CANzero_SDO_AccessIfOperational" SG_ 1474 SensorR_OD_CAN2_RxErrCnt 1;
BA_ "CANzero_SDO_Group" SG_ 1474 SensorR_OD_CAN2_TxErrCnt "CAN";
BA_ "CANzero_SDO_AccessType" SG_ 1474 SensorR_OD_CAN2_TxErrCnt 1;
BA_ "CANzero_SDO_AccessIfOperational" SG_ 1474 SensorR_OD_CAN2_TxErrCnt 1;
BA_ "CANzero_SDO_Group" SG_ 1474 SensorR_OD_CAN1_DelayedTxMe_0000 "CAN";
BA_ "CANzero_SDO_AccessType" SG_ 1474 SensorR_OD_CAN1_DelayedTxMe_0000 1;
BA_ "CANzero_SDO_AccessIfOperational" SG_ 1474 SensorR_OD_CAN1_DelayedTxMe_0000 1;
BA_ "SystemSignalLongSymbol" SG_ 1474 SensorR_OD_CAN1_DelayedTxMe_0000 "SensorR_OD_CAN1_DelayedTxMessages";
BA_ "CANzero_SDO_Group" SG_ 1474 SensorR_OD_CAN1_ErrorStatus "CAN";
BA_ "CANzero_SDO_AccessType" SG_ 1474 SensorR_OD_CAN1_ErrorStatus 1;
BA_ "CANzero_SDO_AccessIfOperational" SG_ 1474 SensorR_OD_CAN1_ErrorStatus 1;
BA_ "CANzero_SDO_Group" SG_ 1474 SensorR_OD_CAN1_DiscardedTx_0000 "CAN";
BA_ "CANzero_SDO_AccessType" SG_ 1474 SensorR_OD_CAN1_DiscardedTx_0000 1;
BA_ "CANzero_SDO_AccessIfOperational" SG_ 1474 SensorR_OD_CAN1_DiscardedTx_0000 1;
BA_ "SystemSignalLongSymbol" SG_ 1474 SensorR_OD_CAN1_DiscardedTx_0000 "SensorR_OD_CAN1_DiscardedTxMessages";
BA_ "CANzero_SDO_Group" SG_ 1474 SensorR_OD_CAN1_Status "CAN";
BA_ "CANzero_SDO_AccessType" SG_ 1474 SensorR_OD_CAN1_Status 1;
BA_ "CANzero_SDO_AccessIfOperational" SG_ 1474 SensorR_OD_CAN1_Status 1;
BA_ "CANzero_SDO_Group" SG_ 1474 SensorR_OD_CAN1_Baudrate "CAN";
BA_ "CANzero_SDO_AccessIfOperational" SG_ 1474 SensorR_OD_CAN1_Baudrate 1;
BA_ "GenSigStartValue" SG_ 1474 SensorR_OD_CAN1_Baudrate 1000.0;
BA_ "CANzero_SDO_Default" SG_ 1474 SensorR_OD_CAN1_Baudrate 1000;
BA_ "CANzero_SDO_Group" SG_ 1474 SensorR_OD_CAN1_autoErrorReset "CAN";
BA_ "CANzero_SDO_AccessIfOperational" SG_ 1474 SensorR_OD_CAN1_autoErrorReset 1;
BA_ "GenSigStartValue" SG_ 1474 SensorR_OD_CAN1_autoErrorReset 1.0;
BA_ "CANzero_SDO_Default" SG_ 1474 SensorR_OD_CAN1_autoErrorReset 1;
BA_ "CANzero_SDO_Group" SG_ 1474 SensorR_OD_CAN1_lastErrorCode "CAN";
BA_ "CANzero_SDO_AccessType" SG_ 1474 SensorR_OD_CAN1_lastErrorCode 1;
BA_ "CANzero_SDO_AccessIfOperational" SG_ 1474 SensorR_OD_CAN1_lastErrorCode 1;
BA_ "CANzero_SDO_Group" SG_ 1474 SensorR_OD_CAN1_RxErrCnt "CAN";
BA_ "CANzero_SDO_AccessType" SG_ 1474 SensorR_OD_CAN1_RxErrCnt 1;
BA_ "CANzero_SDO_AccessIfOperational" SG_ 1474 SensorR_OD_CAN1_RxErrCnt 1;
BA_ "CANzero_SDO_Group" SG_ 1474 SensorR_OD_CAN1_TxErrCnt "CAN";
BA_ "CANzero_SDO_AccessType" SG_ 1474 SensorR_OD_CAN1_TxErrCnt 1;
BA_ "CANzero_SDO_AccessIfOperational" SG_ 1474 SensorR_OD_CAN1_TxErrCnt 1;
BA_ "CANzero_SDO_AccessType" SG_ 1474 SensorR_OD_BuildTime 1;
BA_ "CANzero_SDO_AccessIfOperational" SG_ 1474 SensorR_OD_BuildTime 1;
BA_ "CANzero_SDO_AccessType" SG_ 1474 SensorR_OD_BuildDate 1;
BA_ "CANzero_SDO_AccessIfOperational" SG_ 1474 SensorR_OD_BuildDate 1;
BA_ "CANzero_SDO_AccessType" SG_ 1474 SensorR_OD_ChipUID2 1;
BA_ "CANzero_SDO_AccessIfOperational" SG_ 1474 SensorR_OD_ChipUID2 1;
BA_ "CANzero_SDO_AccessType" SG_ 1474 SensorR_OD_ChipUID1 1;
BA_ "CANzero_SDO_AccessIfOperational" SG_ 1474 SensorR_OD_ChipUID1 1;
BA_ "CANzero_SDO_AccessType" SG_ 1474 SensorR_OD_SdcOut 1;
BA_ "CANzero_SDO_AccessIfOperational" SG_ 1474 SensorR_OD_SdcOut 1;
BA_ "CANzero_SDO_AccessType" SG_ 1474 SensorR_OD_SdcIn 1;
BA_ "CANzero_SDO_AccessIfOperational" SG_ 1474 SensorR_OD_SdcIn 1;
BA_ "CANzero_SDO_AccessType" SG_ 1474 SensorR_OD_runtime 1;
BA_ "CANzero_SDO_AccessIfOperational" SG_ 1474 SensorR_OD_runtime 1;
BA_ "CANzero_SDO_AccessType" SG_ 1474 SensorR_OD_InputVoltage 1;
BA_ "CANzero_SDO_AccessIfOperational" SG_ 1474 SensorR_OD_InputVoltage 1;
BA_ "CANzero_SDO_AccessType" SG_ 1474 SensorR_OD_BoardTemp 1;
BA_ "CANzero_SDO_AccessIfOperational" SG_ 1474 SensorR_OD_BoardTemp 1;
BA_ "GenSigStartValue" SG_ 1474 SensorR_OD_BoardTemp 3000.0;
BA_ "CANzero_SDO_AccessType" SG_ 1474 SensorR_OD_MemFree 1;
BA_ "CANzero_SDO_AccessIfOperational" SG_ 1474 SensorR_OD_MemFree 1;
BA_ "CANzero_SDO_AccessType" SG_ 1474 SensorR_OD_CpuUsage 1;
BA_ "CANzero_SDO_AccessIfOperational" SG_ 1474 SensorR_OD_CpuUsage 1;
BA_ "CANzero_SDO_AccessIfOperational" SG_ 1474 SensorR_OD_OdEntrySendInterval 1;
BA_ "GenSigStartValue" SG_ 1474 SensorR_OD_OdEntrySendInterval 50.0;
BA_ "CANzero_SDO_Default" SG_ 1474 SensorR_OD_OdEntrySendInterval 50;
BA_ "CANzero_SDO_AccessIfOperational" SG_ 1474 SensorR_OD_SendOdOnBootup 1;
BA_ "CANzero_SDO_AccessIfOperational" SG_ 1474 SensorR_OD_HeartbeatInterval 1;
BA_ "GenSigStartValue" SG_ 1474 SensorR_OD_HeartbeatInterval 250.0;
BA_ "CANzero_SDO_Default" SG_ 1474 SensorR_OD_HeartbeatInterval 250;
BA_ "CANzero_SDO_AccessType" SG_ 1474 SensorR_OD_DbcVersion 1;
BA_ "CANzero_SDO_AccessIfOperational" SG_ 1474 SensorR_OD_DbcVersion 1;
BA_ "CANzero_SDO_AccessType" SG_ 1474 SensorR_OD_StackVersion 1;
BA_ "CANzero_SDO_AccessIfOperational" SG_ 1474 SensorR_OD_StackVersion 1;
BA_ "CANzero_SDO_AccessType" SG_ 1474 SensorR_OD_ProtocolVersion 1;
BA_ "CANzero_SDO_AccessIfOperational" SG_ 1474 SensorR_OD_ProtocolVersion 1;
BA_ "GenSigStartValue" SG_ 1474 SensorR_OD_ProtocolVersion 1.0;
BA_ "CANzero_SDO_Default" SG_ 1474 SensorR_OD_ProtocolVersion 1;
BA_ "CANzero_SDO_AccessType" SG_ 1474 SensorR_OD_NodeStatus 1;
BA_ "CANzero_SDO_AccessIfOperational" SG_ 1474 SensorR_OD_NodeStatus 1;
BA_ "CANzero_SDO_AccessType" SG_ 1474 SensorR_OD_NodeID 1;
BA_ "CANzero_SDO_AccessIfOperational" SG_ 1474 SensorR_OD_NodeID 1;
BA_ "SystemSignalLongSymbol" SG_ 145 BrakeF_E5_retractUnsuccesful_ope "BrakeF_E5_retractUnsuccesful_openSDC";
BA_ "SystemSignalLongSymbol" SG_ 145 BrakeF_E4_retractUnsuccesful_not "BrakeF_E4_retractUnsuccesful_notEnabled";
BA_ "SystemSignalLongSymbol" SG_ 145 BrakeF_E3_retractUnsuccesful_err "BrakeF_E3_retractUnsuccesful_errorFlag";
BA_ "SystemSignalLongSymbol" SG_ 145 BrakeF_W1_highPressureRetracting "BrakeF_W1_highPressureRetractingChamber";
BA_ "SystemSignalLongSymbol" SG_ 145 BrakeF_W0_highPressureActingCham "BrakeF_W0_highPressureActingChamber";
VAL_ 2684354556 OpticalSensor_TX_LEDStatus 2 "FLASHING" 1 "ON" 0 "OFF" ;
VAL_ 2 CANzero_NMT_Node 0 "All" 1 "SensorF" 2 "SensorR" 17 "BrakeF" 18 "BrakeR" 26 "PDU" 10 "HVCU" 25 "HVTU" 34 "TelemetryNode" 33 "MDB1" 35 "MDB2" 39 "MDB3" 40 "MDB4" 41 "MDB5" 49 "MDB6" 50 "Track" 20 "CLU" ;
VAL_ 2 CANzero_NMT_State 1 "Start Remote Node" 2 "Stop Remote Node" 128 "Enter Pre-Operational" 129 "Reset" ;
VAL_ 129 SensorF_E14_fiducialHighOffset 0 "Ok" 1 "ERR" ;
VAL_ 129 SensorF_E13_encoderSpeedError 0 "Ok" 1 "ERR" ;
VAL_ 129 SensorF_E12_encoderError 0 "Ok" 1 "ERR" ;
VAL_ 129 SensorF_E10_TelemEmergency 0 "Ok" 1 "ERR" ;
VAL_ 129 SensorF_E9_SWError 0 "Ok" 1 "ERR" ;
VAL_ 129 SensorF_E8_NodeErrorFlag 0 "Ok" 1 "ERR" ;
VAL_ 129 SensorF_E7_TelemetryTimeout 0 "Ok" 1 "ERR" ;
VAL_ 129 SensorF_E6_SensorRTimeout 0 "Ok" 1 "ERR" ;
VAL_ 129 SensorF_E5_HVCUTimeout 0 "Ok" 1 "ERR" ;
VAL_ 129 SensorF_E4_PDUTimeout 0 "Ok" 1 "ERR" ;
VAL_ 129 SensorF_E3_BrakeRTimeout 0 "Ok" 1 "ERR" ;
VAL_ 129 SensorF_E2_BrakeFTimeout 0 "Ok" 1 "ERR" ;
VAL_ 129 SensorF_E1_StateMTransitionE 0 "Ok" 1 "ERR" ;
VAL_ 129 SensorF_E0_OtherError 0 "Ok" 1 "ERR" ;
VAL_ 129 SensorF_W2_encoderOORWarning 0 "Ok" 1 "WARN" ;
VAL_ 129 SensorF_W1_StateMTransitionW 0 "Ok" 1 "WARN" ;
VAL_ 129 SensorF_W0_OtherWarning 0 "Ok" 1 "WARN" ;
VAL_ 385 SensorF_TX_PodState_Target 7 "Pod Safe to Approach" 6 "Pod Pushable" 5 "Pod Launching" 4 "Pod Ready to Launch" 3 "Pod Fault" 2 "Pod Launch Preparation" 1 "Pod Idle" 0 "Pod Off" ;
VAL_ 385 SensorF_TX_PodState_Last 7 "Pod Safe to Approach" 6 "Pod Pushable" 5 "Pod Launching" 4 "Pod Ready to Launch" 3 "Pod Fault" 2 "Pod Launch Preparation" 1 "Pod Idle" 0 "Pod Off" ;
VAL_ 385 SensorF_TX_PodState 14 "Pod Startup" 13 "Pod Pushable" 12 "Pod Safe to Approch" 11 "Pod End Of Run" 10 "Pod Engage Brakes" 9 "Pod Rolling" 8 "Pod Stop Levitation" 7 "Pod Disengage Brakes" 6 "Pod Crusing" 5 "Pod Stable Levitation" 4 "Pod Start Levitation" 3 "Pod Ready to Launch" 2 "Pod Launch Preparation" 1 "Pod Idle" 0 "Pod Off" ;
VAL_ 513 SensorF_TX_PreopHVCUT 1 "Transition" 0 "No Transitions" ;
VAL_ 513 SensorF_TX_PreopPDUT 1 "Transition" 0 "No Transitions" ;
VAL_ 513 SensorF_TX_PreopBrakeRT 1 "Transition" 0 "No Transitions" ;
VAL_ 513 SensorF_TX_PreopBrakeFT 1 "Transition" 0 "No Transitions" ;
VAL_ 513 SensorF_TX_PreopSensorRT 1 "Transition" 0 "No Transitions" ;
VAL_ 513 SensorF_TX_EnableSensorRT 1 "Transition" 0 "No Transitions" ;
VAL_ 513 SensorF_TX_EnablePDUT 1 "Transition" 0 "No Transitions" ;
VAL_ 513 SensorF_TX_EnableHVCUT 1 "Transition" 0 "No Transitions" ;
VAL_ 513 SensorF_TX_EnableBrakeRT 1 "Transition" 0 "No Transitions" ;
VAL_ 513 SensorF_TX_EnableBrakeFT 1 "Transition" 0 "No Transitions" ;
VAL_ 513 SensorF_TX_SetHVTransition 1 "Transition" 0 "No Transitions" ;
VAL_ 513 SensorF_TX_PreopTransition 1 "Transition" 0 "No Transitions" ;
VAL_ 513 SensorF_TX_LaunchStartTransition 1 "Transition" 0 "No Transitions" ;
VAL_ 513 SensorF_TX_LaunchSetupTransition 1 "Transition" 0 "No Transitions" ;
VAL_ 513 SensorF_TX_HWEnableTransition 1 "Transition" 0 "No Transitions" ;
VAL_ 513 SensorF_TX_ErrorResetTransition 1 "Transition" 0 "No Transitions" ;
VAL_ 513 SensorF_TX_EnableTransition 1 "Transition" 0 "No Transitions" ;
VAL_ 513 SensorF_TX_BrakesTransition 1 "Transition" 0 "No Transitions" ;
VAL_ 1409 SensorF_OD_SetReset 0 "None" 1 "Reset" ;
VAL_ 1409 SensorF_OD_MdbState 0 "precharge" 1 "levitaiton" 2 "grounded" 3 "save_to_approch" 4 "precharge_done" 255 "inconsistant" ;
VAL_ 1409 SensorF_OD_EncoderResetPosition 0 "None" 1 "Reset" ;
VAL_ 1409 SensorF_OD_HVBatteryMode 0 "Discharging" 1 "Charging" ;
VAL_ 1409 SensorF_OD_StateMachineActivate 0 "Activate" 1 "Deactivate" ;
VAL_ 1409 SensorF_OD_TelemetryCommands 0 "None" 1 "Launch Preparation" 2 "HV Activation" 3 "Pushing Start" 4 "Pushing End" 5 "Launch Start" 6 "Launch Abort" 7 "Idle" 8 "Error Resolved" 9 "Emergency" ;
VAL_ 1409 SensorF_OD_CAN2_ErrorStatus 0 "Ok" 1 "Warn" 2 "Error Passive" 3 "Bus Off" ;
VAL_ 1409 SensorF_OD_CAN2_Status 0 "Reset" 1 "Ready" 2 "Listening" 3 "Sleep_Pending" 4 "Sleep_Active" 5 "ERROR" ;
VAL_ 1409 SensorF_OD_CAN2_autoErrorReset 0 "Disabled" 1 "Enabled" ;
VAL_ 1409 SensorF_OD_CAN2_lastErrorCode 0 "No Error" 1 "Stuff Error" 2 "Form Error" 3 "Ack Error" 4 "Bit recessive Error" 5 "Bit dominant Error" 6 "CRC Error" ;
VAL_ 1409 SensorF_OD_CAN1_ErrorStatus 0 "Ok" 1 "Warn" 2 "Error Passive" 3 "Bus Off" ;
VAL_ 1409 SensorF_OD_CAN1_Status 0 "Reset" 1 "Ready" 2 "Listening" 3 "Sleep_Pending" 4 "Sleep_Active" 5 "ERROR" ;
VAL_ 1409 SensorF_OD_CAN1_autoErrorReset 0 "Disabled" 1 "Enabled" ;
VAL_ 1409 SensorF_OD_CAN1_lastErrorCode 0 "No Error" 1 "Stuff Error" 2 "Form Error" 3 "Ack Error" 4 "Bit recessive Error" 5 "Bit dominant Error" 6 "CRC Error" ;
VAL_ 1409 SensorF_OD_SendOdOnBootup 0 "Disabled" 1 "Enabled" ;
VAL_ 1409 SensorF_OD_NodeStatus 0 "Bootup" 4 "Stopped" 5 "Operational" 127 "Pre-Operational" 128 "Reset" ;
VAL_ 1409 SensorF_SDO_RespCode 5 "ERR: Out of range" 4 "ERR: No access in this state" 3 "ERR: Read only object" 2 "ERR: Write only object" 1 "ERR: Non existing object" 0 "OK" ;
VAL_ 1409 SensorF_SDO_ID 0 "Reserved" 1 "NodeID" 2 "NodeStatus" 3 "ProtocolVersion" 4 "StackVersion" 5 "DbcVersion" 16 "HeartbeatInterval" 32 "SendOdOnBootup" 33 "OdEntrySendInterval" 1040 "CpuUsage" 1041 "MemFree" 1042 "BoardTemp" 1043 "InputVoltage" 1044 "runtime" 1045 "SdcIn" 1046 "SdcOut" 1056 "ChipUID1" 1057 "ChipUID2" 1072 "BuildDate" 1073 "BuildTime" 1104 "CAN1_TxErrCnt" 1105 "CAN1_RxErrCnt" 1106 "CAN1_lastErrorCode" 1107 "CAN1_autoErrorReset" 1108 "CAN1_Baudrate" 1110 "CAN1_Status" 1111 "CAN1_DiscardedTxMessages" 1112 "CAN1_ErrorStatus" 1113 "CAN1_DelayedTxMessages" 1120 "CAN2_TxErrCnt" 1121 "CAN2_RxErrCnt" 1122 "CAN2_lastErrorCode" 1123 "CAN2_autoErrorReset" 1124 "CAN2_Baudrate" 1126 "CAN2_Status" 1127 "CAN2_DiscardedTxMessages" 1128 "CAN2_ErrorStatus" 1129 "CAN2_DelayedTxMessages" 2048 "samplingInterval" 2304 "TelemetryCommands" 2305 "StateMachineInterval" 2306 "StateMachineActivate" 2307 "HVBatteryMode" 2308 "EncoderWheelDiameter" 2309 "EncoderResetPosition" 2592 "IMU_number" 2597 "IMU1_Temperature" 2598 "IMU2_Temperature" 2599 "IMU3_Temperature" 2600 "IMU_AccelX" 2601 "IMU_AccelY" 2608 "IMU_AccelZ" 2609 "IMU_GyroX" 2610 "IMU_GyroY" 2611 "IMU_GyroZ" 2816 "CoolingPressure" 2817 "ReservoirTemperature" 2818 "Magnet_1_Temperature" 2820 "Magnet_2_Temperature" 2821 "Magnet_3_Temperature" 2822 "Magnet_4_Temperature" 2823 "Magnet_5_Temperature" 2824 "Magnet_6_Temperature" 2832 "MdbState" 3072 "StripeCount" 3328 "Position" 3329 "Velocity" 2320 "SetReset" ;
VAL_ 1473 SensorF_OD_SetReset 0 "None" 1 "Reset" ;
VAL_ 1473 SensorF_OD_MdbState 0 "precharge" 1 "levitaiton" 2 "grounded" 3 "save_to_approch" 4 "precharge_done" 255 "inconsistant" ;
VAL_ 1473 SensorF_OD_EncoderResetPosition 0 "None" 1 "Reset" ;
VAL_ 1473 SensorF_OD_HVBatteryMode 0 "Discharging" 1 "Charging" ;
VAL_ 1473 SensorF_OD_StateMachineActivate 0 "Activate" 1 "Deactivate" ;
VAL_ 1473 SensorF_OD_TelemetryCommands 0 "None" 1 "Launch Preparation" 2 "HV Activation" 3 "Pushing Start" 4 "Pushing End" 5 "Launch Start" 6 "Launch Abort" 7 "Idle" 8 "Error Resolved" 9 "Emergency" ;
VAL_ 1473 SensorF_OD_CAN2_ErrorStatus 0 "Ok" 1 "Warn" 2 "Error Passive" 3 "Bus Off" ;
VAL_ 1473 SensorF_OD_CAN2_Status 0 "Reset" 1 "Ready" 2 "Listening" 3 "Sleep_Pending" 4 "Sleep_Active" 5 "ERROR" ;
VAL_ 1473 SensorF_OD_CAN2_autoErrorReset 0 "Disabled" 1 "Enabled" ;
VAL_ 1473 SensorF_OD_CAN2_lastErrorCode 0 "No Error" 1 "Stuff Error" 2 "Form Error" 3 "Ack Error" 4 "Bit recessive Error" 5 "Bit dominant Error" 6 "CRC Error" ;
VAL_ 1473 SensorF_OD_CAN1_ErrorStatus 0 "Ok" 1 "Warn" 2 "Error Passive" 3 "Bus Off" ;
VAL_ 1473 SensorF_OD_CAN1_Status 0 "Reset" 1 "Ready" 2 "Listening" 3 "Sleep_Pending" 4 "Sleep_Active" 5 "ERROR" ;
VAL_ 1473 SensorF_OD_CAN1_autoErrorReset 0 "Disabled" 1 "Enabled" ;
VAL_ 1473 SensorF_OD_CAN1_lastErrorCode 0 "No Error" 1 "Stuff Error" 2 "Form Error" 3 "Ack Error" 4 "Bit recessive Error" 5 "Bit dominant Error" 6 "CRC Error" ;
VAL_ 1473 SensorF_OD_SendOdOnBootup 0 "Disabled" 1 "Enabled" ;
VAL_ 1473 SensorF_OD_NodeStatus 0 "Bootup" 4 "Stopped" 5 "Operational" 127 "Pre-Operational" 128 "Reset" ;
VAL_ 1473 SensorF_SDO_ID 0 "Reserved" 1 "NodeID" 2 "NodeStatus" 3 "ProtocolVersion" 4 "StackVersion" 5 "DbcVersion" 16 "HeartbeatInterval" 32 "SendOdOnBootup" 33 "OdEntrySendInterval" 1040 "CpuUsage" 1041 "MemFree" 1042 "BoardTemp" 1043 "InputVoltage" 1044 "runtime" 1045 "SdcIn" 1046 "SdcOut" 1056 "ChipUID1" 1057 "ChipUID2" 1072 "BuildDate" 1073 "BuildTime" 1104 "CAN1_TxErrCnt" 1105 "CAN1_RxErrCnt" 1106 "CAN1_lastErrorCode" 1107 "CAN1_autoErrorReset" 1108 "CAN1_Baudrate" 1110 "CAN1_Status" 1111 "CAN1_DiscardedTxMessages" 1112 "CAN1_ErrorStatus" 1113 "CAN1_DelayedTxMessages" 1120 "CAN2_TxErrCnt" 1121 "CAN2_RxErrCnt" 1122 "CAN2_lastErrorCode" 1123 "CAN2_autoErrorReset" 1124 "CAN2_Baudrate" 1126 "CAN2_Status" 1127 "CAN2_DiscardedTxMessages" 1128 "CAN2_ErrorStatus" 1129 "CAN2_DelayedTxMessages" 2048 "samplingInterval" 2304 "TelemetryCommands" 2305 "StateMachineInterval" 2306 "StateMachineActivate" 2307 "HVBatteryMode" 2308 "EncoderWheelDiameter" 2309 "EncoderResetPosition" 2592 "IMU_number" 2597 "IMU1_Temperature" 2598 "IMU2_Temperature" 2599 "IMU3_Temperature" 2600 "IMU_AccelX" 2601 "IMU_AccelY" 2608 "IMU_AccelZ" 2609 "IMU_GyroX" 2610 "IMU_GyroY" 2611 "IMU_GyroZ" 2816 "CoolingPressure" 2817 "ReservoirTemperature" 2818 "Magnet_1_Temperature" 2820 "Magnet_2_Temperature" 2821 "Magnet_3_Temperature" 2822 "Magnet_4_Temperature" 2823 "Magnet_5_Temperature" 2824 "Magnet_6_Temperature" 2832 "MdbState" 3072 "StripeCount" 3328 "Position" 3329 "Velocity" 2320 "SetReset" ;
VAL_ 1537 SensorF_SDO_ID 0 "Reserved" 1 "NodeID" 2 "NodeStatus" 3 "ProtocolVersion" 4 "StackVersion" 5 "DbcVersion" 16 "HeartbeatInterval" 32 "SendOdOnBootup" 33 "OdEntrySendInterval" 1040 "CpuUsage" 1041 "MemFree" 1042 "BoardTemp" 1043 "InputVoltage" 1044 "runtime" 1045 "SdcIn" 1046 "SdcOut" 1056 "ChipUID1" 1057 "ChipUID2" 1072 "BuildDate" 1073 "BuildTime" 1104 "CAN1_TxErrCnt" 1105 "CAN1_RxErrCnt" 1106 "CAN1_lastErrorCode" 1107 "CAN1_autoErrorReset" 1108 "CAN1_Baudrate" 1110 "CAN1_Status" 1111 "CAN1_DiscardedTxMessages" 1112 "CAN1_ErrorStatus" 1113 "CAN1_DelayedTxMessages" 1120 "CAN2_TxErrCnt" 1121 "CAN2_RxErrCnt" 1122 "CAN2_lastErrorCode" 1123 "CAN2_autoErrorReset" 1124 "CAN2_Baudrate" 1126 "CAN2_Status" 1127 "CAN2_DiscardedTxMessages" 1128 "CAN2_ErrorStatus" 1129 "CAN2_DelayedTxMessages" 2048 "samplingInterval" 2304 "TelemetryCommands" 2305 "StateMachineInterval" 2306 "StateMachineActivate" 2307 "HVBatteryMode" 2308 "EncoderWheelDiameter" 2309 "EncoderResetPosition" 2592 "IMU_number" 2597 "IMU1_Temperature" 2598 "IMU2_Temperature" 2599 "IMU3_Temperature" 2600 "IMU_AccelX" 2601 "IMU_AccelY" 2608 "IMU_AccelZ" 2609 "IMU_GyroX" 2610 "IMU_GyroY" 2611 "IMU_GyroZ" 2816 "CoolingPressure" 2817 "ReservoirTemperature" 2818 "Magnet_1_Temperature" 2820 "Magnet_2_Temperature" 2821 "Magnet_3_Temperature" 2822 "Magnet_4_Temperature" 2823 "Magnet_5_Temperature" 2824 "Magnet_6_Temperature" 2832 "MdbState" 3072 "StripeCount" 3328 "Position" 3329 "Velocity" 2320 "SetReset" ;
VAL_ 1793 SensorF_NodeState 0 "Bootup" 4 "Stopped" 5 "Operational" 127 "Pre-Operational" ;
VAL_ 130 SensorR_E12_highLIMTemperature 0 "Ok" 1 "ERR" ;
VAL_ 130 SensorR_E11_scimoPEerror101overc 0 "Ok" 1 "ERR" ;
VAL_ 130 SensorR_E10_scimoPEerror103sumcu 0 "Ok" 1 "ERR" ;
VAL_ 130 SensorR_E9_scimoPEerror102overcu 0 "Ok" 1 "ERR" ;
VAL_ 130 SensorR_E8_scimoPEerror024motTem 0 "Ok" 1 "ERR" ;
VAL_ 130 SensorR_E7_scimoPEerror020uZKmin 0 "Ok" 1 "ERR" ;
VAL_ 130 SensorR_E6_scimoPEerror009Pulslo 0 "Ok" 1 "ERR" ;
VAL_ 130 SensorR_E5_accEmergencyStop 0 "Ok" 1 "ERR" ;
VAL_ 130 SensorR_E4_velEmergencyStop 0 "Ok" 1 "ERR" ;
VAL_ 130 SensorR_E3_posEmergencyStop 0 "Ok" 1 "ERR" ;
VAL_ 130 SensorR_E2_stripeEmergencyStop 0 "Ok" 1 "ERR" ;
VAL_ 130 SensorR_E1_trajectoryError 0 "Ok" 1 "ERR" ;
VAL_ 130 SensorR_E0_OtherError 0 "Ok" 1 "ERR" ;
VAL_ 130 SensorR_W10_highLIMTemperature 0 "Ok" 1 "WARN" ;
VAL_ 130 SensorR_W9_restrictingVelocity 0 "Ok" 1 "WARN" ;
VAL_ 130 SensorR_W8_outOfLimModelBoundari 0 "Ok" 1 "WARN" ;
VAL_ 130 SensorR_W7_highOscillations 0 "Ok" 1 "WARN" ;
VAL_ 130 SensorR_W6_sciMoPEwarning104FETt 0 "Ok" 1 "WARN" ;
VAL_ 130 SensorR_W5_sciMoPEwarning069CPUt 0 "Ok" 1 "WARN" ;
VAL_ 130 SensorR_W4_stateEstimationAccWar 0 "Ok" 1 "WARN" ;
VAL_ 130 SensorR_W3_stateEstimationPosWar 0 "Ok" 1 "WARN" ;
VAL_ 130 SensorR_W2_stateEstimationVelWar 0 "Ok" 1 "WARN" ;
VAL_ 130 SensorR_W1_stripeWarning 0 "Ok" 1 "WARN" ;
VAL_ 130 SensorR_W0_OtherWarning 0 "Ok" 1 "WARN" ;
VAL_ 514 SensorR_TX_ErrorFlag 1 "Error" 0 "No Error" ;
VAL_ 514 SensorR_TX_Enabled 1 "Enabled" 0 "Disabled" ;
VAL_ 514 SensorR_TX_TrajectorySet 2 "Invalid set" 1 "Set" 0 "Not set" ;
VAL_ 514 SensorR_TX_RunState 4 "Idle not ready" 3 "Launch Abort" 2 "Finished" 1 "Ready to Launch" 0 "Launching" ;
VAL_ 706 SensorR_RX_ErrorReset 1 "Reset" 0 "No Reset" ;
VAL_ 706 SensorR_RX_Enable 1 "Enable" 0 "Disable" ;
VAL_ 706 SensorR_RX_LaunchComm 2 "No Start" 1 "Abort Launch" 0 "Start Launch" ;
VAL_ 1410 SensorR_OD_StripeMode 0 "Left" 1 "Right" 2 "Both" ;
VAL_ 1410 SensorR_OD_opc_brakeFlag 0 "None" 1 "Braked" ;
VAL_ 1410 SensorR_OD_AdaptModelByCurrent 0 "Const" 1 "UseCurrent" ;
VAL_ 1410 SensorR_OD_VelocityController 0 "CC" 1 "CVFF" 2 "CVFB" 3 "CAS" 4 "FAST" ;
VAL_ 1410 SensorR_OD_SetFinish 0 "None" 1 "Finish" ;
VAL_ 1410 SensorR_OD_RunMode 0 "Dynamic" 1 "Levitation" 2 "Manual" ;
VAL_ 1410 SensorR_OD_EncoderResetPosition 0 "None" 1 "Reset" ;
VAL_ 1410 SensorR_OD_CAN2_ErrorStatus 0 "Ok" 1 "Warn" 2 "Error Passive" 3 "Bus Off" ;
VAL_ 1410 SensorR_OD_CAN2_Status 0 "Reset" 1 "Ready" 2 "Listening" 3 "Sleep_Pending" 4 "Sleep_Active" 5 "ERROR" ;
VAL_ 1410 SensorR_OD_CAN2_autoErrorReset 0 "Disabled" 1 "Enabled" ;
VAL_ 1410 SensorR_OD_CAN2_lastErrorCode 0 "No Error" 1 "Stuff Error" 2 "Form Error" 3 "Ack Error" 4 "Bit recessive Error" 5 "Bit dominant Error" 6 "CRC Error" ;
VAL_ 1410 SensorR_OD_CAN1_ErrorStatus 0 "Ok" 1 "Warn" 2 "Error Passive" 3 "Bus Off" ;
VAL_ 1410 SensorR_OD_CAN1_Status 0 "Reset" 1 "Ready" 2 "Listening" 3 "Sleep_Pending" 4 "Sleep_Active" 5 "ERROR" ;
VAL_ 1410 SensorR_OD_CAN1_autoErrorReset 0 "Disabled" 1 "Enabled" ;
VAL_ 1410 SensorR_OD_CAN1_lastErrorCode 0 "No Error" 1 "Stuff Error" 2 "Form Error" 3 "Ack Error" 4 "Bit recessive Error" 5 "Bit dominant Error" 6 "CRC Error" ;
VAL_ 1410 SensorR_OD_SendOdOnBootup 0 "Disabled" 1 "Enabled" ;
VAL_ 1410 SensorR_OD_NodeStatus 0 "Bootup" 4 "Stopped" 5 "Operational" 127 "Pre-Operational" 128 "Reset" ;
VAL_ 1410 SensorR_SDO_RespCode 5 "ERR: Out of range" 4 "ERR: No access in this state" 3 "ERR: Read only object" 2 "ERR: Write only object" 1 "ERR: Non existing object" 0 "OK" ;
VAL_ 1410 SensorR_SDO_ID 0 "Reserved" 1 "NodeID" 2 "NodeStatus" 3 "ProtocolVersion" 4 "StackVersion" 5 "DbcVersion" 16 "HeartbeatInterval" 32 "SendOdOnBootup" 33 "OdEntrySendInterval" 1040 "CpuUsage" 1041 "MemFree" 1042 "BoardTemp" 1043 "InputVoltage" 1044 "runtime" 1045 "SdcIn" 1046 "SdcOut" 1056 "ChipUID1" 1057 "ChipUID2" 1072 "BuildDate" 1073 "BuildTime" 1104 "CAN1_TxErrCnt" 1105 "CAN1_RxErrCnt" 1106 "CAN1_lastErrorCode" 1107 "CAN1_autoErrorReset" 1108 "CAN1_Baudrate" 1110 "CAN1_Status" 1111 "CAN1_DiscardedTxMessages" 1112 "CAN1_ErrorStatus" 1113 "CAN1_DelayedTxMessages" 1120 "CAN2_TxErrCnt" 1121 "CAN2_RxErrCnt" 1122 "CAN2_lastErrorCode" 1123 "CAN2_autoErrorReset" 1124 "CAN2_Baudrate" 1126 "CAN2_Status" 1127 "CAN2_DiscardedTxMessages" 1128 "CAN2_ErrorStatus" 1129 "CAN2_DelayedTxMessages" 2048 "samplingInterval" 2576 "EncoderWheelDiameter" 2586 "EncoderResetPosition" 2592 "IMU_number" 2597 "IMU1_Temperature" 2598 "IMU2_Temperature" 2599 "IMU3_Temperature" 2608 "ExecTimeOverall" 2609 "ExecTimeStateEst" 2610 "ExecTimeControl" 2611 "ExecTimeReadSensors" 2624 "OpcKp" 2625 "OpcKi" 2626 "CtrlMode" 2627 "CurrentReq" 2628 "PodMass" 2629 "FmaxCtrl" 2630 "FminCtrl" 2631 "MaxCtrlError" 2632 "MaxCtrlErrorDuration" 2633 "WarningThreshholdForLimModelOutOfBoundaries" 2634 "MaxRequiredVelocity" 2635 "VdcReduceFactor" 2636 "RunMode" 2637 "SetFinish" 2816 "RunProfile_T0" 2817 "RunProfile_V0" 2818 "RunProfile_T1" 2819 "RunProfile_V1" 2820 "RunProfile_T2" 2821 "RunProfile_V2" 2822 "RunProfile_T3" 2823 "RunProfile_V3" 2824 "RunProfile_T4" 2825 "RunProfile_V4" 2826 "EstimatedRunLength" 3072 "TC_I" 3073 "TC_f" 3074 "VelocityController" 3075 "CVOPCImax" 3076 "CVOPCTcf" 3077 "CVOPCTcI" 3078 "CVOPCSmoothingDeltaVelocity" 3079 "CVOPCDeltaVelHigherCurrent" 3080 "CVOPCReduceCurrentWhileCruising" 3081 "CVOPCHystereseF" 3088 "AccAtCurrentMeasured" 3089 "CurrentForConstantVelocity" 3090 "CascadedMaxSetForceDelta" 3091 "CascadedFreqCurUpdate" 3092 "CascadedKpIncreaseCurrent" 3093 "CascadedKpDecreaseCurrent" 3094 "CVOPCImin" 3095 "CVOPCTcFreq" 3096 "AdaptModelByCurrent" 3097 "Current4Stopping" 3104 "FinishedDelay" 3105 "maxRunDistance" 3106 "opc_ratelimiter_f" 3107 "DebugCascadedIreq" 3108 "DebugCVOPCfreq" 3109 "opc_brakeFlag" 3110 "opc_t_run_max" 3111 "opc_F_max" 3112 "opc_T_acc" 3113 "opc_v_max" 3120 "opc_v_threshold" 3121 "opc_F_decrease" 3122 "opc_lowpass_Tcf" 3123 "opc_lowpass_TcI" 3329 "StripeMode" 3330 "ReflectorDistance" 3331 "PositionGlitch" 3332 "EnableSignalGeneration" 3585 "accDeviation" 3586 "velDeviationEncoder" 3587 "velDeviationOptic" 3588 "posDeviationEncoder" 3589 "posDeviationOptic" ;
VAL_ 1474 SensorR_OD_StripeMode 0 "Left" 1 "Right" 2 "Both" ;
VAL_ 1474 SensorR_OD_opc_brakeFlag 0 "None" 1 "Braked" ;
VAL_ 1474 SensorR_OD_AdaptModelByCurrent 0 "Const" 1 "UseCurrent" ;
VAL_ 1474 SensorR_OD_VelocityController 0 "CC" 1 "CVFF" 2 "CVFB" 3 "CAS" 4 "FAST" ;
VAL_ 1474 SensorR_OD_SetFinish 0 "None" 1 "Finish" ;
VAL_ 1474 SensorR_OD_RunMode 0 "Dynamic" 1 "Levitation" 2 "Manual" ;
VAL_ 1474 SensorR_OD_EncoderResetPosition 0 "None" 1 "Reset" ;
VAL_ 1474 SensorR_OD_CAN2_ErrorStatus 0 "Ok" 1 "Warn" 2 "Error Passive" 3 "Bus Off" ;
VAL_ 1474 SensorR_OD_CAN2_Status 0 "Reset" 1 "Ready" 2 "Listening" 3 "Sleep_Pending" 4 "Sleep_Active" 5 "ERROR" ;
VAL_ 1474 SensorR_OD_CAN2_autoErrorReset 0 "Disabled" 1 "Enabled" ;
VAL_ 1474 SensorR_OD_CAN2_lastErrorCode 0 "No Error" 1 "Stuff Error" 2 "Form Error" 3 "Ack Error" 4 "Bit recessive Error" 5 "Bit dominant Error" 6 "CRC Error" ;
VAL_ 1474 SensorR_OD_CAN1_ErrorStatus 0 "Ok" 1 "Warn" 2 "Error Passive" 3 "Bus Off" ;
VAL_ 1474 SensorR_OD_CAN1_Status 0 "Reset" 1 "Ready" 2 "Listening" 3 "Sleep_Pending" 4 "Sleep_Active" 5 "ERROR" ;
VAL_ 1474 SensorR_OD_CAN1_autoErrorReset 0 "Disabled" 1 "Enabled" ;
VAL_ 1474 SensorR_OD_CAN1_lastErrorCode 0 "No Error" 1 "Stuff Error" 2 "Form Error" 3 "Ack Error" 4 "Bit recessive Error" 5 "Bit dominant Error" 6 "CRC Error" ;
VAL_ 1474 SensorR_OD_SendOdOnBootup 0 "Disabled" 1 "Enabled" ;
VAL_ 1474 SensorR_OD_NodeStatus 0 "Bootup" 4 "Stopped" 5 "Operational" 127 "Pre-Operational" 128 "Reset" ;
VAL_ 1474 SensorR_SDO_ID 0 "Reserved" 1 "NodeID" 2 "NodeStatus" 3 "ProtocolVersion" 4 "StackVersion" 5 "DbcVersion" 16 "HeartbeatInterval" 32 "SendOdOnBootup" 33 "OdEntrySendInterval" 1040 "CpuUsage" 1041 "MemFree" 1042 "BoardTemp" 1043 "InputVoltage" 1044 "runtime" 1045 "SdcIn" 1046 "SdcOut" 1056 "ChipUID1" 1057 "ChipUID2" 1072 "BuildDate" 1073 "BuildTime" 1104 "CAN1_TxErrCnt" 1105 "CAN1_RxErrCnt" 1106 "CAN1_lastErrorCode" 1107 "CAN1_autoErrorReset" 1108 "CAN1_Baudrate" 1110 "CAN1_Status" 1111 "CAN1_DiscardedTxMessages" 1112 "CAN1_ErrorStatus" 1113 "CAN1_DelayedTxMessages" 1120 "CAN2_TxErrCnt" 1121 "CAN2_RxErrCnt" 1122 "CAN2_lastErrorCode" 1123 "CAN2_autoErrorReset" 1124 "CAN2_Baudrate" 1126 "CAN2_Status" 1127 "CAN2_DiscardedTxMessages" 1128 "CAN2_ErrorStatus" 1129 "CAN2_DelayedTxMessages" 2048 "samplingInterval" 2576 "EncoderWheelDiameter" 2586 "EncoderResetPosition" 2592 "IMU_number" 2597 "IMU1_Temperature" 2598 "IMU2_Temperature" 2599 "IMU3_Temperature" 2608 "ExecTimeOverall" 2609 "ExecTimeStateEst" 2610 "ExecTimeControl" 2611 "ExecTimeReadSensors" 2624 "OpcKp" 2625 "OpcKi" 2626 "CtrlMode" 2627 "CurrentReq" 2628 "PodMass" 2629 "FmaxCtrl" 2630 "FminCtrl" 2631 "MaxCtrlError" 2632 "MaxCtrlErrorDuration" 2633 "WarningThreshholdForLimModelOutOfBoundaries" 2634 "MaxRequiredVelocity" 2635 "VdcReduceFactor" 2636 "RunMode" 2637 "SetFinish" 2816 "RunProfile_T0" 2817 "RunProfile_V0" 2818 "RunProfile_T1" 2819 "RunProfile_V1" 2820 "RunProfile_T2" 2821 "RunProfile_V2" 2822 "RunProfile_T3" 2823 "RunProfile_V3" 2824 "RunProfile_T4" 2825 "RunProfile_V4" 2826 "EstimatedRunLength" 3072 "TC_I" 3073 "TC_f" 3074 "VelocityController" 3075 "CVOPCImax" 3076 "CVOPCTcf" 3077 "CVOPCTcI" 3078 "CVOPCSmoothingDeltaVelocity" 3079 "CVOPCDeltaVelHigherCurrent" 3080 "CVOPCReduceCurrentWhileCruising" 3081 "CVOPCHystereseF" 3088 "AccAtCurrentMeasured" 3089 "CurrentForConstantVelocity" 3090 "CascadedMaxSetForceDelta" 3091 "CascadedFreqCurUpdate" 3092 "CascadedKpIncreaseCurrent" 3093 "CascadedKpDecreaseCurrent" 3094 "CVOPCImin" 3095 "CVOPCTcFreq" 3096 "AdaptModelByCurrent" 3097 "Current4Stopping" 3104 "FinishedDelay" 3105 "maxRunDistance" 3106 "opc_ratelimiter_f" 3107 "DebugCascadedIreq" 3108 "DebugCVOPCfreq" 3109 "opc_brakeFlag" 3110 "opc_t_run_max" 3111 "opc_F_max" 3112 "opc_T_acc" 3113 "opc_v_max" 3120 "opc_v_threshold" 3121 "opc_F_decrease" 3122 "opc_lowpass_Tcf" 3123 "opc_lowpass_TcI" 3329 "StripeMode" 3330 "ReflectorDistance" 3331 "PositionGlitch" 3332 "EnableSignalGeneration" 3585 "accDeviation" 3586 "velDeviationEncoder" 3587 "velDeviationOptic" 3588 "posDeviationEncoder" 3589 "posDeviationOptic" ;
VAL_ 1538 SensorR_SDO_ID 0 "Reserved" 1 "NodeID" 2 "NodeStatus" 3 "ProtocolVersion" 4 "StackVersion" 5 "DbcVersion" 16 "HeartbeatInterval" 32 "SendOdOnBootup" 33 "OdEntrySendInterval" 1040 "CpuUsage" 1041 "MemFree" 1042 "BoardTemp" 1043 "InputVoltage" 1044 "runtime" 1045 "SdcIn" 1046 "SdcOut" 1056 "ChipUID1" 1057 "ChipUID2" 1072 "BuildDate" 1073 "BuildTime" 1104 "CAN1_TxErrCnt" 1105 "CAN1_RxErrCnt" 1106 "CAN1_lastErrorCode" 1107 "CAN1_autoErrorReset" 1108 "CAN1_Baudrate" 1110 "CAN1_Status" 1111 "CAN1_DiscardedTxMessages" 1112 "CAN1_ErrorStatus" 1113 "CAN1_DelayedTxMessages" 1120 "CAN2_TxErrCnt" 1121 "CAN2_RxErrCnt" 1122 "CAN2_lastErrorCode" 1123 "CAN2_autoErrorReset" 1124 "CAN2_Baudrate" 1126 "CAN2_Status" 1127 "CAN2_DiscardedTxMessages" 1128 "CAN2_ErrorStatus" 1129 "CAN2_DelayedTxMessages" 2048 "samplingInterval" 2576 "EncoderWheelDiameter" 2586 "EncoderResetPosition" 2592 "IMU_number" 2597 "IMU1_Temperature" 2598 "IMU2_Temperature" 2599 "IMU3_Temperature" 2608 "ExecTimeOverall" 2609 "ExecTimeStateEst" 2610 "ExecTimeControl" 2611 "ExecTimeReadSensors" 2624 "OpcKp" 2625 "OpcKi" 2626 "CtrlMode" 2627 "CurrentReq" 2628 "PodMass" 2629 "FmaxCtrl" 2630 "FminCtrl" 2631 "MaxCtrlError" 2632 "MaxCtrlErrorDuration" 2633 "WarningThreshholdForLimModelOutOfBoundaries" 2634 "MaxRequiredVelocity" 2635 "VdcReduceFactor" 2636 "RunMode" 2637 "SetFinish" 2816 "RunProfile_T0" 2817 "RunProfile_V0" 2818 "RunProfile_T1" 2819 "RunProfile_V1" 2820 "RunProfile_T2" 2821 "RunProfile_V2" 2822 "RunProfile_T3" 2823 "RunProfile_V3" 2824 "RunProfile_T4" 2825 "RunProfile_V4" 2826 "EstimatedRunLength" 3072 "TC_I" 3073 "TC_f" 3074 "VelocityController" 3075 "CVOPCImax" 3076 "CVOPCTcf" 3077 "CVOPCTcI" 3078 "CVOPCSmoothingDeltaVelocity" 3079 "CVOPCDeltaVelHigherCurrent" 3080 "CVOPCReduceCurrentWhileCruising" 3081 "CVOPCHystereseF" 3088 "AccAtCurrentMeasured" 3089 "CurrentForConstantVelocity" 3090 "CascadedMaxSetForceDelta" 3091 "CascadedFreqCurUpdate" 3092 "CascadedKpIncreaseCurrent" 3093 "CascadedKpDecreaseCurrent" 3094 "CVOPCImin" 3095 "CVOPCTcFreq" 3096 "AdaptModelByCurrent" 3097 "Current4Stopping" 3104 "FinishedDelay" 3105 "maxRunDistance" 3106 "opc_ratelimiter_f" 3107 "DebugCascadedIreq" 3108 "DebugCVOPCfreq" 3109 "opc_brakeFlag" 3110 "opc_t_run_max" 3111 "opc_F_max" 3112 "opc_T_acc" 3113 "opc_v_max" 3120 "opc_v_threshold" 3121 "opc_F_decrease" 3122 "opc_lowpass_Tcf" 3123 "opc_lowpass_TcI" 3329 "StripeMode" 3330 "ReflectorDistance" 3331 "PositionGlitch" 3332 "EnableSignalGeneration" 3585 "accDeviation" 3586 "velDeviationEncoder" 3587 "velDeviationOptic" 3588 "posDeviationEncoder" 3589 "posDeviationOptic" ;
VAL_ 1794 SensorR_NodeState 0 "Bootup" 4 "Stopped" 5 "Operational" 127 "Pre-Operational" ;
VAL_ 145 BrakeF_E5_retractUnsuccesful_ope 0 "Ok" 1 "ERR" ;
VAL_ 145 BrakeF_E4_retractUnsuccesful_not 0 "Ok" 1 "ERR" ;
VAL_ 145 BrakeF_E3_retractUnsuccesful_err 0 "Ok" 1 "ERR" ;
VAL_ 145 BrakeF_E2_commWatchdogTimeout 0 "Ok" 1 "ERR" ;
VAL_ 145 BrakeF_E1_pressureTooLow 0 "Ok" 1 "ERR" ;
VAL_ 145 BrakeF_E0_pressureTooHigh 0 "Ok" 1 "ERR" ;
VAL_ 145 BrakeF_W3_externalError 0 "Ok" 1 "WARN" ;
VAL_ 145 BrakeF_W2_enableWithAnError 0 "Ok" 1 "WARN" ;
VAL_ 145 BrakeF_W1_highPressureRetracting 0 "Ok" 1 "WARN" ;
VAL_ 145 BrakeF_W0_highPressureActingCham 0 "Ok" 1 "WARN" ;
